VERSION ""

NS_ :

BS_:

BU_: AC_KanBox DRS_MM5_10 NotUsed HYS_EX ABS_M5 DDU10 BCM BSM CDCM DCTM DIAG_TEST ECM IONM IPC ORC RFHM TBM
VAL_TABLE_ ABS_fault_info 2 "active faults stored" 1 "inactive faults stored" 0 "no faults stored" ;
VAL_TABLE_ AC_Mode 170 "HVAC_system" 10 "HV_system" 0 "UnrecognizedCommand" ;
VAL_TABLE_ VT_ACAutoManu 3 "Not available" 2 "AutoMode" 1 "Manual Mode" 0 "UnknownState" ;
VAL_TABLE_ Vt_AC_State 3 "Not available" 2 "ON" 1 "OFF" 0 "Unknown state" ;
VAL_TABLE_ HYS_errCod 3 "SBC over temperature" 2 "CMC over temperature" 1 "No Error" 0 "Diagnosis Not Executed" ;

BO_ 3221225472 VECTOR__INDEPENDENT_SIG_MSG: 0 Vector__XXX
 SG_ ABS_Malfunction : 0|1@1+ (1,0) [0|1] "" Vector__XXX
 SG_ Appl_ld : 0|8@1+ (1,0) [0|255] "ASCII" Vector__XXX
 SG_ acc_FA_Kopie_3 : 0|8@1+ (0.05,0) [0|10] "cm³" Vector__XXX
 SG_ acc_FA_Kopie_2 : 0|8@1+ (0.05,0) [0|10] "cm³" Vector__XXX
 SG_ acc_FA_Kopie_1 : 0|8@1+ (0.05,0) [0|10] "cm³" Vector__XXX
 SG_ ValveOpening_HV : 0|16@1+ (0.00153,0) [0|100.26855] "%" Vector__XXX
 SG_ MMotRedSlow : 0|16@1+ (1,-30000) [-30000|35535] "Nm" Vector__XXX

BO_ 3 NeueBotschaft_163: 8 Vector__XXX
 SG_ NeuesSignal_1029 : 40|8@1+ (1,0) [0|0] "" Vector__XXX

BO_ 2 NeueBotschaft_162: 8 Vector__XXX
 SG_ NeuesSignal_1028 : 48|8@1+ (1,0) [0|0] "" Vector__XXX

BO_ 1 NeueBotschaft_161: 8 Vector__XXX
 SG_ NeuesSignal_1027 : 32|8@1+ (1,0) [0|0] "" Vector__XXX

BO_ 128 AC_Sync: 0 Vector__XXX

BO_ 0 AC_Start: 2 Vector__XXX

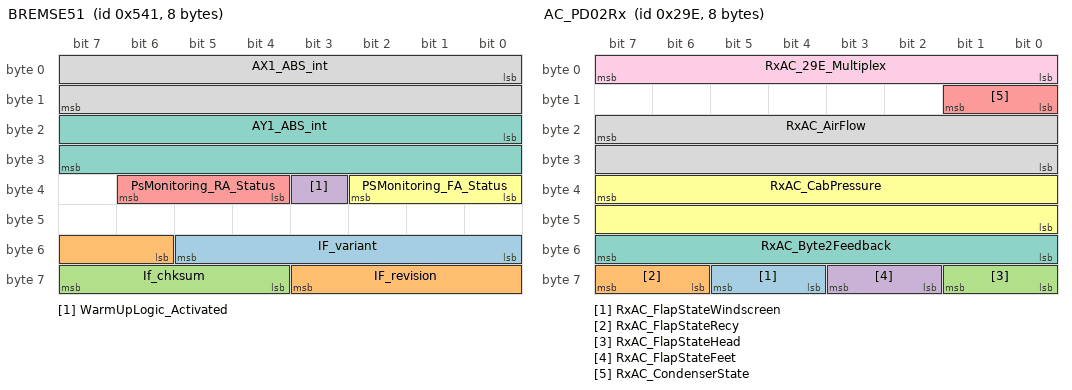
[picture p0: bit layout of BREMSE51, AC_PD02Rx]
BO_ 1345 BREMSE51: 8 ABS_M5
 SG_ IF_variant : 48|6@1+ (1,0) [0|63] "" Vector__XXX
 SG_ IF_revision : 54|6@1+ (1,0) [0|63] "" Vector__XXX
 SG_ If_chksum : 60|4@1+ (1,0) [0|15] "" Vector__XXX
 SG_ WarmUpLogic_Activated : 35|1@1+ (1,0) [0|1] "" Vector__XXX
 SG_ PsMonitoring_RA_Status : 36|3@1+ (1,0) [0|7] "" Vector__XXX
 SG_ PSMonitoring_FA_Status : 32|3@1+ (1,0) [0|7] "" Vector__XXX
 SG_ AY1_ABS_int : 16|16@1+ (0.00012742,-4.1768) [-4.1768|4.1765] "g" Vector__XXX
 SG_ AX1_ABS_int : 0|16@1+ (0.00012742,-4.1768) [-4.1768|4.1736697] "g" Vector__XXX

BO_ 1376 BREMSE50: 8 ABS_M5
 SG_ Brake_bal_pct_advice : 56|8@1+ (1,0) [0|100] "%" Vector__XXX
 SG_ Brake_bal_pct : 40|16@1+ (0.1,0) [0|100] "%" Vector__XXX
 SG_ Brake_bal_at50_advice : 32|8@1+ (1,0) [0|100] "bar" Vector__XXX
 SG_ Brake_bal_at50 : 16|16@1+ (0.1,0) [0|100] "bar" Vector__XXX
 SG_ vVeh_absRef : 0|16@1+ (0.015625,0) [0|100] "m/s" Vector__XXX

BO_ 834 BREMSE32: 8 ABS_M5
 SG_ WheelQuality_RR : 56|8@1+ (1,0) [0|32] "" Vector__XXX
 SG_ WheelQuality_RL : 48|8@1+ (1,0) [0|32] "" Vector__XXX
 SG_ WheelQuality_FR : 40|8@1+ (1,0) [0|32] "" Vector__XXX
 SG_ WheelQuality_FL : 32|8@1+ (1,0) [0|32] "" Vector__XXX
 SG_ acc_RA : 8|8@1+ (0.05,0) [0|10] "cm³" Vector__XXX
 SG_ acc_FA : 0|8@1+ (0.05,0) [0|10] "cm³" Vector__XXX

BO_ 670 AC_PD02Rx: 8 AC_KanBox
 SG_ RxAC_FlapStateWindscreen : 60|2@1+ (1,0) [0|3] ""  DDU10
 SG_ RxAC_FlapStateRecy : 62|2@1+ (1,0) [0|3] ""  DDU10
 SG_ RxAC_FlapStateHead : 56|2@1+ (1,0) [0|3] ""  DDU10
 SG_ RxAC_FlapStateFeet : 58|2@1+ (1,0) [0|3] ""  DDU10
 SG_ RxAC_CondenserState : 8|2@1+ (1,0) [0|3] ""  DDU10
 SG_ RxAC_CabPressure : 39|16@0+ (1,0) [0|65535] "Pa"  DDU10
 SG_ RxAC_Byte2Feedback : 48|8@1+ (1,0) [0|255] ""  DDU10
 SG_ RxAC_AirFlow : 23|16@0+ (1,0) [0|65535] "m³/h"  DDU10
 SG_ RxAC_29E_Multiplex : 0|8@1+ (1,0) [0|0] ""  DDU10

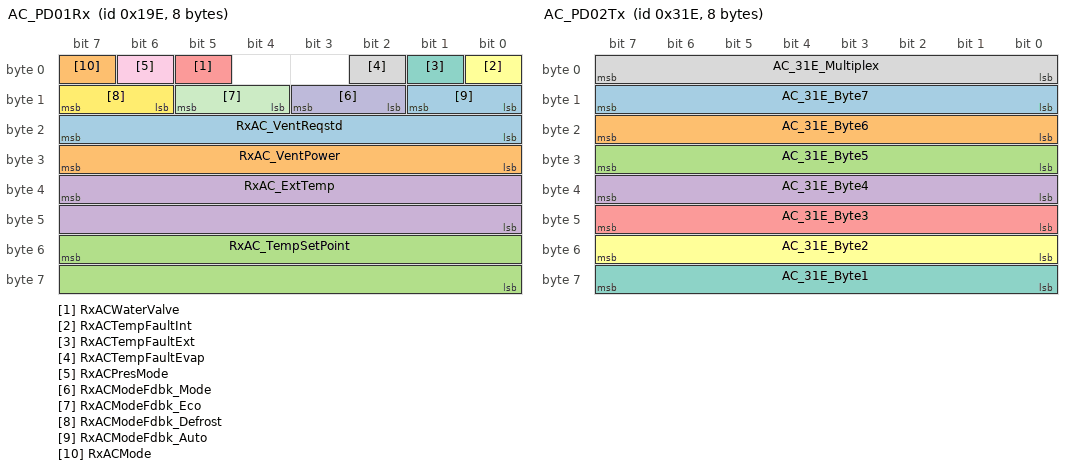
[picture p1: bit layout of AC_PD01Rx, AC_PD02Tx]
BO_ 414 AC_PD01Rx: 8 AC_KanBox
 SG_ RxAC_VentReqstd : 16|8@1+ (1,0) [0|255] ""  DDU10
 SG_ RxAC_VentPower : 24|8@1+ (1,0) [0|255] ""  DDU10
 SG_ RxAC_TempSetPoint : 55|16@0+ (0.1,-100) [-100|6453.5] ""  DDU10
 SG_ RxAC_ExtTemp : 39|16@0+ (0.1,-100) [-100|6453.5] "°C"  DDU10
 SG_ RxACWaterValve : 5|1@1+ (1,0) [0|1] ""  DDU10
 SG_ RxACTempFaultInt : 0|1@1+ (1,0) [0|1] ""  DDU10
 SG_ RxACTempFaultExt : 1|1@1+ (1,0) [0|1] ""  DDU10
 SG_ RxACTempFaultEvap : 2|1@1+ (1,0) [0|1] ""  DDU10
 SG_ RxACPresMode : 6|1@1+ (1,0) [0|1] ""  DDU10
 SG_ RxACModeFdbk_Mode : 10|2@1+ (1,0) [0|3] ""  DDU10
 SG_ RxACModeFdbk_Eco : 12|2@1+ (1,0) [0|3] ""  DDU10
 SG_ RxACModeFdbk_Defrost : 14|2@1+ (1,0) [0|3] ""  DDU10
 SG_ RxACModeFdbk_Auto : 8|2@1+ (1,0) [0|3] ""  DDU10
 SG_ RxACMode : 7|1@1+ (1,0) [0|1] ""  DDU10

BO_ 798 AC_PD02Tx: 8 DDU10
 SG_ AC_31E_Byte7 : 8|8@1+ (1,0) [0|255] ""  AC_KanBox
 SG_ AC_31E_Byte6 : 16|8@1+ (1,0) [0|255] ""  AC_KanBox
 SG_ AC_31E_Byte5 : 24|8@1+ (1,0) [0|255] ""  AC_KanBox
 SG_ AC_31E_Byte4 : 32|8@1+ (1,0) [0|255] ""  AC_KanBox
 SG_ AC_31E_Byte3 : 40|8@1+ (1,0) [0|255] ""  AC_KanBox
 SG_ AC_31E_Byte2 : 48|8@1+ (1,0) [0|255] ""  AC_KanBox
 SG_ AC_31E_Byte1 : 56|8@1+ (1,0) [0|255] ""  AC_KanBox
 SG_ AC_31E_Multiplex : 0|8@1+ (1,0) [0|255] ""  AC_KanBox

BO_ 1310 AC_ACKSD0_2: 8 AC_KanBox

BO_ 1438 AC_ACKSD0: 8 AC_KanBox

BO_ 1566 AC_SD0: 8 DDU10

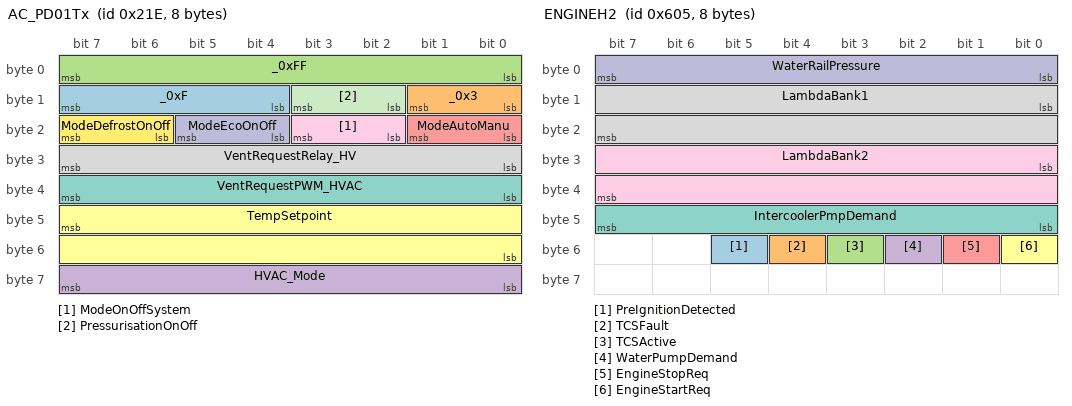
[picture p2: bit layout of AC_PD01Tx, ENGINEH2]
BO_ 542 AC_PD01Tx: 8 DDU10
 SG_ _0xF : 12|4@1+ (1,0) [0|15] ""  AC_KanBox
 SG_ _0x3 : 8|2@1+ (1,0) [0|3] ""  AC_KanBox
 SG_ _0xFF : 0|8@1+ (1,0) [0|255] ""  AC_KanBox
 SG_ HVAC_Mode : 56|8@1+ (1,0) [0|255] ""  AC_KanBox
 SG_ ModeAutoManu : 16|2@1+ (1,0) [0|3] ""  AC_KanBox
 SG_ TempSetpoint : 47|16@0+ (0.1,-100) [-100|6453.5] "°C"  AC_KanBox
 SG_ VentRequestPWM_HVAC : 32|8@1+ (1,0) [0|255] "%"  AC_KanBox
 SG_ VentRequestRelay_HV : 24|8@1+ (1,0) [0|255] ""  AC_KanBox
 SG_ ModeOnOffSystem : 18|2@1+ (1,0) [0|3] ""  AC_KanBox
 SG_ ModeEcoOnOff : 20|2@1+ (1,0) [0|3] ""  AC_KanBox
 SG_ PressurisationOnOff : 10|2@1+ (1,0) [0|3] ""  AC_KanBox
 SG_ ModeDefrostOnOff : 22|2@1+ (1,0) [0|3] ""  AC_KanBox

BO_ 1541 ENGINEH2: 8 ECM
 SG_ PreIgnitionDetected : 53|1@1+ (1,0) [0|1] "" Vector__XXX
 SG_ TCSFault : 52|1@1+ (1,0) [0|1] "" Vector__XXX
 SG_ TCSActive : 51|1@1+ (1,0) [0|1] "" Vector__XXX
 SG_ WaterPumpDemand : 50|1@1+ (1,0) [0|1] "" Vector__XXX
 SG_ EngineStopReq : 49|1@1+ (1,0) [0|1] "" Vector__XXX
 SG_ EngineStartReq : 48|1@1+ (1,0) [0|1] "" Vector__XXX
 SG_ IntercoolerPmpDemand : 40|8@1+ (0.392,0) [0|99.96] "%" Vector__XXX
 SG_ LambdaBank1 : 8|16@1+ (0.000244,0) [0|15.99054] ""  DDU10
 SG_ LambdaBank2 : 24|16@1+ (0.000244,0) [0|15.99054] ""  DDU10
 SG_ WaterRailPressure : 0|8@1+ (10,0) [0|2550] "kPa"  DDU10

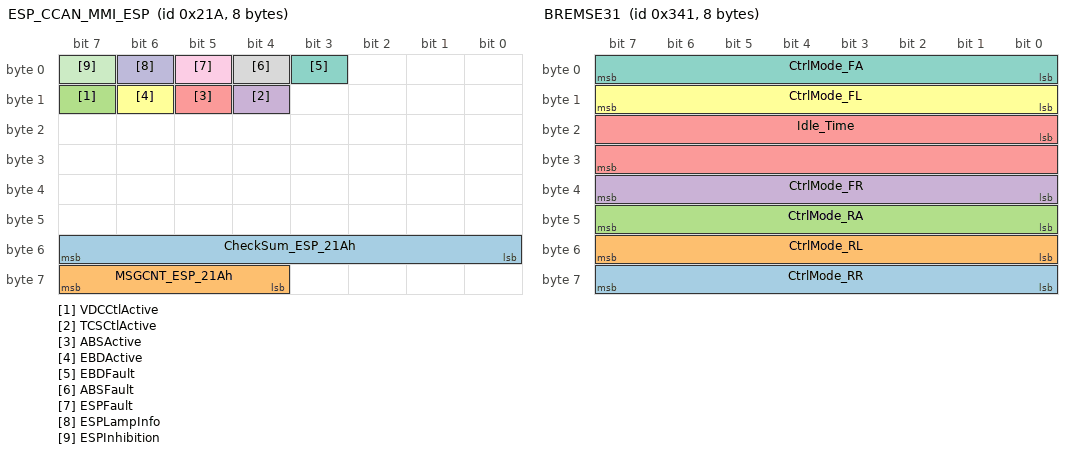
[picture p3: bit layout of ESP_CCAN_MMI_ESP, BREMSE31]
BO_ 538 ESP_CCAN_MMI_ESP: 8 ABS_M5
 SG_ CheckSum_ESP_21Ah : 55|8@0+ (1,0) [0|255] ""  ECM
 SG_ MSGCNT_ESP_21Ah : 63|4@0+ (1,0) [0|15] ""  ECM
 SG_ VDCCtlActive : 15|1@0+ (1,0) [0|1] ""  ECM
 SG_ TCSCtlActive : 12|1@0+ (1,0) [0|1] ""  ECM
 SG_ ABSActive : 13|1@0+ (1,0) [0|1] ""  ECM
 SG_ EBDActive : 14|1@0+ (1,0) [0|1] ""  ECM
 SG_ EBDFault : 3|1@0+ (1,0) [0|1] ""  ECM
 SG_ ABSFault : 4|1@0+ (1,0) [0|1] ""  ECM
 SG_ ESPFault : 5|1@0+ (1,0) [0|1] ""  ECM
 SG_ ESPLampInfo : 6|1@0+ (1,0) [0|1] ""  ECM
 SG_ ESPInhibition : 7|1@0+ (1,0) [0|1] ""  ECM

BO_ 368 DRS_RX_ID0: 8 ABS_M5

BO_ 1472 BREMSE53: 8 ABS_M5
 SG_ ABS_fault_info : 46|2@1+ (1,0) [0|3] "" Vector__XXX
 SG_ Diag_YRS : 45|1@1+ (1,0) [0|1] "" Vector__XXX
 SG_ Diag_P_RA : 44|1@1+ (1,0) [0|1] "" Vector__XXX
 SG_ Diag_P_FA : 43|1@1+ (1,0) [0|1] "" Vector__XXX
 SG_ Diag_FuseValve : 41|1@1+ (1,0) [0|1] "" Vector__XXX
 SG_ Diag_FusePump : 42|1@1+ (1,0) [0|1] "" Vector__XXX
 SG_ Diag_ABSUnit : 40|1@1+ (1,0) [0|1] "" Vector__XXX
 SG_ Diag_RR : 38|2@1+ (1,0) [0|3] "" Vector__XXX
 SG_ Diag_RL : 36|2@1+ (1,0) [0|3] "" Vector__XXX
 SG_ Diag_FR : 34|2@1+ (1,0) [0|3] "" Vector__XXX
 SG_ Diag_FL : 32|2@1+ (1,0) [0|3] "" Vector__XXX
 SG_ ABS_Lamp : 31|1@1+ (1,0) [0|1] "" Vector__XXX
 SG_ EBD_Lamp : 30|1@1+ (1,0) [0|1] "" Vector__XXX
 SG_ ABS_Active : 29|1@1+ (1,0) [0|1] "" Vector__XXX
 SG_ ABS_Malfunction : 28|1@1+ (1,0) [0|1] "" Vector__XXX
 SG_ Bremse_53_cnt : 26|2@1+ (1,0) [0|3] "" Vector__XXX
 SG_ RtaOk_Placeholder : 25|1@1+ (1,0) [0|1] "" Vector__XXX
 SG_ BLS : 24|1@1+ (1,0) [0|1] "" Vector__XXX
 SG_ SwitchPosition : 0|8@1+ (1,0) [1|12] "" Vector__XXX
 SG_ P_FA : 8|16@1- (0.01526,0) [-42.5|425] "bar" Vector__XXX
 SG_ P_RA : 48|16@1- (0.01526,0) [-42.5|425] "bar" Vector__XXX

BO_ 1346 BREMSE52: 8 ABS_M5
 SG_ BB_dig7 m2 : 56|8@1+ (1,0) [0|255] "ASCII" Vector__XXX
 SG_ Appl_Id_14 m3 : 56|8@1+ (1,0) [0|255] "ASCII" Vector__XXX
 SG_ Appl_Id_07 m4 : 56|8@1+ (1,0) [0|255] "ASCII" Vector__XXX
 SG_ SW_version_Low_lower m1 : 48|8@1+ (1,0) [0|255] "" Vector__XXX
 SG_ BB_dig6 m2 : 48|8@1- (1,0) [0|255] "ASCII" Vector__XXX
 SG_ Appl_Id_06 m3 : 48|8@1+ (1,0) [0|255] "ASCII" Vector__XXX
 SG_ Appl_Id_13 m4 : 48|8@1+ (1,0) [0|255] "ASCII" Vector__XXX
 SG_ Appl_date_06 m5 : 48|8@1+ (1,0) [0|255] "" Vector__XXX
 SG_ SW_version_Low_upper m1 : 40|8@1+ (1,0) [0|255] "" Vector__XXX
 SG_ BB_dig5 m2 : 40|8@1+ (1,0) [0|255] "ASCII" Vector__XXX
 SG_ Appl_Id_05 m3 : 40|8@1+ (1,0) [0|255] "ASCII" Vector__XXX
 SG_ Appl_Id_12 m4 : 40|8@1+ (1,0) [0|255] "ASCII" Vector__XXX
 SG_ Appl_date_05 m5 : 40|8@1+ (1,0) [0|59] "" Vector__XXX
 SG_ SW_version_Mid_lower m1 : 32|8@1+ (1,0) [0|255] "" Vector__XXX
 SG_ BB_dig4 m2 : 32|8@1+ (1,0) [0|255] "ASCII" Vector__XXX
 SG_ Appl_Id_04 m3 : 32|8@1+ (1,0) [0|255] "ASCII" Vector__XXX
 SG_ Appl_Id_11 m4 : 32|8@1+ (1,0) [0|255] "ASCII" Vector__XXX
 SG_ Appl_date_04 m5 : 32|8@1+ (1,0) [0|24] "" Vector__XXX
 SG_ Ecu_serial m7 : 32|8@1+ (1,0) [0|9999] "" Vector__XXX
 SG_ Appl_Id_03 m3 : 24|8@1+ (1,0) [0|255] "ASCII" Vector__XXX
 SG_ SW_version_Mid_upper m1 : 24|8@1+ (1,0) [0|255] "" Vector__XXX
 SG_ BB_dig3 m2 : 24|8@1+ (1,0) [0|255] "ASCII" Vector__XXX
 SG_ Appl_Id_10 m4 : 24|8@1+ (1,0) [0|255] "ASCII" Vector__XXX
 SG_ Appl_date_03 m5 : 24|8@1+ (1,0) [1|31] "" Vector__XXX
 SG_ HU_date_day m7 : 24|8@1+ (1,0) [1|31] "" Vector__XXX
 SG_ SW_version_High_lower m1 : 16|8@1+ (1,0) [0|255] "" Vector__XXX
 SG_ BB_dig2 m2 : 16|8@1+ (1,0) [0|255] "ASCII" Vector__XXX
 SG_ Appl_Id_02 m3 : 16|8@1+ (1,0) [0|255] "ASCII" Vector__XXX
 SG_ Appl_Id_09 m4 : 16|8@1+ (1,0) [0|255] "ASCII" Vector__XXX
 SG_ Appl_date_02 m5 : 16|8@1+ (1,0) [1|12] "" Vector__XXX
 SG_ HU_date_month m7 : 16|8@1+ (1,0) [1|12] "" Vector__XXX
 SG_ SW_version_High_upper m1 : 8|8@1+ (1,0) [0|255] "" Vector__XXX
 SG_ BB_dig1 m2 : 8|8@1+ (1,0) [0|255] "ASCII" Vector__XXX
 SG_ Appl_Id_01 m3 : 8|8@1+ (1,0) [0|255] "ASCII" Vector__XXX
 SG_ Apple_Id_08 m4 : 8|8@1+ (1,0) [0|255] "ASCII" Vector__XXX
 SG_ SW_CAN_ident m6 : 8|8@1+ (1,0) [0|255] "" Vector__XXX
 SG_ HU_date_year m7 : 8|8@1+ (1,0) [0|99] "" Vector__XXX
 SG_ Appl_date_01 m5 : 8|8@1+ (1,0) [0|99] "" Vector__XXX
 SG_ Mplx_SW_Info M : 0|8@1+ (1,0) [0|255] "" Vector__XXX

BO_ 833 BREMSE31: 8 ABS_M5
 SG_ CtrlMode_RR : 56|8@1+ (1,0) [0|0] "" Vector__XXX
 SG_ CtrlMode_RL : 48|8@1+ (1,0) [0|0] "" Vector__XXX
 SG_ CtrlMode_RA : 40|8@1+ (1,0) [0|0] "" Vector__XXX
 SG_ CtrlMode_FR : 32|8@1+ (1,0) [0|0] "" Vector__XXX
 SG_ Idle_Time : 16|16@1+ (1,0) [0|0] "-" Vector__XXX
 SG_ CtrlMode_FL : 8|8@1+ (1,0) [0|0] "" Vector__XXX
 SG_ CtrlMode_FA : 0|8@1+ (1,0) [0|0] "" Vector__XXX

BO_ 832 BREMSE30: 8 ABS_M5
 SG_ Slip_RR : 48|16@1- (0.000976562,0) [-5|1] "%" Vector__XXX
 SG_ Slip_RL : 32|16@1- (0.000976562,0) [-5|1] "%" Vector__XXX
 SG_ Slip_FR : 16|16@1- (0.000976562,0) [-5|1] "%" Vector__XXX
 SG_ Slip_FL : 0|16@1- (0.000976562,0) [-5|1] "%" Vector__XXX

BO_ 323 BREMSE13: 8 ABS_M5
 SG_ WhlDecel_FRR : 48|16@1- (0.0625,0) [-250|250] "m/s²" Vector__XXX
 SG_ WhlDecel_FRL : 32|16@1- (0.0625,0) [-250|250] "m/s²" Vector__XXX
 SG_ WhlDecel_FFR : 16|16@1- (0.0625,0) [-250|250] "m/s²" Vector__XXX
 SG_ WhlDecel_FFL : 0|16@1- (0.0625,0) [-250|250] "m/s²" Vector__XXX

BO_ 322 BREMSE12: 8 ABS_M5
 SG_ WhlDecel_RR : 48|16@1- (0.0625,0) [-250|250] "m/s²" Vector__XXX
 SG_ WhlDecel_RL : 32|16@1- (0.0625,0) [-250|250] "m/s²" Vector__XXX
 SG_ WhlDecel_FR : 16|16@1- (0.0625,0) [-250|250] "m/s²" Vector__XXX
 SG_ WhlDecel_FL : 0|16@1- (0.0625,0) [-250|250] "m/s²" Vector__XXX

BO_ 321 BREMSE11: 8 ABS_M5
 SG_ P_Target_RR : 48|16@1- (0.03125,0) [-20|400] "bar" Vector__XXX
 SG_ P_Target_LR : 16|16@1- (0.03125,0) [-20|400] "bar" Vector__XXX
 SG_ P_Model_RR : 32|16@1- (0.03125,0) [-20|400] "bar" Vector__XXX
 SG_ P_Model_LR : 0|16@1- (0.03125,0) [-20|400] "bar" Vector__XXX

BO_ 320 BREMSE10: 8 ABS_M5
 SG_ P_Target_FR : 48|16@1- (0.03125,0) [-20|400] "bar" Vector__XXX
 SG_ P_Model_FR : 32|16@1- (0.03125,0) [-20|400] "bar" Vector__XXX
 SG_ P_Target_FL : 16|16@1- (0.03125,0) [-20|400] "bar" Vector__XXX
 SG_ P_Model_FL : 0|16@1- (0.03125,0) [-20|400] "bar" Vector__XXX

BO_ 1029 BCM_h_VInfo: 8 ABS_M5

BO_ 200 BCM_h_FrP01: 8 ABS_M5

BO_ 16 SASM_h_FrP00: 8 Vector__XXX

BO_ 1312 BCM_Status_V4: 8 DDU10

BO_ 588 ABS_Switch: 8 DDU10
 SG_ ABS_Switchposition : 0|8@1+ (1,0) [0|11] ""  ABS_M5

BO_ 380 MM5_10_TX3: 8 DRS_MM5_10
 SG_ AZ : 32|16@1+ (0.000127465,-4.1768) [-4.1768|4.176618775] "" Vector__XXX
 SG_ AZ_STAT : 52|4@1+ (1,0) [0|15] "" Vector__XXX
 SG_ CRC_TX3 : 56|8@1+ (1,0) [0|255] "" Vector__XXX
 SG_ MSG_CNT_TX3 : 48|4@1+ (1,0) [0|15] "" Vector__XXX

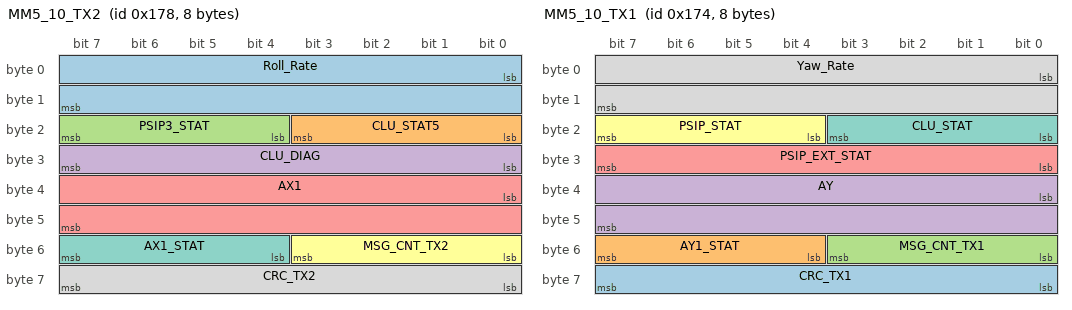
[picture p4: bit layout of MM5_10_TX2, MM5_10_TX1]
BO_ 376 MM5_10_TX2: 8 DRS_MM5_10
 SG_ Roll_Rate : 0|16@1+ (0.005,-163.84) [-163.84|163.835] "°/s" Vector__XXX
 SG_ CLU_STAT5 : 16|4@1+ (1,0) [0|15] "" Vector__XXX
 SG_ PSIP3_STAT : 20|4@1+ (1,0) [0|15] "" Vector__XXX
 SG_ CLU_DIAG : 24|8@1+ (1,0) [0|255] "" Vector__XXX
 SG_ AX1 : 32|16@1+ (0.000127465,-4.1768) [0|0] "g" Vector__XXX
 SG_ MSG_CNT_TX2 : 48|4@1+ (1,0) [0|15] "" Vector__XXX
 SG_ AX1_STAT : 52|4@1+ (1,0) [0|15] "" Vector__XXX
 SG_ CRC_TX2 : 56|8@1+ (1,0) [0|255] "" Vector__XXX

BO_ 372 MM5_10_TX1: 8 DRS_MM5_10
 SG_ CRC_TX1 : 56|8@1+ (1,0) [0|255] "" Vector__XXX
 SG_ AY1_STAT : 52|4@1+ (1,0) [0|15] "" Vector__XXX
 SG_ MSG_CNT_TX1 : 48|4@1+ (1,0) [0|15] "" Vector__XXX
 SG_ AY : 32|16@1+ (0.000127465,-4.1768) [-4.1768|4.176618775] "g" Vector__XXX
 SG_ PSIP_EXT_STAT : 24|8@1+ (1,0) [0|255] "" Vector__XXX
 SG_ PSIP_STAT : 20|4@1+ (1,0) [0|15] "" Vector__XXX
 SG_ CLU_STAT : 16|4@1+ (1,0) [0|15] "" Vector__XXX
 SG_ Yaw_Rate : 0|16@1+ (0.005,-163.84) [-163.84|163.835] "°/s" Vector__XXX

BO_ 1568 PWT_CCAN_STATUS_V4: 8 ECM
 SG_ CheckSum_PWT_620h : 55|8@0+ (1,0) [0|255] ""  ABS_M5
 SG_ MSGCNT_PWT_620h : 63|4@0+ (1,0) [0|15] ""  ABS_M5
 SG_ PWT_Status : 47|8@0+ (1,0) [0|255] ""  ABS_M5
 SG_ MovingDirection : 3|4@0+ (1,0) [0|15] ""  ABS_M5

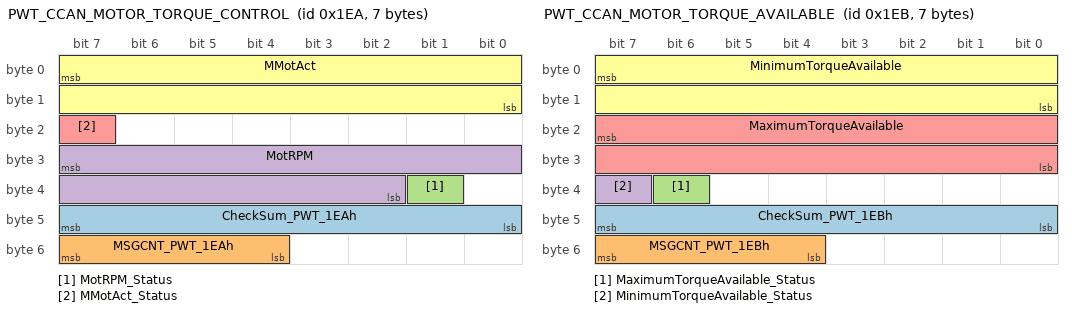
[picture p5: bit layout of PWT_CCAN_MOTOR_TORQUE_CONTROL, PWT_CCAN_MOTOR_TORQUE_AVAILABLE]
BO_ 490 PWT_CCAN_MOTOR_TORQUE_CONTROL: 7 ECM
 SG_ CheckSum_PWT_1EAh : 47|8@0+ (1,0) [0|255] ""  ABS_M5
 SG_ MSGCNT_PWT_1EAh : 55|4@0+ (1,0) [0|15] ""  ABS_M5
 SG_ MotRPM_Status : 33|1@0+ (1,0) [0|1] ""  ABS_M5
 SG_ MotRPM : 31|14@0+ (1,0) [0|16383] "rpm"  ABS_M5
 SG_ MMotAct_Status : 23|1@0+ (1,0) [0|1] ""  ABS_M5
 SG_ MMotAct : 7|16@0+ (1,-30000) [-30000|35535] "Nm"  ABS_M5

BO_ 491 PWT_CCAN_MOTOR_TORQUE_AVAILABLE: 7 ECM
 SG_ CheckSum_PWT_1EBh : 47|8@0+ (1,0) [0|255] ""  ABS_M5
 SG_ MSGCNT_PWT_1EBh : 55|4@0+ (1,0) [0|15] ""  ABS_M5
 SG_ MaximumTorqueAvailable_Status : 38|1@0+ (1,0) [0|1] ""  ABS_M5
 SG_ MinimumTorqueAvailable_Status : 39|1@0+ (1,0) [0|1] ""  ABS_M5
 SG_ MaximumTorqueAvailable : 23|16@0+ (1,-30000) [-30000|35535] "Nm"  ABS_M5
 SG_ MinimumTorqueAvailable : 7|16@0+ (1,-30000) [-30000|35535] "Nm"  ABS_M5

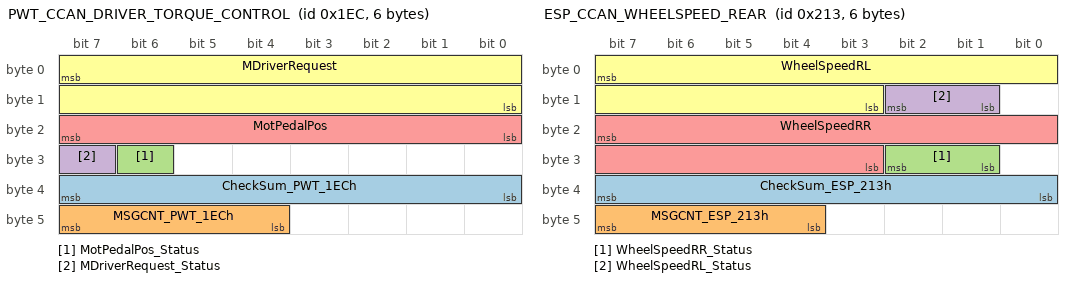
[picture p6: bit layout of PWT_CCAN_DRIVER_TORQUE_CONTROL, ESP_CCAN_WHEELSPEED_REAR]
BO_ 492 PWT_CCAN_DRIVER_TORQUE_CONTROL: 6 ECM
 SG_ CheckSum_PWT_1ECh : 39|8@0+ (1,0) [0|255] ""  ABS_M5
 SG_ MSGCNT_PWT_1ECh : 47|4@0+ (1,0) [0|15] ""  ABS_M5
 SG_ MotPedalPos_Status : 30|1@0+ (1,0) [0|1] ""  ABS_M5
 SG_ MDriverRequest_Status : 31|1@0+ (1,0) [0|1] ""  ABS_M5
 SG_ MotPedalPos : 23|8@0+ (0.3937,0) [0|100.3935] "%"  ABS_M5
 SG_ MDriverRequest : 7|16@0+ (1,-30000) [-30000|35535] ""  ABS_M5

BO_ 531 ESP_CCAN_WHEELSPEED_REAR: 6 ABS_M5
 SG_ CheckSum_ESP_213h : 39|8@0+ (1,0) [0|255] ""  ECM,DDU10
 SG_ MSGCNT_ESP_213h : 47|4@0+ (1,0) [0|15] ""  ECM,DDU10
 SG_ WheelSpeedRR_Status : 26|2@0+ (1,0) [0|3] ""  ECM,DDU10
 SG_ WheelSpeedRL_Status : 10|2@0+ (1,0) [0|3] ""  ECM,DDU10
 SG_ WheelSpeedRR : 23|13@0+ (0.05625,0) [0|460.74375] "km/h"  ECM,DDU10
 SG_ WheelSpeedRL : 7|13@0+ (0.05625,0) [0|460.74375] "km/h"  ECM,DDU10

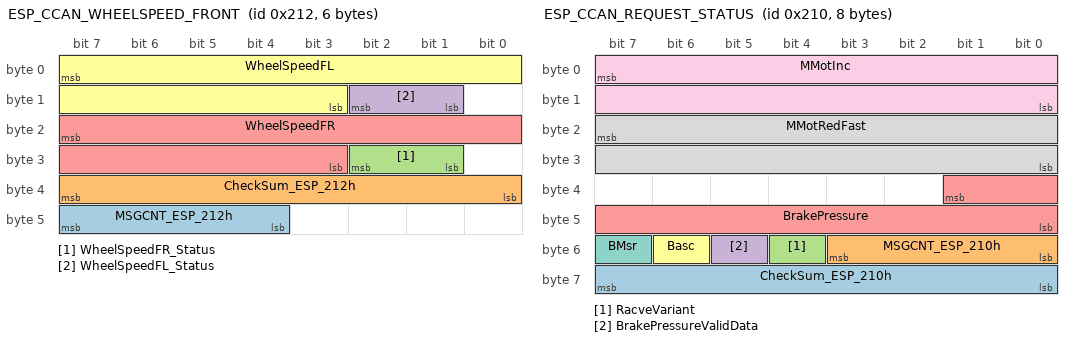
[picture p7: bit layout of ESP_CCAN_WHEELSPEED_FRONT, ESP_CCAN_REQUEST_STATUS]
BO_ 530 ESP_CCAN_WHEELSPEED_FRONT: 6 ABS_M5
 SG_ MSGCNT_ESP_212h : 47|4@0+ (1,0) [0|15] ""  ECM,DDU10
 SG_ CheckSum_ESP_212h : 39|8@0+ (1,0) [0|255] ""  ECM,DDU10
 SG_ WheelSpeedFR_Status : 26|2@0+ (1,0) [0|3] ""  ECM,DDU10
 SG_ WheelSpeedFL_Status : 10|2@0+ (1,0) [0|3] ""  ECM,DDU10
 SG_ WheelSpeedFR : 23|13@0+ (0.05625,0) [0|460.74375] "km/h"  ECM,DDU10
 SG_ WheelSpeedFL : 7|13@0+ (0.05625,0) [0|460.74375] "km/h"  ECM,DDU10

BO_ 528 ESP_CCAN_REQUEST_STATUS: 8 ABS_M5
 SG_ CheckSum_ESP_210h : 63|8@0+ (1,0) [0|255] ""  ECM,DDU10
 SG_ MSGCNT_ESP_210h : 51|4@0+ (1,0) [0|15] ""  ECM,DDU10
 SG_ RacveVariant : 52|1@0+ (1,0) [0|1] ""  ECM,DDU10
 SG_ BrakePressureValidData : 53|1@0+ (1,0) [0|1] ""  ECM,DDU10
 SG_ BrakePressure : 33|10@0+ (0.25,0) [0|255.75] "bar"  ECM,DDU10
 SG_ Basc : 54|1@0+ (1,0) [0|1] ""  ECM,DDU10
 SG_ BMsr : 55|1@0+ (1,0) [0|1] ""  ECM,DDU10
 SG_ MMotRedFast : 23|16@0+ (1,-30000) [-30000|35535] "Nm"  ECM,DDU10
 SG_ MMotInc : 7|16@0+ (1,-30000) [-30000|35535] "Nm"  ECM,DDU10

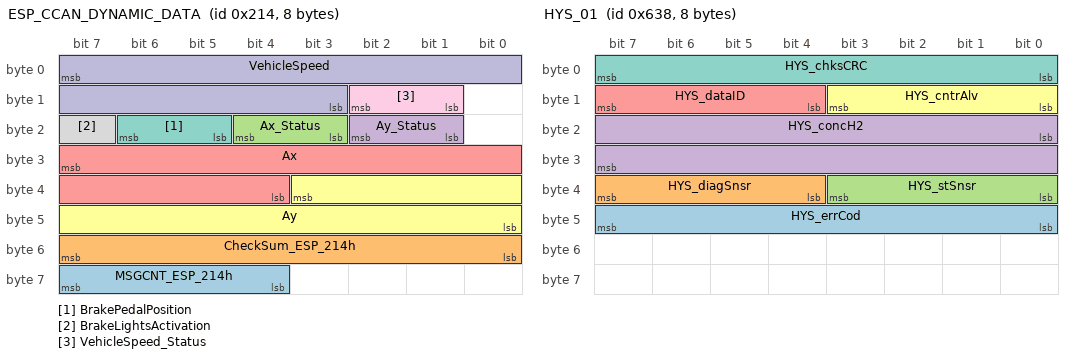
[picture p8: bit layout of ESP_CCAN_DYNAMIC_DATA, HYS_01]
BO_ 532 ESP_CCAN_DYNAMIC_DATA: 8 ABS_M5
 SG_ MSGCNT_ESP_214h : 63|4@0+ (1,0) [0|15] ""  ECM,DDU10
 SG_ CheckSum_ESP_214h : 55|8@0+ (1,0) [0|255] ""  ECM,DDU10
 SG_ Ax_Status : 20|2@0+ (1,0) [0|3] ""  ECM,DDU10
 SG_ Ay_Status : 18|2@0+ (1,0) [0|3] ""  ECM,DDU10
 SG_ Ax : 31|12@0+ (0.02,-40.96) [-40.96|40.94] "m/s^2"  ECM,DDU10
 SG_ Ay : 35|12@0+ (0.02,-40.96) [-40.96|40.94] "m/s^2"  ECM,DDU10
 SG_ BrakePedalPosition : 22|2@0+ (1,0) [0|3] ""  ECM,DDU10
 SG_ BrakeLightsActivation : 23|1@0+ (1,0) [0|1] ""  ECM,DDU10
 SG_ VehicleSpeed_Status : 10|2@0+ (1,0) [0|3] ""  ECM,DDU10
 SG_ VehicleSpeed : 7|13@0+ (0.05625,0) [0|460.74375] "km/h"  ECM,DDU10

BO_ 1593 HYS_02: 8 HYS_EX
 SG_ HYS_02_Multiplexer : 0|8@1+ (1,0) [0|255] ""  DDU10

BO_ 1592 HYS_01: 8 HYS_EX
 SG_ HYS_errCod : 40|8@1+ (1,0) [0|255] ""  DDU10
 SG_ HYS_diagSnsr : 36|4@1+ (1,0) [0|15] ""  DDU10
 SG_ HYS_stSnsr : 32|4@1+ (1,0) [0|15] ""  DDU10
 SG_ HYS_concH2 : 16|16@1+ (0.0004,-1) [-1|25.214] "%"  DDU10
 SG_ HYS_dataID : 12|4@1+ (1,0) [0|15] ""  DDU10
 SG_ HYS_cntrAlv : 8|4@1+ (1,0) [0|15] ""  DDU10
 SG_ HYS_chksCRC : 0|8@1+ (1,0) [0|255] ""  DDU10

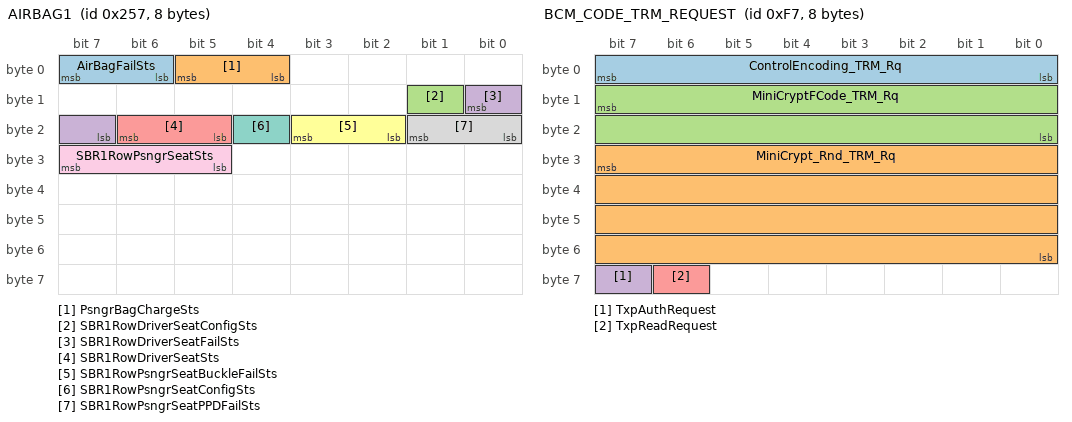
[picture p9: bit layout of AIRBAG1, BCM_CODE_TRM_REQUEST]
BO_ 599 AIRBAG1: 8 ORC
 SG_ AirBagFailSts : 7|2@0+ (1,0) [0|3] "-"  IPC,TBM
 SG_ PsngrBagChargeSts : 5|2@0+ (1,0) [0|2] "-"  IPC
 SG_ SBR1RowDriverSeatConfigSts : 9|1@0+ (1,0) [0|1] "-"  BSM,IPC
 SG_ SBR1RowDriverSeatFailSts : 8|2@0+ (1,0) [0|2] ""  BSM,IPC
 SG_ SBR1RowDriverSeatSts : 22|2@0+ (1,0) [0|2] "-"  BSM,IPC,TBM
 SG_ SBR1RowPsngrSeatBuckleFailSts : 19|2@0+ (1,0) [0|2] ""  IPC
 SG_ SBR1RowPsngrSeatConfigSts : 20|1@0+ (1,0) [0|1] "-"  IPC
 SG_ SBR1RowPsngrSeatPPDFailSts : 17|2@0+ (1,0) [0|2] ""  IPC
 SG_ SBR1RowPsngrSeatSts : 31|3@0+ (1,0) [0|6] "-"  BCM,IPC,TBM

BO_ 1447 AIRBAG2: 8 DDU10
 SG_ CRC_A2 : 63|8@0+ (1,0) [0|255] ""  BSM,DCTM,ECM
 SG_ DrvSbltUnFltr : 7|3@0+ (1,0) [0|6] ""  BSM,DCTM,ECM
 SG_ MessageCounter_A2 : 51|4@0+ (1,0) [0|15] ""  BSM,DCTM,ECM

BO_ 1050 BATTERY_INFO: 7 DDU10
 SG_ BatteryVoltageLevelHP : 7|9@0+ (0.025,4) [4|16.775] "Volt"  ORC
 SG_ BCMSAMFailSts : 51|1@0+ (1,0) [0|1] "-"  ECM
 SG_ VoltageMax : 31|8@0+ (0.025,10.6) [10.6|16.975] "Volt"  ECM
 SG_ VoltageMin : 23|8@0+ (0.025,10.6) [10.6|16.975] "Volt"  ECM

BO_ 247 BCM_CODE_TRM_REQUEST: 8 NotUsed
 SG_ ControlEncoding_TRM_Rq : 7|8@0+ (1,0) [0|255] "-"  RFHM
 SG_ MiniCrypt_Rnd_TRM_Rq : 31|32@0+ (1,0) [0|4294967295] "-"  RFHM
 SG_ MiniCryptFCode_TRM_Rq : 15|16@0+ (1,0) [0|65535] "-"  RFHM
 SG_ TxpAuthRequest : 63|1@0+ (1,0) [0|1] "-"  RFHM
 SG_ TxpReadRequest : 62|1@0+ (1,0) [0|1] "-"  RFHM

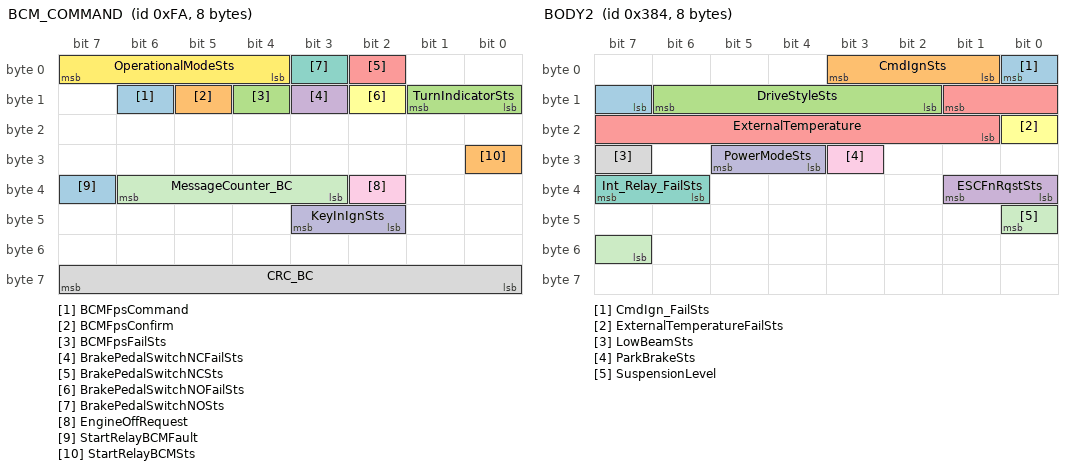
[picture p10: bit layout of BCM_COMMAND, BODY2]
BO_ 250 BCM_COMMAND: 8 ECM
 SG_ BCMFpsCommand : 14|1@0+ (1,0) [0|1] "-"  ECM
 SG_ BCMFpsConfirm : 13|1@0+ (1,0) [0|1] "-"  ECM
 SG_ BCMFpsFailSts : 12|1@0+ (1,0) [0|1] "-"  ECM
 SG_ BrakePedalSwitchNCFailSts : 11|1@0+ (1,0) [0|1] "-" Vector__XXX
 SG_ BrakePedalSwitchNCSts : 2|1@0+ (1,0) [0|1] "-" Vector__XXX
 SG_ BrakePedalSwitchNOFailSts : 10|1@0+ (1,0) [0|1] "-"  TBM
 SG_ BrakePedalSwitchNOSts : 3|1@0+ (1,0) [0|1] "-" Vector__XXX
 SG_ CRC_BC : 63|8@0+ (1,0) [0|255] ""  DCTM,ECM,RFHM
 SG_ EngineOffRequest : 34|1@0+ (1,0) [0|1] "-"  ECM
 SG_ KeyInIgnSts : 43|2@0+ (1,0) [0|2] ""  RFHM,TBM
 SG_ MessageCounter_BC : 38|4@0+ (1,0) [0|15] "-"  DCTM,ECM,RFHM
 SG_ OperationalModeSts : 7|4@0+ (1,0) [0|15] ""  DCTM,ECM,IONM,IPC,RFHM
 SG_ StartRelayBCMFault : 39|1@0+ (1,0) [0|1] ""  ECM
 SG_ StartRelayBCMSts : 24|1@0+ (1,0) [0|1] ""  ECM
 SG_ TurnIndicatorSts : 9|2@0+ (1,0) [0|3] "-"  ORC,TBM

BO_ 1994 BCM_IGNITION_ON_COUNTER: 2 DDU10
 SG_ IgnitionOnCounter : 7|16@0+ (1,0) [0|65535] "-"  DCTM,ECM,IPC,RFHM

BO_ 245 BCM_MINICRYPT_ACK: 1 NotUsed
 SG_ MinicryptReceptionSts : 7|1@0+ (1,0) [0|1] "-"  RFHM

BO_ 1446 BH_IGW1: 8 BCM
 SG_ A2D_DRV_TEMP_DR_POS : 39|10@0+ (0.0048828125,0) [0|4.9951171875] "Volt"  ECM
 SG_ A2D_FT_HVAC_BLOWER_VOLTAGE : 17|10@0+ (0.0048828125,0) [0|4.9951171875] "Volt"  ECM
 SG_ AcOutputCurrentSts : 11|8@0+ (0.008,0) [0|2.04] "A"  ECM
 SG_ StopStartClimateInfo : 43|3@0+ (1,0) [0|5] "-"  ECM

BO_ 748 BODY1: 8 DDU10
 SG_ FrontWiperMoveSts : 21|1@0+ (1,0) [0|1] ""  ECM,TBM
 SG_ RemStartActiveEPB : 20|1@0+ (1,0) [0|1] ""  BSM

BO_ 900 BODY2: 8 DDU10
 SG_ CmdIgn_FailSts : 0|2@0+ (1,0) [0|3] ""  CDCM,DCTM,ECM,IONM,IPC,RFHM
 SG_ CmdIgnSts : 3|3@0+ (1,0) [0|7] ""  CDCM,DCTM,ECM,IONM,IPC,RFHM,TBM
 SG_ DriveStyleSts : 14|5@0+ (1,0) [0|31] "-"  CDCM,DCTM,ECM,IPC,TBM
 SG_ ESCFnRqstSts : 33|2@0+ (1,0) [0|2] "" Vector__XXX
 SG_ ExternalTemperature : 9|9@0+ (0.5,-85) [-85|170] "°C"  CDCM,DCTM,ECM,RFHM
 SG_ ExternalTemperatureFailSts : 16|1@0+ (1,0) [0|1] ""  CDCM,DCTM,ECM,RFHM
 SG_ Int_Relay_FailSts : 39|2@0+ (1,0) [0|2] "" Vector__XXX
 SG_ LowBeamSts : 31|1@0+ (1,0) [0|1] ""  ORC,TBM
 SG_ ParkBrakeSts : 27|1@0+ (1,0) [0|1] "-"  ECM,TBM
 SG_ PowerModeSts : 29|2@0+ (1,0) [0|3] "-"  ECM,IPC,RFHM
 SG_ SuspensionLevel : 40|2@0+ (1,0) [0|1] "-"  CDCM

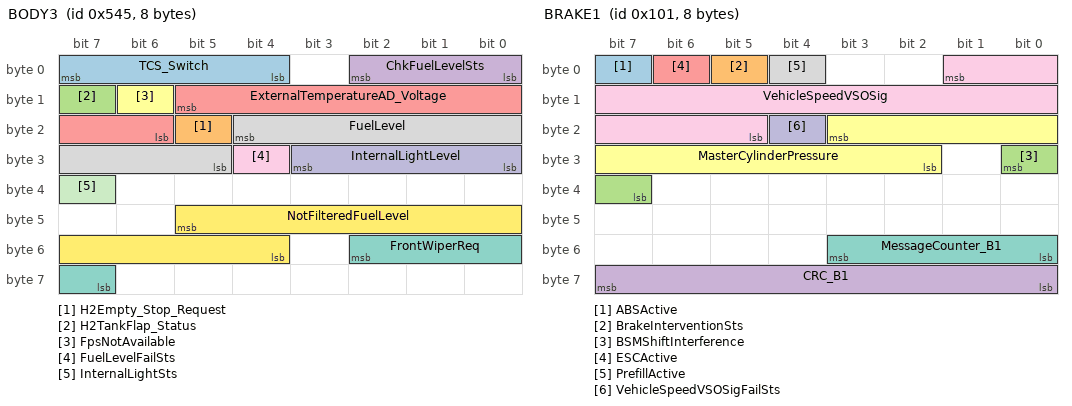
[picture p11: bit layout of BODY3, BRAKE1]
BO_ 1349 BODY3: 8 DDU10
 SG_ TCS_Switch : 4|4@1+ (1,0) [0|15] "" Vector__XXX
 SG_ H2Empty_Stop_Request : 21|1@1+ (1,0) [0|1] ""  ECM
 SG_ H2TankFlap_Status : 15|1@1+ (1,0) [0|1] ""  ECM
 SG_ ChkFuelLevelSts : 2|3@0+ (1,0) [0|7] "-"  ECM
 SG_ ExternalTemperatureAD_Voltage : 13|8@0+ (0.019607843,0) [0|4.9999992] "Volt"  ECM
 SG_ FpsNotAvailable : 14|1@0+ (1,0) [0|1] ""  IPC
 SG_ FrontWiperReq : 50|4@0+ (1,0) [0|3] ""  BSM,CDCM,TBM
 SG_ FuelLevel : 20|8@0+ (1,0) [0|255] "%"  ECM,IPC,ORC,TBM
 SG_ FuelLevelFailSts : 28|1@0+ (1,0) [0|1] ""  ECM,IPC
 SG_ InternalLightLevel : 27|4@0+ (1,0) [0|15] "-"  IPC,RFHM,TBM
 SG_ InternalLightSts : 39|1@0+ (1,0) [0|1] "-"  BSM,IPC,ORC,RFHM,TBM
 SG_ NotFilteredFuelLevel : 45|10@0+ (2,0) [0|835.7] "Ohm"  ECM

BO_ 1201 BODY4: 8 DDU10
 SG_ BonnetFailSts : 5|1@0+ (1,0) [0|1] "-" Vector__XXX
 SG_ BonnetSts : 4|1@0+ (1,0) [0|1] ""  RFHM,TBM
 SG_ CompressorACReqSts : 37|1@0+ (1,0) [0|1] "-"  ECM
 SG_ DriverDoorFailSts : 3|1@0+ (1,0) [0|1] "-" Vector__XXX
 SG_ DriverDoorSts : 0|1@0+ (1,0) [0|1] ""  BSM,IPC,RFHM,TBM
 SG_ ExteriorRearReleaseSwitchSts : 33|1@0+ (1,0) [0|1] ""  RFHM,TBM
 SG_ FOBSearchRequest : 2|2@0+ (1,0) [0|3] ""  RFHM
 SG_ LHRDoorSts : 14|1@0+ (1,0) [0|1] "-"  RFHM,TBM
 SG_ LockUnlockVehicle : 51|2@0+ (1,0) [0|3] ""  RFHM
 SG_ PsngrDoorSts : 15|1@0+ (1,0) [0|1] "-"  RFHM,TBM
 SG_ RemSt_InhibitSts : 19|6@0+ (1,0) [0|62] ""  IPC,TBM
 SG_ RemStActvSts : 29|1@0+ (1,0) [0|1] ""  DCTM,ECM,IPC,ORC,RFHM,TBM
 SG_ RHatchSts : 12|1@0+ (1,0) [0|1] "-"  RFHM,TBM
 SG_ RHRDoorSts : 13|1@0+ (1,0) [0|1] "-"  RFHM,TBM
 SG_ SpSt_Pad1 : 45|3@0+ (1,0) [0|7] ""  ECM,TBM
 SG_ SpSt_Pad2 : 42|3@0+ (1,0) [0|7] ""  ECM,TBM
 SG_ SteeringWheelButton2Sts : 61|1@0+ (1,0) [0|1] ""  DCTM
 SG_ TheftAlarmStatus : 22|3@0+ (1,0) [0|6] ""  RFHM,TBM

BO_ 1049 BODY7: 8 NotUsed
 SG_ BonnetAjarRawValSts : 31|4@0+ (1,0) [0|15] ""  ECM
 SG_ FUEL_VOLT : 7|8@0+ (0.019607843,0) [0|4.98] "Volt"  ECM
 SG_ FUEL_VOLT2 : 15|8@0+ (0.019607843,0) [0|4.98] "Volt"  ECM
 SG_ RHatchAjarRawValSts : 33|4@0+ (1,0) [0|15] ""  ECM

BO_ 257 BRAKE1: 8 DDU10
 SG_ ABSActive : 7|1@0+ (1,0) [0|1] ""  DCTM,ECM,IPC,ORC,TBM
 SG_ BrakeInterventionSts : 5|1@0+ (1,0) [0|1] ""  DCTM,ECM,ORC
 SG_ BSMShiftInterference : 24|2@0+ (1,0) [0|2] ""  DCTM
 SG_ CRC_B1 : 63|8@0+ (1,0) [0|255] ""  BCM,CDCM,DCTM,ECM,RFHM
 SG_ ESCActive : 6|1@0+ (1,0) [0|1] ""  CDCM,DCTM,ECM,ORC
 SG_ MasterCylinderPressure : 19|10@0+ (0.25,0) [0|255.5] "bar"  CDCM,DCTM,ECM,IPC,ORC
 SG_ MessageCounter_B1 : 51|4@0+ (1,0) [0|15] ""  BCM,CDCM,DCTM,ECM,RFHM
 SG_ PrefillActive : 4|1@0+ (1,0) [0|1] ""  ORC
 SG_ VehicleSpeedVSOSig : 1|13@0+ (0.0625,0) [0|511.875] "Km/h"  BCM,DCTM,ECM,IPC,ORC,RFHM,TBM
 SG_ VehicleSpeedVSOSigFailSts : 20|1@0+ (1,0) [0|1] ""  BCM,DCTM,ECM,IPC,ORC,RFHM,TBM

BO_ 506 BRAKE10: 8 NotUsed
 SG_ BrkPrss_One : 7|10@0+ (0.00488,0) [0|4.995] "V"  ECM
 SG_ HSA_BrkPrss : 31|10@0+ (0.25,0) [0|255.75] "bar" Vector__XXX
 SG_ HSA_BrkPrssFailSts : 16|1@0+ (1,0) [0|1] "" Vector__XXX

BO_ 263 BRAKE11: 8 DDU10
 SG_ Bleeding_Warning : 55|1@0+ (1,0) [0|1] ""  IPC
 SG_ BrakeFluidLevelSts_BSM : 41|1@0+ (1,0) [0|1] ""  BCM,IPC
 SG_ BrakePedalSwitchNCFailSts : 11|1@0+ (1,0) [0|1] ""  BCM,CDCM,DCTM,ECM,RFHM
 SG_ BrakePedalSwitchNCSts : 12|1@0+ (1,0) [0|1] ""  BCM,CDCM,DCTM,ECM,RFHM
 SG_ BrakePedalSwitchNOFailSts : 13|1@0+ (1,0) [0|1] ""  BCM,CDCM,DCTM,ECM,RFHM
 SG_ BrakePedalSwitchNOSts : 14|1@0+ (1,0) [0|1] ""  BCM,CDCM,DCTM,ECM,RFHM
 SG_ BrakeTravelFailSts : 15|1@0+ (1,0) [0|1] ""  BCM,DCTM,ECM
 SG_ BrakeTravelSts : 7|8@0+ (0.4,0) [0|100] "%"  BCM,DCTM,ECM
 SG_ CRC_B11 : 63|8@0+ (1,0) [0|255] ""  BCM,CDCM,DCTM,ECM,RFHM
 SG_ DiskWearLamp : 10|1@0+ (1,0) [0|1] ""  IPC
 SG_ EPB_Pad_Wear : 40|1@0+ (1,0) [0|1] ""  IPC
 SG_ FrontDiskTemp : 25|8@0+ (3.13,0) [0|800] "°C"  IPC
 SG_ FrontDiskWear : 9|8@0+ (0.25,0) [0|63.75] "%" Vector__XXX
 SG_ Hot_Disk_Warning : 54|1@0+ (1,0) [0|1] ""  IPC
 SG_ MessageCounter_B11 : 51|4@0+ (1,0) [0|15] ""  BCM,CDCM,DCTM,ECM,RFHM
 SG_ Reactivation_Warning : 53|1@0+ (1,0) [0|1] ""  IPC
 SG_ RearDiskTemp : 33|8@0+ (3.13,0) [0|800] "°C"  IPC
 SG_ RearDiskWear : 17|8@0+ (0.25,0) [0|63.75] "%" Vector__XXX

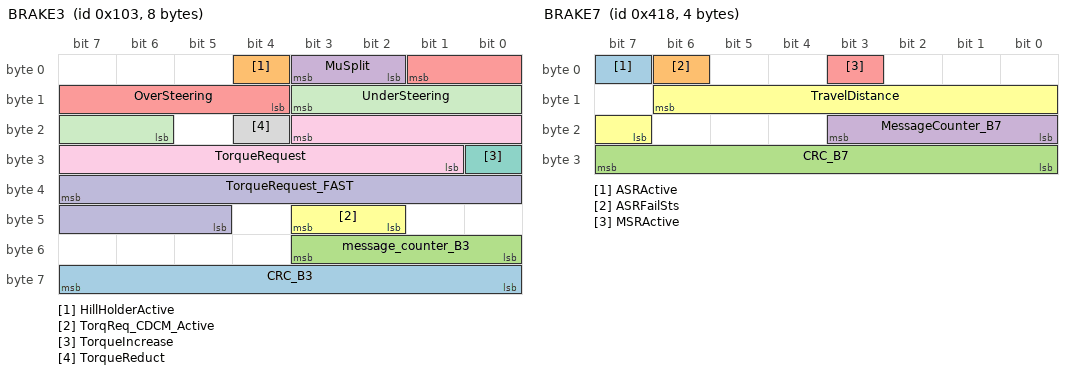
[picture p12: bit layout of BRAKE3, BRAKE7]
BO_ 259 BRAKE3: 8 DDU10
 SG_ CRC_B3 : 63|8@0+ (1,0) [0|255] ""  CDCM,DCTM,ECM
 SG_ HillHolderActive : 4|1@0+ (1,0) [0|1] ""  DCTM,ECM,ORC
 SG_ message_counter_B3 : 51|4@0+ (1,0) [0|15] ""  CDCM,DCTM,ECM
 SG_ MuSplit : 3|2@0+ (1,0) [0|2] ""  CDCM
 SG_ OverSteering : 1|6@0+ (2,0) [0|124] "%" Vector__XXX
 SG_ TorqReq_CDCM_Active : 43|2@0+ (1,0) [0|3] "-" Vector__XXX
 SG_ TorqueIncrease : 24|1@0+ (1,0) [0|1] ""  DCTM,ECM,ORC
 SG_ TorqueReduct : 20|1@0+ (1,0) [0|1] ""  DCTM,ECM,ORC
 SG_ TorqueRequest : 19|11@0+ (1,-500) [-500|1546] ""  DCTM,ECM,ORC
 SG_ TorqueRequest_FAST : 39|11@0+ (1,-500) [-500|1546] ""  DCTM,ECM
 SG_ UnderSteering : 11|6@0+ (2,0) [0|124] "%" Vector__XXX

BO_ 501 BRAKE4: 5 NotUsed
 SG_ ExternalBrkRequestsDisabled : 6|2@0+ (1,0) [0|2] "" Vector__XXX
 SG_ VehicleStandStillSts : 23|2@0+ (1,0) [0|2] ""  CDCM,ECM

BO_ 1048 BRAKE7: 4 DDU10
 SG_ ASRActive : 7|1@0+ (1,0) [0|1] "-"  CDCM,DCTM,ECM,ORC
 SG_ ASRFailSts : 6|1@0+ (1,0) [0|1] ""  CDCM,DCTM,ECM
 SG_ CRC_B7 : 31|8@0+ (1,0) [0|255] ""  CDCM,DCTM,ECM
 SG_ MessageCounter_B7 : 19|4@0+ (1,0) [0|15] ""  CDCM,DCTM,ECM
 SG_ MSRActive : 3|1@0+ (1,0) [0|1] "-"  DCTM,ECM,ORC
 SG_ TravelDistance : 14|8@0+ (1,0) [0|255] "m"  BCM,ECM,IPC,ORC

BO_ 1199 BRAKE8: 8 DDU10
 SG_ ABSCheck : 9|1@0+ (1,0) [0|1] ""  IPC
 SG_ ABSFailSts : 7|1@0+ (1,0) [0|1] "-"  DCTM,IPC,ORC,TBM
 SG_ BSM_BLC_Active : 26|1@0+ (1,0) [0|1] ""  BCM
 SG_ BSMSysSts : 47|2@0+ (1,0) [0|3] ""  DCTM,ECM
 SG_ DSTFailSts : 5|1@0+ (1,0) [0|1] "-"  BCM,IPC,ORC
 SG_ EBDCheck : 8|1@0+ (1,0) [0|1] ""  IPC
 SG_ EBDFailSts : 4|1@0+ (1,0) [0|1] "-"  DCTM,IPC,ORC,TBM
 SG_ ERMActive : 33|1@0+ (1,0) [0|1] ""  ORC
 SG_ ESCCheck : 23|1@0+ (1,0) [0|1] ""  IPC
 SG_ ESCFailSts : 2|1@0+ (1,0) [0|1] "-"  BCM,CDCM,DCTM,IPC,ORC
 SG_ ESCIntervention : 3|1@0+ (1,0) [0|1] "-"  DCTM,IPC,ORC,TBM
 SG_ ESCOFFAvailability : 22|1@0+ (1,0) [0|1] ""  IPC
 SG_ ESCOFFLamp : 21|1@0+ (1,0) [0|1] ""  IPC
 SG_ Function2Sts : 10|1@0+ (1,0) [0|1] "-"  CDCM,IPC,ORC
 SG_ FunctionFailSts : 15|1@0+ (1,0) [0|1] "-"  IPC
 SG_ FunctionIntervention : 1|1@0+ (1,0) [0|1] "-"  IPC,ORC
 SG_ FunctionSts : 0|1@0+ (1,0) [0|1] "-"  BCM,DCTM,ECM,IPC,ORC
 SG_ HillHolderFailSts : 14|1@0+ (1,0) [0|1] "-"  IPC,ORC,TBM
 SG_ RollsModeAct : 12|1@0+ (1,0) [0|1] ""  BCM,ECM
 SG_ TSCActive : 32|1@0+ (1,0) [0|1] ""  ORC

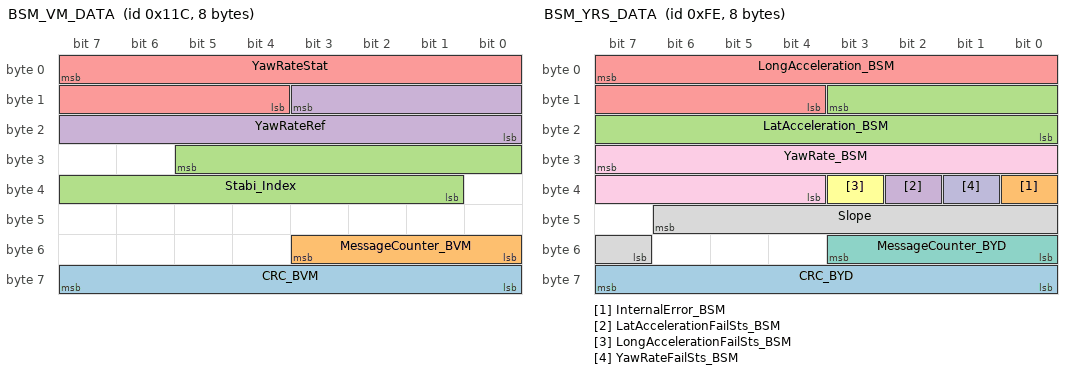
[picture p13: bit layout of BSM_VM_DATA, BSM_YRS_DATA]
BO_ 284 BSM_VM_DATA: 8 BSM
 SG_ CRC_BVM : 63|8@0+ (1,0) [0|255] "-" Vector__XXX
 SG_ MessageCounter_BVM : 51|4@0+ (1,0) [0|15] "-" Vector__XXX
 SG_ Stabi_Index : 29|13@0+ (0.08,-100) [-100|555.28] "%" Vector__XXX
 SG_ YawRateRef : 11|12@0+ (0.08,-93) [-93|234.52] "deg/s" Vector__XXX
 SG_ YawRateStat : 7|12@0+ (0.08,-93) [-93|234.52] "deg/s" Vector__XXX

BO_ 254 BSM_YRS_DATA: 8 DDU10
 SG_ CRC_BYD : 63|8@0+ (1,0) [0|255] "-"  BCM,DCTM,ECM
 SG_ InternalError_BSM : 32|1@0+ (1,0) [0|1] "-" Vector__XXX
 SG_ LatAcceleration_BSM : 11|12@0+ (0.02,-40.96) [-40.96|40.92] "m/s^2"  BCM,DCTM,IPC,TBM
 SG_ LatAccelerationFailSts_BSM : 34|1@0+ (1,0) [0|1] "-"  BCM,DCTM,IPC
 SG_ LongAcceleration_BSM : 7|12@0+ (0.02,-40.96) [-40.96|40.92] "m/s^2"  BCM,DCTM,ECM,IPC,TBM
 SG_ LongAccelerationFailSts_BSM : 35|1@0+ (1,0) [0|1] "-"  BCM,DCTM,ECM,IPC
 SG_ MessageCounter_BYD : 51|4@0+ (1,0) [0|15] "-"  BCM,DCTM,ECM
 SG_ Slope : 46|8@0+ (1,-100) [-100|154] "%"  BCM,DCTM,ECM
 SG_ YawRate_BSM : 31|12@0+ (0.08,-163.84) [-163.84|163.68] "deg/s"  BCM,ORC
 SG_ YawRateFailSts_BSM : 33|1@0+ (1,0) [0|1] "-" Vector__XXX

BO_ 750 C2_IGW2: 4 NotUsed
 SG_ SteeringColumnTorque : 7|11@0+ (0.0078125,-8) [-8|7.984375] "Nm"  ECM

BO_ 280 CDCM1: 6 CDCM
 SG_ CRC_TVM : 47|8@0+ (1,0) [0|255] ""  DCTM
 SG_ MessageCounter_TVM : 35|4@0+ (1,0) [0|15] "-"  DCTM
 SG_ R_Diff_Mode_Req : 3|3@0+ (1,0) [0|7] ""  BSM
 SG_ R_Diff_Trq_Req : 31|8@0+ (9.96,0) [0|2539.8] "Nm"  BSM,DCTM

BO_ 288 CDCM3: 6 NotUsed
 SG_ CRC_EC : 31|8@0+ (1,0) [0|255] ""  ECM
 SG_ MessageCounter_EC : 19|4@0+ (1,0) [0|15] "-"  ECM

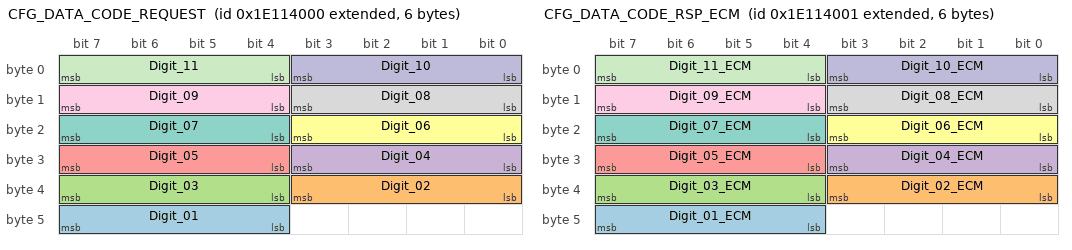
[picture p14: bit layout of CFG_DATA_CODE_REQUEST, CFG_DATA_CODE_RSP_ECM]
BO_ 2651930624 CFG_DATA_CODE_REQUEST: 6 NotUsed
 SG_ Digit_01 : 47|4@0+ (1,0) [0|15] ""  DCTM,ECM,IPC,RFHM,TBM
 SG_ Digit_02 : 35|4@0+ (1,0) [0|15] ""  DCTM,ECM,IPC,RFHM,TBM
 SG_ Digit_03 : 39|4@0+ (1,0) [0|15] ""  DCTM,ECM,IPC,RFHM,TBM
 SG_ Digit_04 : 27|4@0+ (1,0) [0|15] ""  DCTM,ECM,IPC,RFHM,TBM
 SG_ Digit_05 : 31|4@0+ (1,0) [0|15] ""  DCTM,ECM,IPC,RFHM,TBM
 SG_ Digit_06 : 19|4@0+ (1,0) [0|15] ""  DCTM,ECM,IPC,RFHM,TBM
 SG_ Digit_07 : 23|4@0+ (1,0) [0|15] ""  DCTM,ECM,IPC,RFHM,TBM
 SG_ Digit_08 : 11|4@0+ (1,0) [0|15] ""  DCTM,ECM,IPC,RFHM,TBM
 SG_ Digit_09 : 15|4@0+ (1,0) [0|15] ""  DCTM,ECM,IPC,RFHM,TBM
 SG_ Digit_10 : 3|4@0+ (1,0) [0|15] ""  DCTM,ECM,IPC,RFHM,TBM
 SG_ Digit_11 : 7|4@0+ (1,0) [0|15] ""  DCTM,ECM,IPC,RFHM,TBM

BO_ 2651930625 CFG_DATA_CODE_RSP_ECM: 6 ECM
 SG_ Digit_01_ECM : 47|4@0+ (1,0) [0|15] "-"  BCM
 SG_ Digit_02_ECM : 35|4@0+ (1,0) [0|15] "-"  BCM
 SG_ Digit_03_ECM : 39|4@0+ (1,0) [0|15] "-"  BCM
 SG_ Digit_04_ECM : 27|4@0+ (1,0) [0|15] "-"  BCM
 SG_ Digit_05_ECM : 31|4@0+ (1,0) [0|15] "-"  BCM
 SG_ Digit_06_ECM : 19|4@0+ (1,0) [0|15] "-"  BCM
 SG_ Digit_07_ECM : 23|4@0+ (1,0) [0|15] "-"  BCM
 SG_ Digit_08_ECM : 11|4@0+ (1,0) [0|15] "-"  BCM
 SG_ Digit_09_ECM : 15|4@0+ (1,0) [0|15] "-"  BCM
 SG_ Digit_10_ECM : 3|4@0+ (1,0) [0|15] "-"  BCM
 SG_ Digit_11_ECM : 7|4@0+ (1,0) [0|15] "-"  BCM

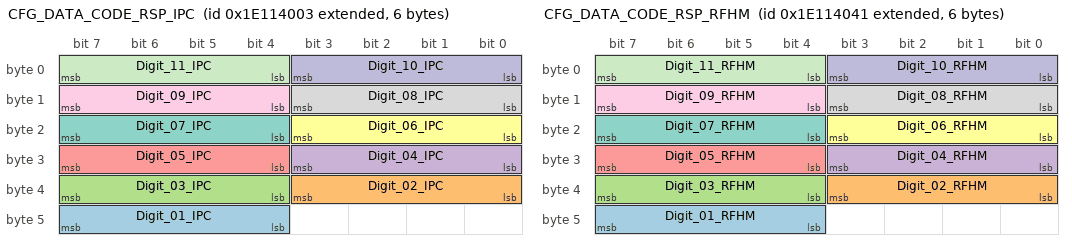
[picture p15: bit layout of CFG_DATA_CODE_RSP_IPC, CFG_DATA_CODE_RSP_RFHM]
BO_ 2651930627 CFG_DATA_CODE_RSP_IPC: 6 IPC
 SG_ Digit_01_IPC : 47|4@0+ (1,0) [0|15] "-"  BCM
 SG_ Digit_02_IPC : 35|4@0+ (1,0) [0|15] "-"  BCM
 SG_ Digit_03_IPC : 39|4@0+ (1,0) [0|15] "-"  BCM
 SG_ Digit_04_IPC : 27|4@0+ (1,0) [0|15] "-"  BCM
 SG_ Digit_05_IPC : 31|4@0+ (1,0) [0|15] "-"  BCM
 SG_ Digit_06_IPC : 19|4@0+ (1,0) [0|15] "-"  BCM
 SG_ Digit_07_IPC : 23|4@0+ (1,0) [0|15] "-"  BCM
 SG_ Digit_08_IPC : 11|4@0+ (1,0) [0|15] "-"  BCM
 SG_ Digit_09_IPC : 15|4@0+ (1,0) [0|15] "-"  BCM
 SG_ Digit_10_IPC : 3|4@0+ (1,0) [0|15] "-"  BCM
 SG_ Digit_11_IPC : 7|4@0+ (1,0) [0|15] "-"  BCM

BO_ 2651930689 CFG_DATA_CODE_RSP_RFHM: 6 RFHM
 SG_ Digit_01_RFHM : 47|4@0+ (1,0) [0|15] "-"  BCM
 SG_ Digit_02_RFHM : 35|4@0+ (1,0) [0|15] "-"  BCM
 SG_ Digit_03_RFHM : 39|4@0+ (1,0) [0|15] "-"  BCM
 SG_ Digit_04_RFHM : 27|4@0+ (1,0) [0|15] "-"  BCM
 SG_ Digit_05_RFHM : 31|4@0+ (1,0) [0|15] "-"  BCM
 SG_ Digit_06_RFHM : 19|4@0+ (1,0) [0|15] "-"  BCM
 SG_ Digit_07_RFHM : 23|4@0+ (1,0) [0|15] "-"  BCM
 SG_ Digit_08_RFHM : 11|4@0+ (1,0) [0|15] "-"  BCM
 SG_ Digit_09_RFHM : 15|4@0+ (1,0) [0|15] "-"  BCM
 SG_ Digit_10_RFHM : 3|4@0+ (1,0) [0|15] "-"  BCM
 SG_ Digit_11_RFHM : 7|4@0+ (1,0) [0|15] "-"  BCM

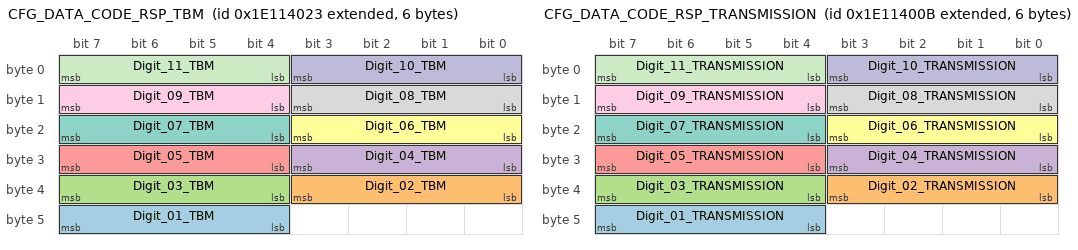
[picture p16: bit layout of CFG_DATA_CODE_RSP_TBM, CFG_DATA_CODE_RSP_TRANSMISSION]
BO_ 2651930659 CFG_DATA_CODE_RSP_TBM: 6 TBM
 SG_ Digit_01_TBM : 47|4@0+ (1,0) [0|15] "-"  BCM
 SG_ Digit_02_TBM : 35|4@0+ (1,0) [0|15] "-"  BCM
 SG_ Digit_03_TBM : 39|4@0+ (1,0) [0|15] "-"  BCM
 SG_ Digit_04_TBM : 27|4@0+ (1,0) [0|15] "-"  BCM
 SG_ Digit_05_TBM : 31|4@0+ (1,0) [0|15] "-"  BCM
 SG_ Digit_06_TBM : 19|4@0+ (1,0) [0|15] "-"  BCM
 SG_ Digit_07_TBM : 23|4@0+ (1,0) [0|15] "-"  BCM
 SG_ Digit_08_TBM : 11|4@0+ (1,0) [0|15] "-"  BCM
 SG_ Digit_09_TBM : 15|4@0+ (1,0) [0|15] "-"  BCM
 SG_ Digit_10_TBM : 3|4@0+ (1,0) [0|15] "-"  BCM
 SG_ Digit_11_TBM : 7|4@0+ (1,0) [0|15] "-"  BCM

BO_ 2651930635 CFG_DATA_CODE_RSP_TRANSMISSION: 6 DCTM
 SG_ Digit_01_TRANSMISSION : 47|4@0+ (1,0) [0|15] "-"  BCM
 SG_ Digit_02_TRANSMISSION : 35|4@0+ (1,0) [0|15] "-"  BCM
 SG_ Digit_03_TRANSMISSION : 39|4@0+ (1,0) [0|15] "-"  BCM
 SG_ Digit_04_TRANSMISSION : 27|4@0+ (1,0) [0|15] "-"  BCM
 SG_ Digit_05_TRANSMISSION : 31|4@0+ (1,0) [0|15] "-"  BCM
 SG_ Digit_06_TRANSMISSION : 19|4@0+ (1,0) [0|15] "-"  BCM
 SG_ Digit_07_TRANSMISSION : 23|4@0+ (1,0) [0|15] "-"  BCM
 SG_ Digit_08_TRANSMISSION : 11|4@0+ (1,0) [0|15] "-"  BCM
 SG_ Digit_09_TRANSMISSION : 15|4@0+ (1,0) [0|15] "-"  BCM
 SG_ Digit_10_TRANSMISSION : 3|4@0+ (1,0) [0|15] "-"  BCM
 SG_ Digit_11_TRANSMISSION : 7|4@0+ (1,0) [0|15] "-"  BCM

BO_ 601 CLUSTER1: 8 DDU10
 SG_ ElectricSteeringLamp_FailSts : 47|2@0+ (1,0) [0|3] "-"  BCM,ORC
 SG_ TotalOdometer : 23|20@0+ (1,0) [0|1048575] "km"  BCM,BSM,CDCM,DCTM,ECM,ORC,RFHM

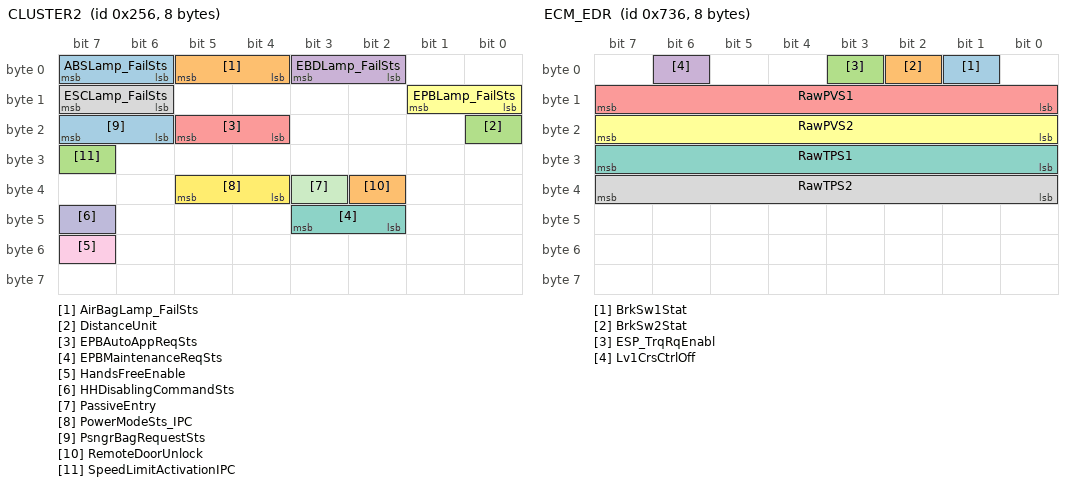
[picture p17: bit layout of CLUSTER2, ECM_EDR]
BO_ 598 CLUSTER2: 8 NotUsed
 SG_ ABSLamp_FailSts : 7|2@0+ (1,0) [0|3] "-"  BSM
 SG_ AirBagLamp_FailSts : 5|2@0+ (1,0) [0|3] "-"  ORC,TBM
 SG_ DistanceUnit : 16|1@0+ (1,0) [0|1] ""  ECM,TBM
 SG_ EBDLamp_FailSts : 3|2@0+ (1,0) [0|3] "-"  BSM
 SG_ EPBAutoAppReqSts : 21|2@0+ (1,0) [0|3] ""  BSM
 SG_ EPBLamp_FailSts : 9|2@0+ (1,0) [0|3] ""  BSM
 SG_ EPBMaintenanceReqSts : 43|2@0+ (1,0) [0|3] "-"  BSM
 SG_ ESCLamp_FailSts : 15|2@0+ (1,0) [0|3] "-"  BSM
 SG_ HandsFreeEnable : 55|1@0+ (1,0) [0|1] "-"  RFHM
 SG_ HHDisablingCommandSts : 47|1@0+ (1,0) [0|1] ""  TBM
 SG_ PassiveEntry : 35|1@0+ (1,0) [0|1] ""  RFHM
 SG_ PowerModeSts_IPC : 37|2@0+ (1,0) [0|3] ""  BCM
 SG_ PsngrBagRequestSts : 23|2@0+ (1,0) [0|3] "-"  ORC
 SG_ RemoteDoorUnlock : 34|1@0+ (1,0) [0|1] ""  RFHM
 SG_ SpeedLimitActivationIPC : 31|1@0+ (1,0) [0|1] "-" Vector__XXX

BO_ 2564554481 DIAGNOSTIC_REQ_FUNC_C1: 8 DIAG_TEST
 SG_ N_PDU : 7|64@0+ (1,0) [0|0] ""  BCM

BO_ 2564440305 DIAGNOSTIC_REQUEST_BCM: 8 DIAG_TEST
 SG_ N_PDU : 7|64@0+ (1,0) [0|0] ""  BCM,TBM

BO_ 2564434161 DIAGNOSTIC_REQUEST_BSM: 8 BCM
 SG_ N_PDU : 7|64@0+ (1,0) [0|0] ""  BCM,TBM

BO_ 2564432113 DIAGNOSTIC_REQUEST_CDCM: 8 BCM
 SG_ N_PDU : 7|64@0+ (1,0) [0|0] ""  BCM,TBM

BO_ 2564428017 DIAGNOSTIC_REQUEST_ECM: 8 DIAG_TEST
 SG_ N_PDU : 7|64@0+ (1,0) [0|0] ""  ECM,TBM

BO_ 2564436209 DIAGNOSTIC_REQUEST_EPS: 8 BCM
 SG_ N_PDU : 7|64@0+ (1,0) [0|0] ""  BCM,TBM

BO_ 2564502513 DIAGNOSTIC_REQUEST_FUNC_OBD: 8 DIAG_TEST
 SG_ N_PDU : 7|64@0+ (1,0) [0|0] ""  DCTM,ECM,TBM

BO_ 2564448497 DIAGNOSTIC_REQUEST_IPC: 8 DIAG_TEST
 SG_ N_PDU : 7|64@0+ (1,0) [0|0] "-"  IPC,TBM

BO_ 2564473073 DIAGNOSTIC_REQUEST_ORC: 8 BCM
 SG_ N_PDU : 7|64@0+ (1,0) [0|0] ""  BCM,TBM

BO_ 2564464881 DIAGNOSTIC_REQUEST_PAM: 8 BCM
 SG_ N_PDU : 7|64@0+ (1,0) [0|0] ""  BCM,TBM

BO_ 2564474865 DIAGNOSTIC_REQUEST_RFHM: 8 DIAG_TEST
 SG_ N_PDU : 7|64@0+ (1,0) [0|0] ""  RFHM,TBM

BO_ 2564474609 DIAGNOSTIC_REQUEST_TBM: 8 DIAG_TEST
 SG_ N_PDU : 7|64@0+ (1,0) [0|0] ""  TBM

BO_ 2564430065 DIAGNOSTIC_REQUEST_TRANSMISSION: 8 DIAG_TEST
 SG_ N_PDU : 7|64@0+ (1,0) [0|0] ""  DCTM,TBM

BO_ 2564485440 DIAGNOSTIC_RESPONSE_BCM: 8 NotUsed
 SG_ N_PDU : 7|64@0+ (1,0) [0|0] ""  DIAG_TEST,TBM

BO_ 2564485392 DIAGNOSTIC_RESPONSE_ECM: 8 ECM
 SG_ N_PDU : 7|64@0+ (1,0) [0|0] ""  DIAG_TEST,TBM

BO_ 2564485472 DIAGNOSTIC_RESPONSE_IPC: 8 IPC
 SG_ N_PDU : 7|64@0+ (1,0) [0|0] "-"  DIAG_TEST,TBM

BO_ 2564485575 DIAGNOSTIC_RESPONSE_RFHM: 8 RFHM
 SG_ N_PDU : 7|64@0+ (1,0) [0|0] ""  DIAG_TEST,TBM

BO_ 2564485672 DIAGNOSTIC_RESPONSE_SQDF_BSM: 8 BCM
 SG_ N_PDU : 7|64@0+ (1,0) [0|0] ""  TBM

BO_ 2564485664 DIAGNOSTIC_RESPONSE_SQDF_CDCM: 8 BCM
 SG_ N_PDU : 7|64@0+ (1,0) [0|0] ""  TBM

BO_ 2564485680 DIAGNOSTIC_RESPONSE_SQDF_EPS: 8 BCM
 SG_ N_PDU : 7|64@0+ (1,0) [0|0] ""  TBM

BO_ 2564485824 DIAGNOSTIC_RESPONSE_SQDF_ORC: 8 BCM
 SG_ N_PDU : 7|64@0+ (1,0) [0|0] ""  TBM

BO_ 2564485792 DIAGNOSTIC_RESPONSE_SQDF_PAM: 8 BCM
 SG_ N_PDU : 7|64@0+ (1,0) [0|0] ""  TBM

BO_ 2564485574 DIAGNOSTIC_RESPONSE_TBM: 8 TBM
 SG_ N_PDU : 7|64@0+ (1,0) [0|0] ""  DIAG_TEST

BO_ 2564485400 DIAGNOSTIC_RESPONSE_TRANSMISSION: 8 DCTM
 SG_ N_PDU : 7|64@0+ (1,0) [0|0] ""  DIAG_TEST,TBM

BO_ 1846 ECM_EDR: 8 ECM
 SG_ BrkSw1Stat : 1|1@0+ (1,0) [0|1] ""  ORC
 SG_ BrkSw2Stat : 2|1@0+ (1,0) [0|1] ""  ORC
 SG_ ESP_TrqRqEnabl : 3|1@0+ (1,0) [0|1] ""  ORC
 SG_ Lv1CrsCtrlOff : 6|1@0+ (1,0) [0|1] ""  ORC
 SG_ RawPVS1 : 15|8@0+ (0.019607843,0) [0|4.98] "V"  ORC
 SG_ RawPVS2 : 23|8@0+ (0.019607843,0) [0|4.98] "V"  ORC
 SG_ RawTPS1 : 31|8@0+ (0.019607843,0) [0|4.98] "V"  ORC
 SG_ RawTPS2 : 39|8@0+ (0.019607843,0) [0|4.98] "V"  ORC

BO_ 1422 ELATCH1: 4 DDU10
 SG_ DriverDoor2AjarRawValSts : 17|5@0+ (1,0) [0|31] "mA"  ECM
 SG_ DriverDoor3AjarRawValSts : 28|1@0+ (1,0) [0|1] ""  ECM
 SG_ DriverDoor4AjarRawValSts : 27|1@0+ (1,0) [0|1] ""  ECM
 SG_ DriverDoorAjarRawValSts : 22|5@0+ (1,0) [0|31] "mA"  ECM
 SG_ DrvDoorLatchDeadLockSts : 2|1@0+ (1,0) [0|1] "" Vector__XXX
 SG_ DrvDoorLatchSts : 3|1@0+ (1,0) [0|1] "" Vector__XXX
 SG_ E1DriverDoorSts : 1|1@0+ (1,0) [0|1] ""  DCTM
 SG_ LSMDAjarSensorFailSts : 15|1@0+ (1,0) [0|1] "" Vector__XXX
 SG_ LSMDCrashLineFailSts : 9|1@0+ (1,0) [0|1] "" Vector__XXX
 SG_ LSMDExternalLockReleaseSwitchFai : 13|1@0+ (1,0) [0|1] "" Vector__XXX
 SG_ LSMDFobSearchReq : 5|2@0+ (1,0) [0|3] ""  RFHM
 SG_ LSMDInternalFailSts : 10|1@0+ (1,0) [0|1] "" Vector__XXX
 SG_ LSMDInternalLockLightFailSts : 11|1@0+ (1,0) [0|1] "" Vector__XXX
 SG_ LSMDInternalReleaseSwitchFailSts : 14|1@0+ (1,0) [0|1] "" Vector__XXX
 SG_ LSMDInternalUnlockLightFailSts : 12|1@0+ (1,0) [0|1] "" Vector__XXX
 SG_ LSMDReleaseLockReq : 7|2@0+ (1,0) [0|3] "" Vector__XXX
 SG_ LSMDTrunkDisableReq : 0|1@0+ (1,0) [0|1] "" Vector__XXX

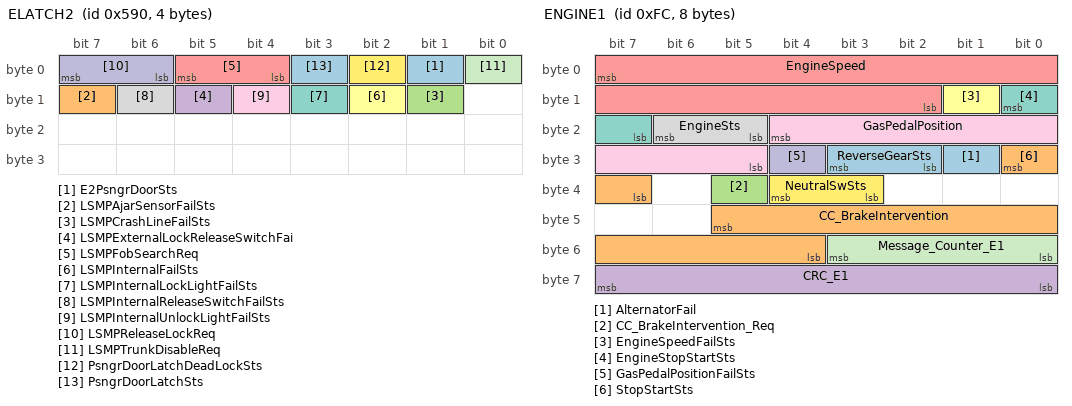
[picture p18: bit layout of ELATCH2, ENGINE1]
BO_ 1424 ELATCH2: 4 BCM
 SG_ E2PsngrDoorSts : 1|1@0+ (1,0) [0|1] "" Vector__XXX
 SG_ LSMPAjarSensorFailSts : 15|1@0+ (1,0) [0|1] "" Vector__XXX
 SG_ LSMPCrashLineFailSts : 9|1@0+ (1,0) [0|1] "" Vector__XXX
 SG_ LSMPExternalLockReleaseSwitchFai : 13|1@0+ (1,0) [0|1] "" Vector__XXX
 SG_ LSMPFobSearchReq : 5|2@0+ (1,0) [0|3] ""  RFHM
 SG_ LSMPInternalFailSts : 10|1@0+ (1,0) [0|1] "" Vector__XXX
 SG_ LSMPInternalLockLightFailSts : 11|1@0+ (1,0) [0|1] "" Vector__XXX
 SG_ LSMPInternalReleaseSwitchFailSts : 14|1@0+ (1,0) [0|1] "" Vector__XXX
 SG_ LSMPInternalUnlockLightFailSts : 12|1@0+ (1,0) [0|1] "" Vector__XXX
 SG_ LSMPReleaseLockReq : 7|2@0+ (1,0) [0|3] "" Vector__XXX
 SG_ LSMPTrunkDisableReq : 0|1@0+ (1,0) [0|1] "" Vector__XXX
 SG_ PsngrDoorLatchDeadLockSts : 2|1@0+ (1,0) [0|1] "" Vector__XXX
 SG_ PsngrDoorLatchSts : 3|1@0+ (1,0) [0|1] "" Vector__XXX

BO_ 252 ENGINE1: 8 ECM
 SG_ AlternatorFail : 25|1@0+ (1,0) [0|1] "-"  BCM,IPC,TBM
 SG_ CC_BrakeIntervention : 45|10@0+ (0.01,-10) [-10|0.22] "m/s^2"  BSM
 SG_ CC_BrakeIntervention_Req : 37|1@0+ (1,0) [0|1] ""  BSM
 SG_ CRC_E1 : 63|8@0+ (1,0) [0|255] ""  BCM,BSM,CDCM,DCTM,RFHM
 SG_ EngineSpeed : 7|14@0+ (1,0) [0|16382] "1/min"  BCM,BSM,CDCM,DCTM,IPC,ORC,TBM
 SG_ EngineSpeedFailSts : 9|1@0+ (1,0) [0|1] ""  BCM,BSM,CDCM,DCTM,IPC,ORC
 SG_ EngineStopStartSts : 8|2@0+ (1,0) [0|3] "-"  BCM,BSM
 SG_ EngineSts : 22|2@0+ (1,0) [0|3] "-"  BCM,BSM,CDCM,DCTM,IONM,IPC,ORC,RFHM
 SG_ GasPedalPosition : 20|8@0+ (0.392,0) [0|99.568] "%"  BCM,BSM,CDCM,DCTM,IPC,TBM
 SG_ GasPedalPositionFailSts : 28|1@0+ (1,0) [0|1] "-"  BCM,BSM,CDCM,DCTM,ORC
 SG_ Message_Counter_E1 : 51|4@0+ (1,0) [0|15] ""  BCM,BSM,CDCM,DCTM,RFHM
 SG_ NeutralSwSts : 36|2@0+ (1,0) [0|3] "-"  BCM,BSM
 SG_ ReverseGearSts : 27|2@0+ (1,0) [0|3] "-"  BCM,BSM,CDCM,IPC,ORC,RFHM,TBM
 SG_ StopStartSts : 24|2@0+ (1,0) [0|3] "-"  BCM,BSM,IPC,TBM

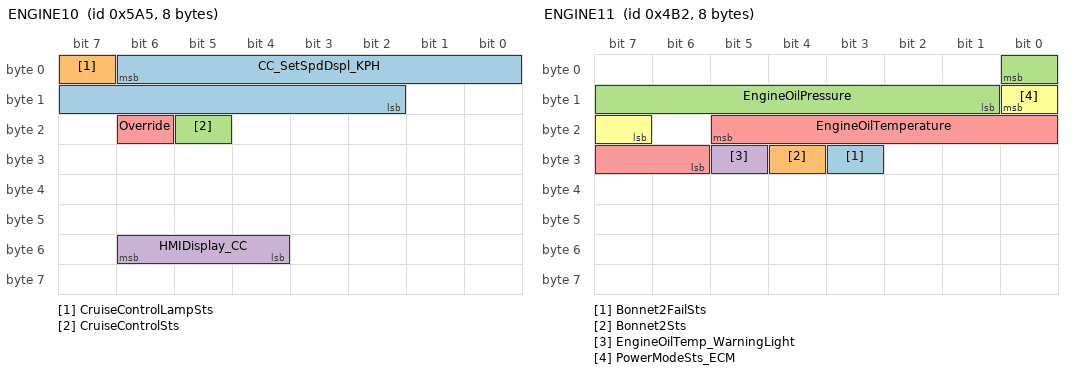
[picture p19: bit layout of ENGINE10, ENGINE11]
BO_ 1445 ENGINE10: 8 ECM
 SG_ CC_SetSpdDspl_KPH : 6|13@0+ (0.0625,0) [0|511.875] "kph"  IPC
 SG_ CruiseControlLampSts : 7|1@0+ (1,0) [0|1] "-"  IPC,ORC,TBM
 SG_ CruiseControlSts : 21|1@0+ (1,0) [0|1] "-"  DCTM,IPC,ORC,TBM
 SG_ HMIDisplay_CC : 54|3@0+ (1,0) [0|7] "-"  IPC
 SG_ Override : 22|1@0+ (1,0) [0|1] "-"  DCTM,ORC

BO_ 1202 ENGINE11: 8 ECM
 SG_ Bonnet2FailSts : 27|1@0+ (1,0) [0|1] ""  BCM
 SG_ Bonnet2Sts : 28|1@0+ (1,0) [0|1] ""  BCM
 SG_ EngineOilPressure : 0|8@0+ (0.1,0) [0|25.4] "bar" Vector__XXX
 SG_ EngineOilTemp_WarningLight : 29|1@0+ (1,0) [0|1] "-"  IPC,TBM
 SG_ EngineOilTemperature : 21|8@0+ (1,-40) [-40|215] "°C"  IPC,TBM
 SG_ PowerModeSts_ECM : 8|2@0+ (1,0) [0|3] "-"  BCM

BO_TX_BU_ 2564440305 : DIAG_TEST,TBM;
BO_TX_BU_ 2564434161 : BCM,TBM;
BO_TX_BU_ 2564432113 : BCM,TBM;
BO_TX_BU_ 2564428017 : DIAG_TEST,TBM;
BO_TX_BU_ 2564436209 : BCM,TBM;
BO_TX_BU_ 2564502513 : DIAG_TEST,TBM;
BO_TX_BU_ 2564448497 : DIAG_TEST,TBM;
BO_TX_BU_ 2564473073 : BCM,TBM;
BO_TX_BU_ 2564464881 : BCM,TBM;
BO_TX_BU_ 2564474865 : DIAG_TEST,TBM;
BO_TX_BU_ 2564430065 : DIAG_TEST,TBM;

CM_ "Project_H2E_KIT_PWTCAN";
CM_ BO_ 3221225472 "This is a message for not used signals, created by Vector CANdb++ DBC OLE DB Provider.";
CM_ SG_ 3221225472 ABS_Malfunction "Bit will jump to 1, if the ABS control is deactivated by a fault";
CM_ SG_ 3221225472 acc_FA_Kopie_3 "Fill level of the fluid reservoir of the front axle";
CM_ SG_ 3221225472 acc_FA_Kopie_2 "Fill level of the fluid reservoir of the front axle";
CM_ SG_ 3221225472 acc_FA_Kopie_1 "Fill level of the fluid reservoir of the front axle";
CM_ SG_ 1345 IF_variant "external info to e.g. MS6 which dbc has to be used. This index increments on changes that make the MS6 interface incompatible to the predecessor CAN interface implementation";
CM_ SG_ 1345 IF_revision "external info to e.g. MS6 which dbc has to be used. This index increments with added features (rest of MS6 interface stays intact.)";
CM_ SG_ 1345 If_chksum "external info to e.g. MS6 which dbc has to be used. Checksum";
CM_ SG_ 1345 WarmUpLogic_Activated "WarmUp logic during ABS-off position shall prevent unmatching plausibility monitorings while the car is jacked up / wheels are free spinning";
CM_ SG_ 1345 PsMonitoring_RA_Status "The pressure sensor monitoring (front/ rear) operation mode and 'active' / 'fault triggered' status";
CM_ SG_ 1345 PSMonitoring_FA_Status "The pressure sensor monitoring (front/ rear) operation mode and 'active' / 'fault triggered' status";
CM_ SG_ 1345 AY1_ABS_int "Used lateral acceleration value in the ABS";
CM_ SG_ 1345 AX1_ABS_int "Used longitidional acceleration value in the ABS.";
CM_ SG_ 1376 Brake_bal_pct_advice "Recommended percental brake balance on the front axle.";
CM_ SG_ 1376 Brake_bal_pct "Percental brake balance on the front axle.";
CM_ SG_ 1376 Brake_bal_at50_advice "Recommended rear axle brake pressure if the front pressure is at 50 bar.";
CM_ SG_ 1376 Brake_bal_at50 "Calculated rear axle brake pressure if the front pressure is at 50 bar.";
CM_ SG_ 834 WheelQuality_RR "Bit matrix...";
CM_ SG_ 834 WheelQuality_RL "Bit matrix...";
CM_ SG_ 834 WheelQuality_FR "Bit matrix...";
CM_ SG_ 834 WheelQuality_FL "Bit matrix...";
CM_ SG_ 834 acc_RA "Fill level of the fluid reservoir of the rear axle";
CM_ SG_ 834 acc_FA "Fill level of the fluid reservoir of the front axle";
CM_ SG_ 1472 ABS_fault_info "Bit matrix to show if a fault or a active fault is stored in the ABS. Bit will also show minor errors which do  not shut down the ABS controller.";
CM_ SG_ 1472 Diag_YRS "Bit to show, if the yaw rate sensor is working properly. An error is pressent, if the bit is 1.";
CM_ SG_ 1472 Diag_P_RA "Bit to show, if the pressure sensor RA is working properly. An error is pressent, if the bit is 1.";
CM_ SG_ 1472 Diag_P_FA "Bit to show, if the pressure sensor FA is working properly. An error is pressent, if the bit is 1.";
CM_ SG_ 1472 Diag_FuseValve "Bit to show, if a ABS error related to the fuse or power supply of the ABS valves is present.";
CM_ SG_ 1472 Diag_FusePump "Bit to show, if a ABS error related to the fuse or power supply of the ABS pump is present.";
CM_ SG_ 1472 Diag_ABSUnit "Bit to show, if a ABS error related to the hydraulic unit is present";
CM_ SG_ 1472 Diag_RR "Value to show faults related to the wheel speed sensor. 
0 - Signal ok, 1 - Wiring related fault, 2 - Signal related fault";
CM_ SG_ 1472 Diag_RL "Value to show faults related to the wheel speed sensor. 
0 - Signal ok, 1 - Wiring related fault, 2 - Signal related fault";
CM_ SG_ 1472 Diag_FR "Value to show faults related to the wheel speed sensor. 
0 - Signal ok, 1 - Wiring related fault, 2 - Signal related fault";
CM_ SG_ 1472 Diag_FL "Value to show faults related to the wheel speed sensor. 
0 - Signal ok, 1 - Wiring related fault, 2 - Signal related fault";
CM_ SG_ 1472 ABS_Lamp "Bit will jump to 1, when the ABS control is deactivated due to a fault, switch to the off position or while working with RaceABS.";
CM_ SG_ 1472 EBD_Lamp "Bit will jump to 1, when the EBD is deactivated due to a fault.";
CM_ SG_ 1472 ABS_Active "Bit will jump to 1, when the ABS control is active.";
CM_ SG_ 1472 ABS_Malfunction "Bit will switch to 1, if the ABS is deactivated by a fault";
CM_ SG_ 1472 RtaOk_Placeholder "RTA not used in the ABS M5, Bit was used in the M4";
CM_ SG_ 1472 BLS "Bit for brake light switch.";
CM_ SG_ 1472 SwitchPosition "Used as position of the ABS";
CM_ SG_ 1346 SW_version_Low_lower "version 1.0 as 0x00(lower), version 100.20 as 0x14(lower)";
CM_ SG_ 1346 Appl_date_06 "seconds";
CM_ SG_ 1346 SW_version_Low_upper "version 1.0 as 0x01(upper), version 100.20 as 0x64(upper)";
CM_ SG_ 1346 Appl_date_05 "minute";
CM_ SG_ 1346 SW_version_Mid_lower "version 1.0 as 0x00(lower), version 100.20 as 0x14(lower)";
CM_ SG_ 1346 Appl_date_04 "hour";
CM_ SG_ 1346 SW_version_Mid_upper "version 1.0 as 0x01(upper), version 100.20 as 0x64(upper)";
CM_ SG_ 1346 Appl_date_03 "day";
CM_ SG_ 1346 SW_version_High_lower "version 1.0 as 0x00(lower), version 100.20 as 0x14(lower)";
CM_ SG_ 1346 Appl_date_02 "month";
CM_ SG_ 1346 SW_version_High_upper "version 1.0 as 0x01(upper), version 100.20 as 0x64(upper)";
CM_ SG_ 1346 Appl_date_01 "year";
CM_ SG_ 1346 Mplx_SW_Info "1=SW version; 2=BB#; 3,4=application name; 5=application date (UTC); 6=deviceType (SW CAN ident, ABS M5=2, ABS M6=3); 7=Serial#";
CM_ SG_ 1592 HYS_errCod "0x0: Diagnosis Not Executed
0x1: No Error
0x2: CMC over temperature
0x3: SBC over temperature
0x4: ADC over temperature
";
CM_ SG_ 1592 HYS_diagSnsr "0x0: Diagnosis Not Executed
0x1: No Error
0x2: Temperature Error
0x3: Communication Error
0x4: Battery Error
0x5: H2 Diagnosis Error
0x6 ... 0xE: not defined yet
0xF: Signal Not Available";
CM_ SG_ 1592 HYS_stSnsr "0x0: Initialisation
0x1: Lower Accuracy
0x2: Higher Accuracy
0x3: Error
0x4 ... 0xD: not defined yet
0xE: Heating Up Phase
0xF: Signal Not Available";
CM_ SG_ 599 AirBagFailSts "This signal is used to require the activation/deactivation of airbag warning light";
CM_ SG_ 599 PsngrBagChargeSts "This signal is used to communicate the status of Front Passenger Protection Pyrotechnical charges";
CM_ SG_ 599 SBR1RowDriverSeatConfigSts "Signal used to show if the first row driver seatbelt is under check";
CM_ SG_ 599 SBR1RowDriverSeatFailSts "First row driver seatbelt switch fail status";
CM_ SG_ 599 SBR1RowDriverSeatSts "First row driver seatbelt switch status";
CM_ SG_ 599 SBR1RowPsngrSeatBuckleFailSts "First row passenger seatbelt buckle switch fail status";
CM_ SG_ 599 SBR1RowPsngrSeatConfigSts "Signal used to show if the first row passenger seatbelt is under check";
CM_ SG_ 599 SBR1RowPsngrSeatPPDFailSts "PPD fail status of first row passenger seat";
CM_ SG_ 599 SBR1RowPsngrSeatSts "First row passenger seat status";
CM_ SG_ 1447 CRC_A2 "CRC according to SAE J1850 standard that has to be calculated at each frame transmission";
CM_ SG_ 1447 DrvSbltUnFltr "Driver seatbelt fault status - unfiltered";
CM_ SG_ 1447 MessageCounter_A2 "This signal is a counter used for safety checks strategies. This counter is incremented of 1 (one) unit at each frame transmission";
CM_ SG_ 1050 BatteryVoltageLevelHP "This signal indicates the battery voltage.";
CM_ SG_ 1050 BCMSAMFailSts "This signal indicates a fault present in BCM related to the SAM strategy.";
CM_ SG_ 1050 VoltageMax "This signal indicates the maximum regulation voltage permitted by BCM in the SAM strategy.";
CM_ SG_ 1050 VoltageMin "This signal indicates the minimum regulation voltage permitted by BCM in the SAM strategy.";
CM_ SG_ 247 TxpAuthRequest "This signal is used to request a transponder authentication";
CM_ SG_ 247 TxpReadRequest "This signal is used to request a transponder reading";
CM_ SG_ 250 BCMFpsCommand "The signal is used to command the FPS strategy actuation";
CM_ SG_ 250 BCMFpsConfirm "The signal is used to confirm the FPS strategy command";
CM_ SG_ 250 BCMFpsFailSts "This signal is used to give information of a fault present on the FPS sensing device.";
CM_ SG_ 250 BrakePedalSwitchNCFailSts "Brake pedal switch CAN signals cannot be used by receiver";
CM_ SG_ 250 BrakePedalSwitchNCSts "It is the Redundant Brake Switch (Normally Closed) position status, acquired by BCM and transmitted on CAN.";
CM_ SG_ 250 BrakePedalSwitchNOFailSts "Brake pedal switch CAN signals cannot be used by receiver";
CM_ SG_ 250 BrakePedalSwitchNOSts "It is the Brake Light Switch (Normally Open) position status, acquired by BCM and transmitted on CAN.";
CM_ SG_ 250 EngineOffRequest "The signal is used to require an  engine shut off";
CM_ SG_ 250 KeyInIgnSts "Key in ignition status";
CM_ SG_ 250 MessageCounter_BC "This signal is a counter used for safety checks strategies. This counter is incremented of 1 (one) unit at each frame transmission.";
CM_ SG_ 250 StartRelayBCMFault "BCM starter relay fault detected";
CM_ SG_ 250 StartRelayBCMSts "BCM starter relay status; [1] = ON";
CM_ SG_ 250 TurnIndicatorSts "The signal is used to indicate the turn indicator position.";
CM_ SG_ 245 MinicryptReceptionSts "This signal is used to give an acknowledge on specific message reception.";
CM_ SG_ 1446 A2D_DRV_TEMP_DR_POS "Transmit raw A/D driver temp door position to ECM, the information is used to make OBD model more robust";
CM_ SG_ 1446 A2D_FT_HVAC_BLOWER_VOLTAGE "Transmit raw A/D blower voltage to ECM, the information is used to make OBD model more robust";
CM_ SG_ 1446 AcOutputCurrentSts "It is the ECVD electrovalve current";
CM_ SG_ 1446 StopStartClimateInfo "HVAC conditions effecting stop start enable";
CM_ SG_ 748 FrontWiperMoveSts "This signal indicates the position of the front wiper (contact cam open or close)";
CM_ SG_ 748 RemStartActiveEPB "This signal is used for EPB activation request for remote start functionality";
CM_ SG_ 900 DriveStyleSts "This signal gives indications about drive style status required.";
CM_ SG_ 900 ESCFnRqstSts "This signal is used by BCM to comunicate the status of ESC button";
CM_ SG_ 900 Int_Relay_FailSts "Used to indicate an anomaly on the INT.Relay device";
CM_ SG_ 900 SuspensionLevel "This signal gives indications about Suspension status required";
CM_ SG_ 1349 ChkFuelLevelSts "Used to give information about the diagnostic of CILC.";
CM_ SG_ 1349 ExternalTemperatureAD_Voltage "Indicates the raw voltage of the ambient temp sensor";
CM_ SG_ 1349 FuelLevel "Used to give information about the percentage of the fuel level present in the tank.";
CM_ SG_ 1349 FuelLevelFailSts "Used to give information about the fail status of the FuelLevel signal.";
CM_ SG_ 1349 InternalLightLevel "Used to give information about the backlight dimming level selected.";
CM_ SG_ 1349 InternalLightSts "Used to give information about backlight mode selected (Day or Night).";
CM_ SG_ 1349 NotFilteredFuelLevel "Used to give information about the not filtered fuell level value in ohm.";
CM_ SG_ 1201 BonnetFailSts "Signal used to inform other systems about an electric fault on bonnet ajar switch.";
CM_ SG_ 1201 BonnetSts "Used to give information about the bonnet status";
CM_ SG_ 1201 CompressorACReqSts "This signal is sent from BCM to ECM to inform of Compressor AC activation request";
CM_ SG_ 1201 DriverDoorFailSts "Signal used to inform other systems about an electric fault on driver ajar switch.";
CM_ SG_ 1201 DriverDoorSts "This signal indicates the driver door status";
CM_ SG_ 1201 ExteriorRearReleaseSwitchSts "Used to give rear access button press info to the body controller to allow releasing the rear access point";
CM_ SG_ 1201 FOBSearchRequest "Signal used to request the FOB searching.";
CM_ SG_ 1201 LockUnlockVehicle "Signal used to inform about the locked/unlocked status of the vehicle.";
CM_ SG_ 1201 PsngrDoorSts "This signal indicates the passenger door status";
CM_ SG_ 1201 RemSt_InhibitSts "Remote start inhibit";
CM_ SG_ 1201 RemStActvSts "Type of start being requested";
CM_ SG_ 1201 SpSt_Pad1 "Stop Start Button Press 1";
CM_ SG_ 1201 SpSt_Pad2 "Stop Start Button Press 2";
CM_ SG_ 1201 SteeringWheelButton2Sts "Steering wheel button 2 Status.";
CM_ SG_ 1201 TheftAlarmStatus "VTA status";
CM_ SG_ 1049 BonnetAjarRawValSts "The signal gives info on Bonnet ajar input to engine controller to use for stop-start and do diagnosis in the engine controller.";
CM_ SG_ 1049 FUEL_VOLT "Used to give information about the not filtered fuell level value in volt.";
CM_ SG_ 1049 FUEL_VOLT2 "Sub Side Fuel level sensor A/D Voltage (saddle/Dual tank)";
CM_ SG_ 1049 RHatchAjarRawValSts "The signal gives info on RHatch ajar input to engine controller to use for stop-start and do diagnosis in the engine controller.";
CM_ SG_ 257 ABSActive "This signal is set to Active when the ABS functionality is active.";
CM_ SG_ 257 BrakeInterventionSts "This signal is ?active? when the brake intervention is due to ESC, ASR, ACC systems and ?not active? when the brake intervention is due to the driver.";
CM_ SG_ 257 BSMShiftInterference "With this signal the BSMcan ask to Automatic/Robotic gearbox to prohibits the gear change during ASR/ESC manoeuvre.This signal is only available on ESC variant";
CM_ SG_ 257 CRC_B1 "CRC according to SAE J1850 standard that has to be calculated from bit 63 to bit 8 at each frame transmission.";
CM_ SG_ 257 ESCActive "This signal is set to Active when the brake intervention by ESC is active.";
CM_ SG_ 257 MasterCylinderPressure "This signal indicates the unfiltered sensor signal of the Master Cylinder Pressure. This signal is only available on ESC variant";
CM_ SG_ 257 MessageCounter_B1 "This signal is a counter used for safety checks strategies. This counter is incremented of 1 (one) unit at each frame transmission.";
CM_ SG_ 257 PrefillActive "This signal indicates the prefill function status.";
CM_ SG_ 257 VehicleSpeedVSOSig "It is the average vehicle speed calculated.";
CM_ SG_ 257 VehicleSpeedVSOSigFailSts "It is the average vehicle speed fail status.";
CM_ SG_ 506 BrkPrss_One "Brake Pressure One (P1) / Raw Unfiltered Primary Pressure";
CM_ SG_ 506 HSA_BrkPrss "Hill Start Assistant brake pressure needed";
CM_ SG_ 506 HSA_BrkPrssFailSts "Hill Start Assistant brake pressure Fail Status";
CM_ SG_ 263 Bleeding_Warning "Bleeding Warning Indication";
CM_ SG_ 263 BrakeFluidLevelSts_BSM "This signal indicates when the brake fluid level is low or normal";
CM_ SG_ 263 BrakeTravelFailSts "This signal indicate the Fail Status of brake pedal travel information";
CM_ SG_ 263 BrakeTravelSts "This signal indicate the brake pedal travel .";
CM_ SG_ 263 CRC_B11 "CRC according to SAE J1850 standard that has to be calculated from bit 63 to bit 8 at each frame transmission.";
CM_ SG_ 263 DiskWearLamp "The signal indicates the Brake Disk Wear Lamp request";
CM_ SG_ 263 EPB_Pad_Wear "This signal indicate the status of EPB Pad Wear";
CM_ SG_ 263 FrontDiskTemp "The signal indicates the Front disk temperature";
CM_ SG_ 263 FrontDiskWear "This signal indicates when the brake wear percentage relative to the initial  disck weight";
CM_ SG_ 263 Hot_Disk_Warning "Hot Disk Warning Indication";
CM_ SG_ 263 MessageCounter_B11 "This signal is a counter used for safety checks strategies. This counter is incremented of 1 (one) unit at each frame transmission.";
CM_ SG_ 263 Reactivation_Warning "Reactivation Warning Indication";
CM_ SG_ 263 RearDiskTemp "The signal indicates the Rear disk temperature";
CM_ SG_ 263 RearDiskWear "This signal indicates when the brake wear percentage relative to the initial  disck weight";
CM_ SG_ 259 TorqReq_CDCM_Active "Torque Request from CDCM is active and applied with high priority";
CM_ SG_ 259 TorqueRequest_FAST "This signal indicate the FAST engine torque request, used at high µ when the traction control intervention is short";
CM_ SG_ 501 VehicleStandStillSts "This signal indicates if the car is in stand still condition";
CM_ SG_ 1048 TravelDistance "This signal indicates the travel distance value.";
CM_ SG_ 1199 ABSCheck "This signal is used to discriminate the ABS check lamp from a real system fail";
CM_ SG_ 1199 BSMSysSts "This signal is used by BSM to indicate its mode";
CM_ SG_ 1199 EBDCheck "This signal is used to discriminate the EBD check lamp from a real system fail";
CM_ SG_ 1199 ERMActive "This signal is set to \"active\" when Electronic Roll Mitigation functionality is acting.";
CM_ SG_ 1199 ESCCheck "This signal is used to discriminate the ESC check lamp from a real system fail";
CM_ SG_ 1199 ESCOFFAvailability "This signal is used to activate the ESC_OFF_Not_Available cluster indications";
CM_ SG_ 1199 ESCOFFLamp "This signal is used for Esc Off Lamp activation";
CM_ SG_ 1199 RollsModeAct "This signal indicates when the brake system module is in the Rolls Test mode.";
CM_ SG_ 1199 TSCActive "This signal is set to \"active\" when Trailer Sway Control functionality is acting";
CM_ SG_ 284 CRC_BVM "CRC according to SAE J1850 standard that has to be calculated from bit 63 to bit 8 at each frame transmission";
CM_ SG_ 284 MessageCounter_BVM "This signal is a counter used for safety checks strategies. This counter is incremented of 1 (one) unit at each frame transmission.";
CM_ SG_ 284 Stabi_Index "Vehicle Stability Index";
CM_ SG_ 284 YawRateRef "reference yaw rate";
CM_ SG_ 284 YawRateStat "stationary yaw rate";
CM_ SG_ 254 CRC_BYD "CRC according to SAE J1850 standard that has to be calculated from bit 63 to bit 8 at each frame transmission.";
CM_ SG_ 254 InternalError_BSM "This signal indicates if an internal error has been processed";
CM_ SG_ 254 LatAcceleration_BSM "This signal indicates the Lateral Acceleration Value";
CM_ SG_ 254 LatAccelerationFailSts_BSM "This signal indicates the status of Lateral Acceleration Signal";
CM_ SG_ 254 LongAcceleration_BSM "This signal indicates the Longitudinal Acceleration Value";
CM_ SG_ 254 LongAccelerationFailSts_BSM "This signal indicates the status of Longitudinal acceleration signal";
CM_ SG_ 254 MessageCounter_BYD "This signal is a counter used for safety checks strategies. This counter is incremented of 1 (one) unit at each frame transmission.";
CM_ SG_ 254 Slope "Slope value detected by BSM";
CM_ SG_ 254 YawRate_BSM "This signal indicates the Yaw Rate Value";
CM_ SG_ 254 YawRateFailSts_BSM "This signal indicates the Status of Yaw Rate Signal";
CM_ SG_ 750 SteeringColumnTorque "Steering column torque signal provided by EPS torque sensor, counterclockwise positive [Nm]";
CM_ SG_ 280 MessageCounter_TVM "This signal is a counter used for safety checks strategies. This counter is incremented of 1 (one) unit at each frame transmission.";
CM_ SG_ 280 R_Diff_Mode_Req "This signal gives the information about the requested E-diff mode";
CM_ SG_ 280 R_Diff_Trq_Req "This signal gives the information about the requested E-diff torque";
CM_ SG_ 288 CRC_EC "CRC according to SAE J1850 standard that has to be calculated from bit 63 to bit 8 at each frame transmission";
CM_ SG_ 288 MessageCounter_EC "This signal is a counter used for safety checks strategies. This counter is incremented of 1 (one) unit at each frame transmission.";
CM_ SG_ 601 TotalOdometer "Used to give information about the total odometer value in km.";
CM_ SG_ 598 ABSLamp_FailSts "This signal communicates the status of the related lamp.";
CM_ SG_ 598 AirBagLamp_FailSts "This signal is used to inform about the airbag warning light status";
CM_ SG_ 598 DistanceUnit "Used to give information about the distance unit selected.";
CM_ SG_ 598 EBDLamp_FailSts "This signal communicates the status of the related lamp.";
CM_ SG_ 598 EPBAutoAppReqSts "This signal communicates the status of the activation of the functionality AutoApply of the EPB";
CM_ SG_ 598 EPBLamp_FailSts "This signal communicates the status of the related lamp.";
CM_ SG_ 598 EPBMaintenanceReqSts "Request of Activation Maintenance Mode";
CM_ SG_ 598 ESCLamp_FailSts "This signal communicates the status of the related lamp.";
CM_ SG_ 598 HandsFreeEnable "Hands Free setting in menù";
CM_ SG_ 598 HHDisablingCommandSts "This signal requires the disabling of Hill Holder functionality.";
CM_ SG_ 598 PassiveEntry "This signal is used to give information about the Passive Entry selected.";
CM_ SG_ 598 PsngrBagRequestSts "This signal is used by IPC to send the request of the customer to change the current status of Front Passenger Protection";
CM_ SG_ 598 RemoteDoorUnlock "This signal is used to give information about the Remote Door Unlock selected.";
CM_ SG_ 2564554481 N_PDU "This signal is used for diagnostic purposes";
CM_ SG_ 2564440305 N_PDU "This signal is used for diagnostic purposes";
CM_ SG_ 2564434161 N_PDU "This signal is used for diagnostic purposes";
CM_ SG_ 2564432113 N_PDU "This signal is used for diagnostic purposes";
CM_ SG_ 2564428017 N_PDU "This signal is used for diagnostic purposes";
CM_ SG_ 2564436209 N_PDU "This signal is used for diagnostic purposes";
CM_ SG_ 2564502513 N_PDU "This signal is used for diagnostic purposes";
CM_ SG_ 2564448497 N_PDU "-";
CM_ SG_ 2564473073 N_PDU "This signal is used for diagnostic purposes";
CM_ SG_ 2564464881 N_PDU "This signal is used for diagnostic purposes";
CM_ SG_ 2564474865 N_PDU "This signal is used for diagnostic purposes";
CM_ SG_ 2564474609 N_PDU "This signal is used for diagnostic purposes";
CM_ SG_ 2564430065 N_PDU "This signal is used for diagnostic purposes";
CM_ SG_ 2564485440 N_PDU "This signal is used for diagnostic purposes";
CM_ SG_ 2564485392 N_PDU "This signal is used for diagnostic purposes";
CM_ SG_ 2564485472 N_PDU "-";
CM_ SG_ 2564485575 N_PDU "This signal is used for diagnostic purposes";
CM_ SG_ 2564485672 N_PDU "This signal is used for diagnostic purposes";
CM_ SG_ 2564485664 N_PDU "This signal is used for diagnostic purposes";
CM_ SG_ 2564485680 N_PDU "This signal is used for diagnostic purposes";
CM_ SG_ 2564485824 N_PDU "This signal is used for diagnostic purposes";
CM_ SG_ 2564485792 N_PDU "This signal is used for diagnostic purposes";
CM_ SG_ 2564485574 N_PDU "This signal is used for diagnostic purposes";
CM_ SG_ 2564485400 N_PDU "This signal is used for diagnostic purposes";
CM_ SG_ 1846 BrkSw1Stat "EDR ONLY - Brake switch1 status, off = [0]";
CM_ SG_ 1846 BrkSw2Stat "EDR ONLY - Brake switch2 status, off = [0]";
CM_ SG_ 1846 ESP_TrqRqEnabl "EDR ONLY - ESP torque requests are allowed = [1]";
CM_ SG_ 1846 Lv1CrsCtrlOff "EDR ONLY - Level is requested cruise off";
CM_ SG_ 1846 RawPVS1 "EDR ONLY - Raw pedal value sensor #1";
CM_ SG_ 1846 RawPVS2 "EDR ONLY - Raw pedal value sensor #2";
CM_ SG_ 1846 RawTPS1 "EDR ONLY - Raw throttle position sensor #1";
CM_ SG_ 1846 RawTPS2 "EDR ONLY - Raw throttle position sensor #2";
CM_ SG_ 1422 DriverDoor2AjarRawValSts "This signal is used to give information about the Driver Door Aux Pawl RAW current data.";
CM_ SG_ 1422 DriverDoor3AjarRawValSts "This signal is used to give information about the Driver Door digital Pawl RAW current data.";
CM_ SG_ 1422 DriverDoor4AjarRawValSts "This signal is used to give information about the Driver Door digital Open sensor RAW current data.";
CM_ SG_ 1422 DriverDoorAjarRawValSts "This signal is used to give information about the Driver Door Ajar RAW current data.";
CM_ SG_ 1422 DrvDoorLatchDeadLockSts "This signal is used to give information about the deadlock\undeadlock of the LSMD latch status";
CM_ SG_ 1422 DrvDoorLatchSts "This signal is used to give information about the lock\unlock of the LSMD latch status";
CM_ SG_ 1422 E1DriverDoorSts "This signal is used to give information about the open\close of the driver door status";
CM_ SG_ 1422 LSMDAjarSensorFailSts "This signal is used to give information about the fault on the driver door ajar sensor";
CM_ SG_ 1422 LSMDCrashLineFailSts "This signal is used to give information about crash line fail of the LSMD";
CM_ SG_ 1422 LSMDExternalLockReleaseSwitchFai "This signal is used to give information about the fault on the driver external lock or release switch";
CM_ SG_ 1422 LSMDFobSearchReq "This signal is used to require the key fob search for driver door release or for central doors lock from driver door external handle.";
CM_ SG_ 1422 LSMDInternalFailSts "This signal is used to give information about generic internal fail of the LSMD";
CM_ SG_ 1422 LSMDInternalLockLightFailSts "This signal is used to give information about the fault on the driver internal lock switch light";
CM_ SG_ 1422 LSMDInternalReleaseSwitchFailSts "This signal is used to give information about the fault on the  driver internal release switch";
CM_ SG_ 1422 LSMDInternalUnlockLightFailSts "This signal is used to give information about the fault on the driver internal unlock switch light";
CM_ SG_ 1422 LSMDReleaseLockReq "This signal is used to require the lock of the driver door latch";
CM_ SG_ 1422 LSMDTrunkDisableReq "This signal is used to require the trunk external handle disabling from driver door switch";
CM_ SG_ 1424 E2PsngrDoorSts "This signal is used to give information about the open\close of the passenger door status";
CM_ SG_ 1424 LSMPAjarSensorFailSts "This signal is used to give information about the fault on the passenger door ajar sensor";
CM_ SG_ 1424 LSMPCrashLineFailSts "This signal is used to give information about crash line fail of the LSMP";
CM_ SG_ 1424 LSMPExternalLockReleaseSwitchFai "This signal is used to give information about the fault on the passenger external lock or release switch";
CM_ SG_ 1424 LSMPFobSearchReq "This signal is used to require the key fob search for passenger door release or for central doors lock from passenger door external handle.";
CM_ SG_ 1424 LSMPInternalFailSts "This signal is used to give information about generic internal fail of the LSMP";
CM_ SG_ 1424 LSMPInternalLockLightFailSts "This signal is used to give information about the fault on the passenger internal lock switch light";
CM_ SG_ 1424 LSMPInternalReleaseSwitchFailSts "This signal is used to give information about the fault on the  passenger internal release switch";
CM_ SG_ 1424 LSMPInternalUnlockLightFailSts "This signal is used to give information about the fault on the passenger internal unlock switch light";
CM_ SG_ 1424 LSMPReleaseLockReq "This signal is used to require the lock of the passenger door latch";
CM_ SG_ 1424 LSMPTrunkDisableReq "This signal is used to require the trunk external handle disabling from passenger door switch";
CM_ SG_ 1424 PsngrDoorLatchDeadLockSts "This signal is used to give information about the deadlock\undeadlock of the LSMP latch status";
CM_ SG_ 1424 PsngrDoorLatchSts "This signal is used to give information about the lock\unlock of the LSMP latch status";
CM_ SG_ 252 AlternatorFail "Indicates if the alternator is in fail condition";
CM_ SG_ 252 CC_BrakeIntervention "This Signal indicated the deceleration target required by ECM for CC and SL function";
CM_ SG_ 252 CC_BrakeIntervention_Req "This Signal indicated the request for Brake Interventio  by ECM for CC and SL function";
CM_ SG_ 252 EngineSpeed "It gives inforrmation on C-CAN network about  engine speed";
CM_ SG_ 252 EngineSpeedFailSts "Used to indicate if a Fail is present for the engine speed";
CM_ SG_ 252 NeutralSwSts "Used to give information about Transmission Neutral status";
CM_ SG_ 252 ReverseGearSts "Used to give information about Reverse Gear status";
CM_ SG_ 1445 CC_SetSpdDspl_KPH "Cruise Control Vehicle Set Speed in Kilometer Per Hour";
CM_ SG_ 1445 CruiseControlLampSts "It is the cruise control light command";
CM_ SG_ 1445 CruiseControlSts "It gives information  on C-CAN network about the actual status of cruise control function.";
CM_ SG_ 1445 HMIDisplay_CC "HMI Code for CC functionality";
CM_ SG_ 1202 Bonnet2FailSts "Signal used to inform other systems about an electric fault on the right bonnet ajar switch";
CM_ SG_ 1202 Bonnet2Sts "Used to give information about the right bonnet ajar switch";
CM_ SG_ 1202 EngineOilPressure "Engine Oil Pressure";
CM_ SG_ 1202 EngineOilTemp_WarningLight "Engine Oil Temperature Warning Light";
CM_ SG_ 1202 EngineOilTemperature "Engine Oil Temperature";
CM_ SG_ 1202 PowerModeSts_ECM "Logistic Mode Status";
BA_DEF_ SG_  "Accuracy" STRING ;
BA_DEF_ SG_  "Event trans." ENUM  "Yes","No";
BA_DEF_ SG_  "GenSigStartValue" INT 0 2147483647;
BA_DEF_ SG_  "GenSigInactiveValue" INT 0 2147483647;
BA_DEF_ SG_  "GenSigSendType" ENUM  "NotUsed","OnWrite","OnWriteWithRepetition","OnChange","OnChangeWithRepetition","IfActive","IfActiveWithRepetition","NoSigSendType";
BA_DEF_ BO_  "DiagRequest" ENUM  "No","Yes";
BA_DEF_ BO_  "Period [ms]" INT 0 65535;
BA_DEF_ BO_  "Type" ENUM  "P","C","PE","COC","PE_Cntrl","E","E_Cntrl","OC","S","BAF","DC","EM","MM","-";
BA_DEF_ BO_  "DiagResponse" ENUM  "No","Yes";
BA_DEF_ BO_  "NmMessage" ENUM  "No","Yes";
BA_DEF_ BO_  "GenMsgSendType" ENUM  "Cyclic","NotUsed","NotUsed","NotUsed","NotUsed","NotUsed","NotUsed","NotUsed","NoMsgSendType";
BA_DEF_ BO_  "GenMsgTimeoutTime" INT 0 10000;
BA_DEF_ BO_  "GenMsgNrOfRepetition" INT 0 255;
BA_DEF_ BO_  "GenMsgILSupport" ENUM  "No","Yes";
BA_DEF_ BO_  "GenMsgStartDelayTime" INT 0 65535;
BA_DEF_ BO_  "GenMsgCycleTimeFast" INT 0 65535;
BA_DEF_ BO_  "GenMsgCycleTime" INT 0 65535;
BA_DEF_ BO_  "GenMsgDelayTime" INT 0 65535;
BA_DEF_ BO_  "DiagState" ENUM  "No","Yes";
BA_DEF_ BU_  "NodeLayerModules" STRING ;
BA_DEF_ BU_  "Description" STRING ;
BA_DEF_ BU_  "NmStationAddress" HEX 0 255;
BA_DEF_ BU_  "NmNode" ENUM  "No","Yes";
BA_DEF_ BU_  "ILUsed" ENUM  "No","Yes";
BA_DEF_ BU_  "NmNodeType" ENUM  "kMaster","kSlave15","kSlave30","none";
BA_DEF_ BU_  "NwmNodeType" ENUM  "kMaster","kSlave15","kSlave30","none";
BA_DEF_ BU_  "TpOwnSystemEcuNumber" HEX 0 255;
BA_DEF_  "Manufacturer" STRING ;
BA_DEF_  "NmType" STRING ;
BA_DEF_  "BusType" STRING ;
BA_DEF_  "Baudrate" INT 0 1000000;
BA_DEF_  "DBName" STRING ;
BA_DEF_  "Version" HEX 0 255;
BA_DEF_  "VersionWeek" INT 0 53;
BA_DEF_  "VersionYear" INT 0 99;
BA_DEF_ SG_  "SystemSignalLongSymbol" STRING ;
BA_DEF_DEF_  "Accuracy" "";
BA_DEF_DEF_  "Event trans." "No";
BA_DEF_DEF_  "GenSigStartValue" 0;
BA_DEF_DEF_  "GenSigInactiveValue" 0;
BA_DEF_DEF_  "GenSigSendType" "NoSigSendType";
BA_DEF_DEF_  "DiagRequest" "No";
BA_DEF_DEF_  "Period [ms]" 0;
BA_DEF_DEF_  "Type" "-";
BA_DEF_DEF_  "DiagResponse" "No";
BA_DEF_DEF_  "NmMessage" "No";
BA_DEF_DEF_  "GenMsgSendType" "NoMsgSendType";
BA_DEF_DEF_  "GenMsgTimeoutTime" 0;
BA_DEF_DEF_  "GenMsgNrOfRepetition" 0;
BA_DEF_DEF_  "GenMsgILSupport" "No";
BA_DEF_DEF_  "GenMsgStartDelayTime" 0;
BA_DEF_DEF_  "GenMsgCycleTimeFast" 0;
BA_DEF_DEF_  "GenMsgCycleTime" 0;
BA_DEF_DEF_  "GenMsgDelayTime" 0;
BA_DEF_DEF_  "DiagState" "No";
BA_DEF_DEF_  "NodeLayerModules" "Osek_TP.dll";
BA_DEF_DEF_  "Description" "";
BA_DEF_DEF_  "NmStationAddress" 0;
BA_DEF_DEF_  "NmNode" "Yes";
BA_DEF_DEF_  "ILUsed" "Yes";
BA_DEF_DEF_  "NmNodeType" "none";
BA_DEF_DEF_  "NwmNodeType" "none";
BA_DEF_DEF_  "TpOwnSystemEcuNumber" 0;
BA_DEF_DEF_  "Manufacturer" "Fiat";
BA_DEF_DEF_  "NmType" "";
BA_DEF_DEF_  "BusType" "CAN";
BA_DEF_DEF_  "Baudrate" 500000;
BA_DEF_DEF_  "DBName" "CAN";
BA_DEF_DEF_  "Version" 160;
BA_DEF_DEF_  "VersionWeek" 44;
BA_DEF_DEF_  "VersionYear" 19;
BA_DEF_DEF_  "SystemSignalLongSymbol" "";
BA_ "Manufacturer" "BEG";
BA_ "NmType" "Fiat_Class_C";
BA_ "DBName" "CANC1";
BA_ "NmStationAddress" BU_ NotUsed 255;
BA_ "NmStationAddress" BU_ HYS_EX 172;
BA_ "NmStationAddress" BU_ ABS_M5 171;
BA_ "NmStationAddress" BU_ DDU10 170;
BA_ "Description" BU_ BCM "Body Control Module";
BA_ "NmNodeType" BU_ BCM 0;
BA_ "NwmNodeType" BU_ BCM 0;
BA_ "TpOwnSystemEcuNumber" BU_ BCM 64;
BA_ "Description" BU_ BSM "Braking System Module";
BA_ "NmStationAddress" BU_ BSM 6;
BA_ "NmNodeType" BU_ BSM 2;
BA_ "NwmNodeType" BU_ BSM 2;
BA_ "TpOwnSystemEcuNumber" BU_ BSM 40;
BA_ "Description" BU_ CDCM "Chassis Domain Control Module";
BA_ "NmStationAddress" BU_ CDCM 102;
BA_ "NmNodeType" BU_ CDCM 1;
BA_ "NwmNodeType" BU_ CDCM 1;
BA_ "TpOwnSystemEcuNumber" BU_ CDCM 32;
BA_ "Description" BU_ DCTM "Dual Clutch Transmission Module";
BA_ "NmStationAddress" BU_ DCTM 11;
BA_ "NmNodeType" BU_ DCTM 2;
BA_ "NwmNodeType" BU_ DCTM 2;
BA_ "TpOwnSystemEcuNumber" BU_ DCTM 24;
BA_ "Description" BU_ DIAG_TEST "Diagnostic Tester";
BA_ "Description" BU_ ECM "Engine Control Module";
BA_ "NmStationAddress" BU_ ECM 1;
BA_ "NmNodeType" BU_ ECM 2;
BA_ "NwmNodeType" BU_ ECM 2;
BA_ "TpOwnSystemEcuNumber" BU_ ECM 16;
BA_ "Description" BU_ IPC "Instrument Panel Cluster";
BA_ "NmStationAddress" BU_ IPC 3;
BA_ "NmNodeType" BU_ IPC 2;
BA_ "NwmNodeType" BU_ IPC 2;
BA_ "TpOwnSystemEcuNumber" BU_ IPC 96;
BA_ "Description" BU_ ORC "Occupant Restraint Control";
BA_ "NmStationAddress" BU_ ORC 26;
BA_ "NmNodeType" BU_ ORC 1;
BA_ "NwmNodeType" BU_ ORC 1;
BA_ "TpOwnSystemEcuNumber" BU_ ORC 192;
BA_ "Description" BU_ RFHM "Radio Frequency Hub Module";
BA_ "NmStationAddress" BU_ RFHM 65;
BA_ "NmNodeType" BU_ RFHM 2;
BA_ "NwmNodeType" BU_ RFHM 2;
BA_ "TpOwnSystemEcuNumber" BU_ RFHM 199;
BA_ "Description" BU_ TBM "Telematic Box Module";
BA_ "NmStationAddress" BU_ TBM 35;
BA_ "NmNodeType" BU_ TBM 2;
BA_ "NwmNodeType" BU_ TBM 2;
BA_ "TpOwnSystemEcuNumber" BU_ TBM 198;
BA_ "Period [ms]" BO_ 1345 10;
BA_ "GenMsgSendType" BO_ 1345 0;
BA_ "GenMsgCycleTime" BO_ 1345 10;
BA_ "Period [ms]" BO_ 1376 10;
BA_ "GenMsgSendType" BO_ 1376 0;
BA_ "GenMsgCycleTime" BO_ 1376 10;
BA_ "Period [ms]" BO_ 834 10;
BA_ "GenMsgSendType" BO_ 834 0;
BA_ "GenMsgCycleTime" BO_ 834 10;
BA_ "Period [ms]" BO_ 798 100;
BA_ "GenMsgSendType" BO_ 798 0;
BA_ "GenMsgCycleTime" BO_ 798 100;
BA_ "Period [ms]" BO_ 542 100;
BA_ "GenMsgSendType" BO_ 542 0;
BA_ "GenMsgCycleTime" BO_ 542 100;
BA_ "Period [ms]" BO_ 538 100;
BA_ "GenMsgSendType" BO_ 538 0;
BA_ "GenMsgCycleTime" BO_ 538 100;
BA_ "Period [ms]" BO_ 1472 10;
BA_ "GenMsgSendType" BO_ 1472 0;
BA_ "GenMsgCycleTime" BO_ 1472 10;
BA_ "Period [ms]" BO_ 1346 10;
BA_ "GenMsgSendType" BO_ 1346 0;
BA_ "GenMsgCycleTime" BO_ 1346 10;
BA_ "Period [ms]" BO_ 833 10;
BA_ "GenMsgSendType" BO_ 833 0;
BA_ "GenMsgCycleTime" BO_ 833 10;
BA_ "Period [ms]" BO_ 832 10;
BA_ "GenMsgSendType" BO_ 832 0;
BA_ "GenMsgCycleTime" BO_ 832 10;
BA_ "Period [ms]" BO_ 323 10;
BA_ "GenMsgSendType" BO_ 323 0;
BA_ "GenMsgCycleTime" BO_ 323 10;
BA_ "Period [ms]" BO_ 322 10;
BA_ "GenMsgSendType" BO_ 322 0;
BA_ "GenMsgCycleTime" BO_ 322 10;
BA_ "Period [ms]" BO_ 321 10;
BA_ "GenMsgSendType" BO_ 321 0;
BA_ "GenMsgCycleTime" BO_ 321 10;
BA_ "Period [ms]" BO_ 320 10;
BA_ "GenMsgSendType" BO_ 320 0;
BA_ "GenMsgCycleTime" BO_ 320 10;
BA_ "Period [ms]" BO_ 588 10;
BA_ "GenMsgSendType" BO_ 588 0;
BA_ "GenMsgCycleTime" BO_ 588 10;
BA_ "Period [ms]" BO_ 380 10;
BA_ "GenMsgSendType" BO_ 380 0;
BA_ "GenMsgCycleTime" BO_ 380 10;
BA_ "Period [ms]" BO_ 376 10;
BA_ "GenMsgSendType" BO_ 376 0;
BA_ "GenMsgCycleTime" BO_ 376 10;
BA_ "Period [ms]" BO_ 372 10;
BA_ "GenMsgSendType" BO_ 372 0;
BA_ "GenMsgCycleTime" BO_ 372 10;
BA_ "Period [ms]" BO_ 1568 100;
BA_ "GenMsgSendType" BO_ 1568 0;
BA_ "GenMsgCycleTime" BO_ 1568 100;
BA_ "Period [ms]" BO_ 490 20;
BA_ "GenMsgSendType" BO_ 490 0;
BA_ "GenMsgCycleTime" BO_ 490 20;
BA_ "Period [ms]" BO_ 491 20;
BA_ "GenMsgSendType" BO_ 491 0;
BA_ "GenMsgCycleTime" BO_ 491 20;
BA_ "Period [ms]" BO_ 492 20;
BA_ "GenMsgSendType" BO_ 492 0;
BA_ "GenMsgCycleTime" BO_ 492 20;
BA_ "Period [ms]" BO_ 531 10;
BA_ "GenMsgSendType" BO_ 531 0;
BA_ "GenMsgCycleTime" BO_ 531 10;
BA_ "Period [ms]" BO_ 530 10;
BA_ "GenMsgSendType" BO_ 530 0;
BA_ "GenMsgCycleTime" BO_ 530 10;
BA_ "Period [ms]" BO_ 528 20;
BA_ "GenMsgSendType" BO_ 528 0;
BA_ "GenMsgCycleTime" BO_ 528 20;
BA_ "GenMsgSendType" BO_ 532 0;
BA_ "Period [ms]" BO_ 532 20;
BA_ "GenMsgCycleTime" BO_ 532 20;
BA_ "Period [ms]" BO_ 1593 100;
BA_ "GenMsgSendType" BO_ 1593 0;
BA_ "GenMsgCycleTime" BO_ 1593 100;
BA_ "Period [ms]" BO_ 1592 100;
BA_ "GenMsgSendType" BO_ 1592 0;
BA_ "GenMsgCycleTime" BO_ 1592 100;
BA_ "Period [ms]" BO_ 599 100;
BA_ "Type" BO_ 599 3;
BA_ "GenMsgSendType" BO_ 599 0;
BA_ "GenMsgNrOfRepetition" BO_ 599 2;
BA_ "GenMsgILSupport" BO_ 599 1;
BA_ "GenMsgStartDelayTime" BO_ 599 20;
BA_ "GenMsgCycleTimeFast" BO_ 599 20;
BA_ "GenMsgCycleTime" BO_ 599 100;
BA_ "GenMsgDelayTime" BO_ 599 10;
BA_ "Period [ms]" BO_ 1447 1000;
BA_ "Type" BO_ 1447 3;
BA_ "GenMsgSendType" BO_ 1447 0;
BA_ "GenMsgTimeoutTime" BO_ 1447 2500;
BA_ "GenMsgILSupport" BO_ 1447 1;
BA_ "GenMsgStartDelayTime" BO_ 1447 230;
BA_ "GenMsgCycleTime" BO_ 1447 1000;
BA_ "GenMsgDelayTime" BO_ 1447 50;
BA_ "Period [ms]" BO_ 1050 100;
BA_ "Type" BO_ 1050 1;
BA_ "GenMsgSendType" BO_ 1050 0;
BA_ "GenMsgILSupport" BO_ 1050 1;
BA_ "GenMsgStartDelayTime" BO_ 1050 30;
BA_ "GenMsgCycleTime" BO_ 1050 100;
BA_ "Type" BO_ 247 8;
BA_ "GenMsgTimeoutTime" BO_ 247 2500;
BA_ "GenMsgILSupport" BO_ 247 1;
BA_ "GenMsgDelayTime" BO_ 247 10;
BA_ "Period [ms]" BO_ 250 10;
BA_ "Type" BO_ 250 1;
BA_ "GenMsgSendType" BO_ 250 0;
BA_ "GenMsgILSupport" BO_ 250 1;
BA_ "GenMsgCycleTime" BO_ 250 10;
BA_ "Period [ms]" BO_ 1994 1000;
BA_ "Type" BO_ 1994 1;
BA_ "GenMsgSendType" BO_ 1994 0;
BA_ "GenMsgTimeoutTime" BO_ 1994 2500;
BA_ "GenMsgILSupport" BO_ 1994 1;
BA_ "GenMsgStartDelayTime" BO_ 1994 300;
BA_ "GenMsgCycleTime" BO_ 1994 1000;
BA_ "Type" BO_ 245 8;
BA_ "GenMsgTimeoutTime" BO_ 245 2500;
BA_ "GenMsgILSupport" BO_ 245 1;
BA_ "GenMsgDelayTime" BO_ 245 10;
BA_ "Period [ms]" BO_ 1446 1000;
BA_ "Type" BO_ 1446 3;
BA_ "GenMsgSendType" BO_ 1446 0;
BA_ "GenMsgTimeoutTime" BO_ 1446 2500;
BA_ "GenMsgILSupport" BO_ 1446 1;
BA_ "GenMsgStartDelayTime" BO_ 1446 300;
BA_ "GenMsgCycleTime" BO_ 1446 1000;
BA_ "GenMsgDelayTime" BO_ 1446 50;
BA_ "Period [ms]" BO_ 748 50;
BA_ "Type" BO_ 748 1;
BA_ "GenMsgSendType" BO_ 748 0;
BA_ "GenMsgILSupport" BO_ 748 1;
BA_ "GenMsgStartDelayTime" BO_ 748 5;
BA_ "GenMsgCycleTime" BO_ 748 50;
BA_ "Period [ms]" BO_ 900 250;
BA_ "Type" BO_ 900 3;
BA_ "GenMsgSendType" BO_ 900 0;
BA_ "GenMsgILSupport" BO_ 900 1;
BA_ "GenMsgStartDelayTime" BO_ 900 15;
BA_ "GenMsgCycleTime" BO_ 900 250;
BA_ "GenMsgDelayTime" BO_ 900 20;
BA_ "Period [ms]" BO_ 1349 250;
BA_ "Type" BO_ 1349 1;
BA_ "GenMsgSendType" BO_ 1349 0;
BA_ "GenMsgILSupport" BO_ 1349 1;
BA_ "GenMsgStartDelayTime" BO_ 1349 60;
BA_ "GenMsgCycleTime" BO_ 1349 250;
BA_ "Period [ms]" BO_ 1201 500;
BA_ "Type" BO_ 1201 3;
BA_ "GenMsgSendType" BO_ 1201 0;
BA_ "GenMsgILSupport" BO_ 1201 1;
BA_ "GenMsgStartDelayTime" BO_ 1201 100;
BA_ "GenMsgCycleTime" BO_ 1201 500;
BA_ "GenMsgDelayTime" BO_ 1201 20;
BA_ "Period [ms]" BO_ 1049 100;
BA_ "Type" BO_ 1049 1;
BA_ "GenMsgSendType" BO_ 1049 0;
BA_ "GenMsgTimeoutTime" BO_ 1049 2500;
BA_ "GenMsgILSupport" BO_ 1049 1;
BA_ "GenMsgStartDelayTime" BO_ 1049 25;
BA_ "GenMsgCycleTime" BO_ 1049 100;
BA_ "Period [ms]" BO_ 257 10;
BA_ "Type" BO_ 257 1;
BA_ "GenMsgSendType" BO_ 257 0;
BA_ "GenMsgILSupport" BO_ 257 1;
BA_ "GenMsgStartDelayTime" BO_ 257 5;
BA_ "GenMsgCycleTime" BO_ 257 10;
BA_ "Period [ms]" BO_ 506 20;
BA_ "Type" BO_ 506 1;
BA_ "GenMsgSendType" BO_ 506 0;
BA_ "GenMsgILSupport" BO_ 506 1;
BA_ "GenMsgStartDelayTime" BO_ 506 10;
BA_ "GenMsgCycleTime" BO_ 506 20;
BA_ "Period [ms]" BO_ 263 10;
BA_ "Type" BO_ 263 1;
BA_ "GenMsgSendType" BO_ 263 0;
BA_ "GenMsgILSupport" BO_ 263 1;
BA_ "GenMsgCycleTime" BO_ 263 10;
BA_ "Period [ms]" BO_ 259 10;
BA_ "Type" BO_ 259 1;
BA_ "GenMsgSendType" BO_ 259 0;
BA_ "GenMsgILSupport" BO_ 259 1;
BA_ "GenMsgStartDelayTime" BO_ 259 5;
BA_ "GenMsgCycleTime" BO_ 259 10;
BA_ "Period [ms]" BO_ 501 20;
BA_ "Type" BO_ 501 1;
BA_ "GenMsgSendType" BO_ 501 0;
BA_ "GenMsgILSupport" BO_ 501 1;
BA_ "GenMsgStartDelayTime" BO_ 501 10;
BA_ "GenMsgCycleTime" BO_ 501 20;
BA_ "Period [ms]" BO_ 1048 100;
BA_ "Type" BO_ 1048 3;
BA_ "GenMsgSendType" BO_ 1048 0;
BA_ "GenMsgILSupport" BO_ 1048 1;
BA_ "GenMsgStartDelayTime" BO_ 1048 30;
BA_ "GenMsgCycleTime" BO_ 1048 100;
BA_ "GenMsgDelayTime" BO_ 1048 20;
BA_ "Period [ms]" BO_ 1199 500;
BA_ "Type" BO_ 1199 3;
BA_ "GenMsgSendType" BO_ 1199 0;
BA_ "GenMsgNrOfRepetition" BO_ 1199 2;
BA_ "GenMsgILSupport" BO_ 1199 1;
BA_ "GenMsgStartDelayTime" BO_ 1199 100;
BA_ "GenMsgCycleTimeFast" BO_ 1199 10;
BA_ "GenMsgCycleTime" BO_ 1199 500;
BA_ "GenMsgDelayTime" BO_ 1199 10;
BA_ "Period [ms]" BO_ 284 10;
BA_ "Type" BO_ 284 1;
BA_ "GenMsgSendType" BO_ 284 0;
BA_ "GenMsgTimeoutTime" BO_ 284 2500;
BA_ "GenMsgILSupport" BO_ 284 1;
BA_ "GenMsgCycleTime" BO_ 284 10;
BA_ "Period [ms]" BO_ 254 10;
BA_ "Type" BO_ 254 1;
BA_ "GenMsgSendType" BO_ 254 0;
BA_ "GenMsgTimeoutTime" BO_ 254 2500;
BA_ "GenMsgILSupport" BO_ 254 1;
BA_ "GenMsgStartDelayTime" BO_ 254 5;
BA_ "GenMsgCycleTime" BO_ 254 10;
BA_ "Period [ms]" BO_ 750 100;
BA_ "Type" BO_ 750 1;
BA_ "GenMsgSendType" BO_ 750 0;
BA_ "GenMsgTimeoutTime" BO_ 750 2500;
BA_ "GenMsgILSupport" BO_ 750 1;
BA_ "GenMsgStartDelayTime" BO_ 750 10;
BA_ "GenMsgCycleTime" BO_ 750 100;
BA_ "Period [ms]" BO_ 280 10;
BA_ "Type" BO_ 280 1;
BA_ "GenMsgSendType" BO_ 280 0;
BA_ "GenMsgILSupport" BO_ 280 1;
BA_ "GenMsgCycleTime" BO_ 280 10;
BA_ "Period [ms]" BO_ 288 10;
BA_ "Type" BO_ 288 1;
BA_ "GenMsgSendType" BO_ 288 0;
BA_ "GenMsgILSupport" BO_ 288 1;
BA_ "GenMsgStartDelayTime" BO_ 288 5;
BA_ "GenMsgCycleTime" BO_ 288 10;
BA_ "Type" BO_ 2651930624 8;
BA_ "GenMsgTimeoutTime" BO_ 2651930624 2500;
BA_ "GenMsgILSupport" BO_ 2651930624 1;
BA_ "GenMsgDelayTime" BO_ 2651930624 10;
BA_ "Type" BO_ 2651930625 11;
BA_ "GenMsgTimeoutTime" BO_ 2651930625 2500;
BA_ "GenMsgILSupport" BO_ 2651930625 1;
BA_ "Type" BO_ 2651930627 11;
BA_ "GenMsgILSupport" BO_ 2651930627 1;
BA_ "Type" BO_ 2651930689 11;
BA_ "GenMsgTimeoutTime" BO_ 2651930689 2500;
BA_ "GenMsgILSupport" BO_ 2651930689 1;
BA_ "Type" BO_ 2651930659 11;
BA_ "GenMsgTimeoutTime" BO_ 2651930659 2500;
BA_ "GenMsgILSupport" BO_ 2651930659 1;
BA_ "Type" BO_ 2651930635 11;
BA_ "GenMsgTimeoutTime" BO_ 2651930635 2500;
BA_ "GenMsgILSupport" BO_ 2651930635 1;
BA_ "Period [ms]" BO_ 601 100;
BA_ "Type" BO_ 601 3;
BA_ "GenMsgSendType" BO_ 601 0;
BA_ "GenMsgNrOfRepetition" BO_ 601 3;
BA_ "GenMsgILSupport" BO_ 601 1;
BA_ "GenMsgStartDelayTime" BO_ 601 50;
BA_ "GenMsgCycleTimeFast" BO_ 601 20;
BA_ "GenMsgCycleTime" BO_ 601 100;
BA_ "GenMsgDelayTime" BO_ 601 20;
BA_ "Period [ms]" BO_ 598 100;
BA_ "Type" BO_ 598 3;
BA_ "GenMsgSendType" BO_ 598 0;
BA_ "GenMsgILSupport" BO_ 598 1;
BA_ "GenMsgStartDelayTime" BO_ 598 20;
BA_ "GenMsgCycleTime" BO_ 598 100;
BA_ "GenMsgDelayTime" BO_ 598 20;
BA_ "Type" BO_ 2564554481 8;
BA_ "GenMsgTimeoutTime" BO_ 2564554481 2500;
BA_ "DiagState" BO_ 2564554481 1;
BA_ "DiagRequest" BO_ 2564440305 1;
BA_ "Type" BO_ 2564440305 8;
BA_ "DiagRequest" BO_ 2564434161 1;
BA_ "Type" BO_ 2564434161 8;
BA_ "DiagRequest" BO_ 2564432113 1;
BA_ "Type" BO_ 2564432113 8;
BA_ "DiagRequest" BO_ 2564428017 1;
BA_ "Type" BO_ 2564428017 8;
BA_ "DiagRequest" BO_ 2564436209 1;
BA_ "Type" BO_ 2564436209 8;
BA_ "Type" BO_ 2564502513 8;
BA_ "DiagState" BO_ 2564502513 1;
BA_ "DiagRequest" BO_ 2564448497 1;
BA_ "Type" BO_ 2564448497 8;
BA_ "DiagRequest" BO_ 2564473073 1;
BA_ "Type" BO_ 2564473073 8;
BA_ "DiagRequest" BO_ 2564464881 1;
BA_ "Type" BO_ 2564464881 8;
BA_ "DiagRequest" BO_ 2564474865 1;
BA_ "Type" BO_ 2564474865 8;
BA_ "DiagRequest" BO_ 2564474609 1;
BA_ "Type" BO_ 2564474609 8;
BA_ "DiagRequest" BO_ 2564430065 1;
BA_ "Type" BO_ 2564430065 8;
BA_ "Type" BO_ 2564485440 8;
BA_ "DiagResponse" BO_ 2564485440 1;
BA_ "Type" BO_ 2564485392 8;
BA_ "DiagResponse" BO_ 2564485392 1;
BA_ "Type" BO_ 2564485472 8;
BA_ "DiagResponse" BO_ 2564485472 1;
BA_ "Type" BO_ 2564485575 8;
BA_ "DiagResponse" BO_ 2564485575 1;
BA_ "Type" BO_ 2564485672 8;
BA_ "DiagResponse" BO_ 2564485672 1;
BA_ "Type" BO_ 2564485664 8;
BA_ "DiagResponse" BO_ 2564485664 1;
BA_ "Type" BO_ 2564485680 8;
BA_ "DiagResponse" BO_ 2564485680 1;
BA_ "Type" BO_ 2564485824 8;
BA_ "DiagResponse" BO_ 2564485824 1;
BA_ "Type" BO_ 2564485792 8;
BA_ "DiagResponse" BO_ 2564485792 1;
BA_ "Type" BO_ 2564485574 8;
BA_ "DiagResponse" BO_ 2564485574 1;
BA_ "Type" BO_ 2564485400 8;
BA_ "DiagResponse" BO_ 2564485400 1;
BA_ "Period [ms]" BO_ 1846 100;
BA_ "Type" BO_ 1846 1;
BA_ "GenMsgSendType" BO_ 1846 0;
BA_ "GenMsgTimeoutTime" BO_ 1846 2500;
BA_ "GenMsgILSupport" BO_ 1846 1;
BA_ "GenMsgCycleTime" BO_ 1846 100;
BA_ "Type" BO_ 1422 11;
BA_ "GenMsgTimeoutTime" BO_ 1422 2500;
BA_ "GenMsgILSupport" BO_ 1422 1;
BA_ "GenMsgDelayTime" BO_ 1422 20;
BA_ "Type" BO_ 1424 11;
BA_ "GenMsgTimeoutTime" BO_ 1424 2500;
BA_ "GenMsgILSupport" BO_ 1424 1;
BA_ "GenMsgDelayTime" BO_ 1424 20;
BA_ "Period [ms]" BO_ 252 10;
BA_ "Type" BO_ 252 1;
BA_ "GenMsgSendType" BO_ 252 0;
BA_ "GenMsgILSupport" BO_ 252 1;
BA_ "GenMsgStartDelayTime" BO_ 252 4;
BA_ "GenMsgCycleTime" BO_ 252 10;
BA_ "Period [ms]" BO_ 1445 1000;
BA_ "Type" BO_ 1445 3;
BA_ "GenMsgSendType" BO_ 1445 0;
BA_ "GenMsgILSupport" BO_ 1445 1;
BA_ "GenMsgStartDelayTime" BO_ 1445 200;
BA_ "GenMsgCycleTime" BO_ 1445 1000;
BA_ "GenMsgDelayTime" BO_ 1445 20;
BA_ "Period [ms]" BO_ 1202 500;
BA_ "Type" BO_ 1202 3;
BA_ "GenMsgSendType" BO_ 1202 0;
BA_ "GenMsgILSupport" BO_ 1202 1;
BA_ "GenMsgStartDelayTime" BO_ 1202 120;
BA_ "GenMsgCycleTime" BO_ 1202 500;
BA_ "GenMsgDelayTime" BO_ 1202 20;
BA_ "GenSigStartValue" SG_ 3221225472 MMotRedSlow 30000;
BA_ "GenSigStartValue" SG_ 414 RxAC_TempSetPoint 1000;
BA_ "GenSigStartValue" SG_ 414 RxAC_ExtTemp 1000;
BA_ "GenSigStartValue" SG_ 542 _0xF 15;
BA_ "GenSigStartValue" SG_ 542 _0x3 3;
BA_ "GenSigStartValue" SG_ 542 _0xFF 255;
BA_ "GenSigStartValue" SG_ 542 TempSetpoint 1000;
BA_ "GenSigStartValue" SG_ 1472 SwitchPosition 1;
BA_ "GenSigStartValue" SG_ 1346 Appl_date_03 1;
BA_ "GenSigStartValue" SG_ 1346 HU_date_day 1;
BA_ "GenSigStartValue" SG_ 1346 Appl_date_02 1;
BA_ "GenSigStartValue" SG_ 1346 HU_date_month 1;
BA_ "GenSigStartValue" SG_ 376 Roll_Rate 32768;
BA_ "GenSigStartValue" SG_ 372 Yaw_Rate 32768;
BA_ "GenSigStartValue" SG_ 490 MMotAct 30000;
BA_ "GenSigStartValue" SG_ 491 MaximumTorqueAvailable 30000;
BA_ "GenSigStartValue" SG_ 491 MinimumTorqueAvailable 30000;
BA_ "GenSigStartValue" SG_ 492 MDriverRequest 30000;
BA_ "GenSigStartValue" SG_ 528 MMotRedFast 30000;
BA_ "GenSigStartValue" SG_ 528 MMotInc 30000;
BA_ "GenSigStartValue" SG_ 532 Ax 2048;
BA_ "GenSigStartValue" SG_ 532 Ay 2048;
BA_ "GenSigStartValue" SG_ 1592 HYS_concH2 2500;
BA_ "GenSigStartValue" SG_ 599 AirBagFailSts 2;
BA_ "Event trans." SG_ 599 PsngrBagChargeSts 0;
BA_ "GenSigStartValue" SG_ 599 PsngrBagChargeSts 3;
BA_ "GenSigSendType" SG_ 599 PsngrBagChargeSts 4;
BA_ "Event trans." SG_ 599 SBR1RowDriverSeatFailSts 0;
BA_ "GenSigStartValue" SG_ 599 SBR1RowDriverSeatFailSts 3;
BA_ "GenSigSendType" SG_ 599 SBR1RowDriverSeatFailSts 4;
BA_ "Event trans." SG_ 599 SBR1RowDriverSeatSts 0;
BA_ "GenSigStartValue" SG_ 599 SBR1RowDriverSeatSts 3;
BA_ "GenSigSendType" SG_ 599 SBR1RowDriverSeatSts 4;
BA_ "Event trans." SG_ 599 SBR1RowPsngrSeatBuckleFailSts 0;
BA_ "GenSigStartValue" SG_ 599 SBR1RowPsngrSeatBuckleFailSts 3;
BA_ "GenSigSendType" SG_ 599 SBR1RowPsngrSeatBuckleFailSts 4;
BA_ "Event trans." SG_ 599 SBR1RowPsngrSeatPPDFailSts 0;
BA_ "GenSigStartValue" SG_ 599 SBR1RowPsngrSeatPPDFailSts 3;
BA_ "GenSigSendType" SG_ 599 SBR1RowPsngrSeatPPDFailSts 4;
BA_ "Event trans." SG_ 599 SBR1RowPsngrSeatSts 0;
BA_ "GenSigStartValue" SG_ 599 SBR1RowPsngrSeatSts 7;
BA_ "GenSigSendType" SG_ 599 SBR1RowPsngrSeatSts 4;
BA_ "Event trans." SG_ 1447 DrvSbltUnFltr 0;
BA_ "GenSigSendType" SG_ 1447 DrvSbltUnFltr 3;
BA_ "Accuracy" SG_ 1050 BatteryVoltageLevelHP "+/-1%";
BA_ "GenSigStartValue" SG_ 1050 BatteryVoltageLevelHP 4;
BA_ "Accuracy" SG_ 1050 BCMSAMFailSts "-";
BA_ "Accuracy" SG_ 1050 VoltageMax "0,025";
BA_ "Accuracy" SG_ 1050 VoltageMin "0,025";
BA_ "Accuracy" SG_ 247 ControlEncoding_TRM_Rq "-";
BA_ "Event trans." SG_ 247 ControlEncoding_TRM_Rq 0;
BA_ "GenSigSendType" SG_ 247 ControlEncoding_TRM_Rq 1;
BA_ "GenSigStartValue" SG_ 247 TxpAuthRequest 1;
BA_ "GenSigStartValue" SG_ 247 TxpReadRequest 1;
BA_ "Accuracy" SG_ 250 BCMFpsCommand "-";
BA_ "Accuracy" SG_ 250 BCMFpsConfirm "-";
BA_ "GenSigStartValue" SG_ 250 BCMFpsConfirm 1;
BA_ "Accuracy" SG_ 250 BCMFpsFailSts "-";
BA_ "Accuracy" SG_ 250 BrakePedalSwitchNCFailSts "-";
BA_ "Accuracy" SG_ 250 BrakePedalSwitchNCSts "-";
BA_ "Accuracy" SG_ 250 BrakePedalSwitchNOFailSts "-";
BA_ "Accuracy" SG_ 250 BrakePedalSwitchNOSts "-";
BA_ "Accuracy" SG_ 250 EngineOffRequest "-";
BA_ "Accuracy" SG_ 250 MessageCounter_BC "-";
BA_ "Accuracy" SG_ 250 TurnIndicatorSts "-";
BA_ "Accuracy" SG_ 1994 IgnitionOnCounter "-";
BA_ "Accuracy" SG_ 245 MinicryptReceptionSts "-";
BA_ "Event trans." SG_ 245 MinicryptReceptionSts 0;
BA_ "GenSigSendType" SG_ 245 MinicryptReceptionSts 1;
BA_ "Event trans." SG_ 1446 A2D_DRV_TEMP_DR_POS 0;
BA_ "GenSigStartValue" SG_ 1446 A2D_DRV_TEMP_DR_POS 819;
BA_ "GenSigSendType" SG_ 1446 A2D_DRV_TEMP_DR_POS 3;
BA_ "Event trans." SG_ 1446 A2D_FT_HVAC_BLOWER_VOLTAGE 0;
BA_ "GenSigStartValue" SG_ 1446 A2D_FT_HVAC_BLOWER_VOLTAGE 479;
BA_ "GenSigSendType" SG_ 1446 A2D_FT_HVAC_BLOWER_VOLTAGE 3;
BA_ "Event trans." SG_ 1446 AcOutputCurrentSts 0;
BA_ "GenSigSendType" SG_ 1446 AcOutputCurrentSts 3;
BA_ "Event trans." SG_ 1446 StopStartClimateInfo 0;
BA_ "GenSigSendType" SG_ 1446 StopStartClimateInfo 3;
BA_ "Event trans." SG_ 900 CmdIgn_FailSts 0;
BA_ "GenSigSendType" SG_ 900 CmdIgn_FailSts 3;
BA_ "Event trans." SG_ 900 CmdIgnSts 0;
BA_ "GenSigSendType" SG_ 900 CmdIgnSts 3;
BA_ "Event trans." SG_ 900 DriveStyleSts 0;
BA_ "GenSigSendType" SG_ 900 DriveStyleSts 3;
BA_ "Event trans." SG_ 900 ESCFnRqstSts 0;
BA_ "GenSigSendType" SG_ 900 ESCFnRqstSts 3;
BA_ "Event trans." SG_ 900 ParkBrakeSts 0;
BA_ "GenSigSendType" SG_ 900 ParkBrakeSts 3;
BA_ "Event trans." SG_ 900 SuspensionLevel 0;
BA_ "GenSigSendType" SG_ 900 SuspensionLevel 3;
BA_ "GenSigStartValue" SG_ 1349 InternalLightLevel 4;
BA_ "GenSigStartValue" SG_ 1349 NotFilteredFuelLevel 255;
BA_ "Event trans." SG_ 1201 BonnetFailSts 0;
BA_ "GenSigSendType" SG_ 1201 BonnetFailSts 3;
BA_ "Event trans." SG_ 1201 CompressorACReqSts 0;
BA_ "GenSigSendType" SG_ 1201 CompressorACReqSts 3;
BA_ "Event trans." SG_ 1201 DriverDoorFailSts 0;
BA_ "GenSigSendType" SG_ 1201 DriverDoorFailSts 3;
BA_ "Event trans." SG_ 1201 DriverDoorSts 0;
BA_ "GenSigSendType" SG_ 1201 DriverDoorSts 3;
BA_ "Event trans." SG_ 1201 ExteriorRearReleaseSwitchSts 0;
BA_ "GenSigSendType" SG_ 1201 ExteriorRearReleaseSwitchSts 3;
BA_ "Event trans." SG_ 1201 FOBSearchRequest 0;
BA_ "GenSigSendType" SG_ 1201 FOBSearchRequest 3;
BA_ "Event trans." SG_ 1201 LockUnlockVehicle 0;
BA_ "GenSigSendType" SG_ 1201 LockUnlockVehicle 3;
BA_ "Event trans." SG_ 1201 RemStActvSts 0;
BA_ "GenSigSendType" SG_ 1201 RemStActvSts 3;
BA_ "Event trans." SG_ 1201 SpSt_Pad1 0;
BA_ "GenSigSendType" SG_ 1201 SpSt_Pad1 3;
BA_ "Event trans." SG_ 1201 SpSt_Pad2 0;
BA_ "GenSigSendType" SG_ 1201 SpSt_Pad2 3;
BA_ "Event trans." SG_ 1201 SteeringWheelButton2Sts 0;
BA_ "GenSigSendType" SG_ 1201 SteeringWheelButton2Sts 3;
BA_ "GenSigStartValue" SG_ 1049 FUEL_VOLT 255;
BA_ "GenSigStartValue" SG_ 1049 FUEL_VOLT2 255;
BA_ "GenSigStartValue" SG_ 257 MasterCylinderPressure 1023;
BA_ "GenSigStartValue" SG_ 506 HSA_BrkPrss 4;
BA_ "Event trans." SG_ 263 BrakeTravelSts 0;
BA_ "GenSigStartValue" SG_ 259 MuSplit 3;
BA_ "GenSigStartValue" SG_ 259 OverSteering 63;
BA_ "GenSigStartValue" SG_ 259 TorqueRequest 2047;
BA_ "GenSigStartValue" SG_ 259 TorqueRequest_FAST 2047;
BA_ "GenSigStartValue" SG_ 259 UnderSteering 63;
BA_ "GenSigStartValue" SG_ 501 VehicleStandStillSts 1;
BA_ "Event trans." SG_ 1048 ASRActive 0;
BA_ "GenSigSendType" SG_ 1048 ASRActive 3;
BA_ "Event trans." SG_ 1048 MSRActive 0;
BA_ "GenSigSendType" SG_ 1048 MSRActive 3;
BA_ "Event trans." SG_ 1199 ABSCheck 0;
BA_ "GenSigSendType" SG_ 1199 ABSCheck 4;
BA_ "Event trans." SG_ 1199 ABSFailSts 0;
BA_ "GenSigSendType" SG_ 1199 ABSFailSts 4;
BA_ "Event trans." SG_ 1199 BSM_BLC_Active 0;
BA_ "GenSigSendType" SG_ 1199 BSM_BLC_Active 4;
BA_ "Event trans." SG_ 1199 BSMSysSts 0;
BA_ "GenSigSendType" SG_ 1199 BSMSysSts 4;
BA_ "Event trans." SG_ 1199 DSTFailSts 0;
BA_ "GenSigSendType" SG_ 1199 DSTFailSts 4;
BA_ "Event trans." SG_ 1199 EBDCheck 0;
BA_ "GenSigSendType" SG_ 1199 EBDCheck 4;
BA_ "Event trans." SG_ 1199 EBDFailSts 0;
BA_ "GenSigSendType" SG_ 1199 EBDFailSts 4;
BA_ "Event trans." SG_ 1199 ERMActive 0;
BA_ "GenSigSendType" SG_ 1199 ERMActive 4;
BA_ "Event trans." SG_ 1199 ESCCheck 0;
BA_ "GenSigSendType" SG_ 1199 ESCCheck 4;
BA_ "Event trans." SG_ 1199 ESCFailSts 0;
BA_ "GenSigSendType" SG_ 1199 ESCFailSts 4;
BA_ "Event trans." SG_ 1199 ESCIntervention 0;
BA_ "GenSigSendType" SG_ 1199 ESCIntervention 4;
BA_ "Event trans." SG_ 1199 ESCOFFAvailability 0;
BA_ "GenSigStartValue" SG_ 1199 ESCOFFAvailability 1;
BA_ "GenSigSendType" SG_ 1199 ESCOFFAvailability 4;
BA_ "Event trans." SG_ 1199 ESCOFFLamp 0;
BA_ "GenSigSendType" SG_ 1199 ESCOFFLamp 4;
BA_ "Event trans." SG_ 1199 Function2Sts 0;
BA_ "GenSigSendType" SG_ 1199 Function2Sts 4;
BA_ "Event trans." SG_ 1199 FunctionFailSts 0;
BA_ "GenSigSendType" SG_ 1199 FunctionFailSts 4;
BA_ "Event trans." SG_ 1199 FunctionIntervention 0;
BA_ "GenSigSendType" SG_ 1199 FunctionIntervention 4;
BA_ "Event trans." SG_ 1199 FunctionSts 0;
BA_ "GenSigSendType" SG_ 1199 FunctionSts 4;
BA_ "Event trans." SG_ 1199 HillHolderFailSts 0;
BA_ "GenSigSendType" SG_ 1199 HillHolderFailSts 4;
BA_ "Event trans." SG_ 1199 RollsModeAct 0;
BA_ "GenSigSendType" SG_ 1199 RollsModeAct 4;
BA_ "Event trans." SG_ 1199 TSCActive 0;
BA_ "GenSigSendType" SG_ 1199 TSCActive 4;
BA_ "Accuracy" SG_ 254 CRC_BYD "1";
BA_ "Accuracy" SG_ 254 InternalError_BSM "-";
BA_ "Accuracy" SG_ 254 LatAcceleration_BSM "0,02";
BA_ "Accuracy" SG_ 254 LatAccelerationFailSts_BSM "-";
BA_ "Accuracy" SG_ 254 LongAcceleration_BSM "0,02";
BA_ "Accuracy" SG_ 254 LongAccelerationFailSts_BSM "-";
BA_ "Accuracy" SG_ 254 MessageCounter_BYD "1";
BA_ "Accuracy" SG_ 254 YawRate_BSM "0,08";
BA_ "Accuracy" SG_ 254 YawRateFailSts_BSM "-";
BA_ "Accuracy" SG_ 750 SteeringColumnTorque "-";
BA_ "Accuracy" SG_ 280 MessageCounter_TVM "-";
BA_ "Accuracy" SG_ 280 R_Diff_Mode_Req "-";
BA_ "Accuracy" SG_ 280 R_Diff_Trq_Req "-";
BA_ "Accuracy" SG_ 288 MessageCounter_EC "-";
BA_ "Event trans." SG_ 2651930624 Digit_01 0;
BA_ "GenSigSendType" SG_ 2651930624 Digit_01 1;
BA_ "Accuracy" SG_ 2651930625 Digit_01_ECM "-";
BA_ "Event trans." SG_ 2651930625 Digit_01_ECM 0;
BA_ "GenSigSendType" SG_ 2651930625 Digit_01_ECM 1;
BA_ "Accuracy" SG_ 2651930625 Digit_02_ECM "-";
BA_ "Accuracy" SG_ 2651930625 Digit_03_ECM "-";
BA_ "Accuracy" SG_ 2651930625 Digit_04_ECM "-";
BA_ "Accuracy" SG_ 2651930625 Digit_05_ECM "-";
BA_ "Accuracy" SG_ 2651930625 Digit_06_ECM "-";
BA_ "Accuracy" SG_ 2651930625 Digit_07_ECM "-";
BA_ "Accuracy" SG_ 2651930625 Digit_08_ECM "-";
BA_ "Accuracy" SG_ 2651930625 Digit_09_ECM "-";
BA_ "Accuracy" SG_ 2651930625 Digit_10_ECM "-";
BA_ "Accuracy" SG_ 2651930625 Digit_11_ECM "-";
BA_ "Accuracy" SG_ 2651930627 Digit_01_IPC "-";
BA_ "Event trans." SG_ 2651930627 Digit_01_IPC 0;
BA_ "GenSigSendType" SG_ 2651930627 Digit_01_IPC 1;
BA_ "Accuracy" SG_ 2651930627 Digit_02_IPC "-";
BA_ "Accuracy" SG_ 2651930627 Digit_03_IPC "-";
BA_ "Accuracy" SG_ 2651930627 Digit_04_IPC "-";
BA_ "Accuracy" SG_ 2651930627 Digit_05_IPC "-";
BA_ "Accuracy" SG_ 2651930627 Digit_06_IPC "-";
BA_ "Accuracy" SG_ 2651930627 Digit_07_IPC "-";
BA_ "Accuracy" SG_ 2651930627 Digit_08_IPC "-";
BA_ "Accuracy" SG_ 2651930627 Digit_09_IPC "-";
BA_ "Accuracy" SG_ 2651930627 Digit_10_IPC "-";
BA_ "Accuracy" SG_ 2651930627 Digit_11_IPC "-";
BA_ "Accuracy" SG_ 2651930689 Digit_01_RFHM "-";
BA_ "Event trans." SG_ 2651930689 Digit_01_RFHM 0;
BA_ "GenSigSendType" SG_ 2651930689 Digit_01_RFHM 1;
BA_ "Accuracy" SG_ 2651930689 Digit_02_RFHM "-";
BA_ "Accuracy" SG_ 2651930689 Digit_03_RFHM "-";
BA_ "Accuracy" SG_ 2651930689 Digit_04_RFHM "-";
BA_ "Accuracy" SG_ 2651930689 Digit_05_RFHM "-";
BA_ "Accuracy" SG_ 2651930689 Digit_06_RFHM "-";
BA_ "Accuracy" SG_ 2651930689 Digit_07_RFHM "-";
BA_ "Accuracy" SG_ 2651930689 Digit_08_RFHM "-";
BA_ "Accuracy" SG_ 2651930689 Digit_09_RFHM "-";
BA_ "Accuracy" SG_ 2651930689 Digit_10_RFHM "-";
BA_ "Accuracy" SG_ 2651930689 Digit_11_RFHM "-";
BA_ "Accuracy" SG_ 2651930659 Digit_01_TBM "-";
BA_ "Event trans." SG_ 2651930659 Digit_01_TBM 0;
BA_ "GenSigSendType" SG_ 2651930659 Digit_01_TBM 1;
BA_ "Accuracy" SG_ 2651930659 Digit_02_TBM "-";
BA_ "Accuracy" SG_ 2651930659 Digit_03_TBM "-";
BA_ "Accuracy" SG_ 2651930659 Digit_04_TBM "-";
BA_ "Accuracy" SG_ 2651930659 Digit_05_TBM "-";
BA_ "Accuracy" SG_ 2651930659 Digit_06_TBM "-";
BA_ "Accuracy" SG_ 2651930659 Digit_07_TBM "-";
BA_ "Accuracy" SG_ 2651930659 Digit_08_TBM "-";
BA_ "Accuracy" SG_ 2651930659 Digit_09_TBM "-";
BA_ "Accuracy" SG_ 2651930659 Digit_10_TBM "-";
BA_ "Accuracy" SG_ 2651930659 Digit_11_TBM "-";
BA_ "Accuracy" SG_ 2651930635 Digit_01_TRANSMISSION "-";
BA_ "Event trans." SG_ 2651930635 Digit_01_TRANSMISSION 0;
BA_ "GenSigSendType" SG_ 2651930635 Digit_01_TRANSMISSION 1;
BA_ "Accuracy" SG_ 2651930635 Digit_02_TRANSMISSION "-";
BA_ "Accuracy" SG_ 2651930635 Digit_03_TRANSMISSION "-";
BA_ "Accuracy" SG_ 2651930635 Digit_04_TRANSMISSION "-";
BA_ "Accuracy" SG_ 2651930635 Digit_05_TRANSMISSION "-";
BA_ "Accuracy" SG_ 2651930635 Digit_06_TRANSMISSION "-";
BA_ "Accuracy" SG_ 2651930635 Digit_07_TRANSMISSION "-";
BA_ "Accuracy" SG_ 2651930635 Digit_08_TRANSMISSION "-";
BA_ "Accuracy" SG_ 2651930635 Digit_09_TRANSMISSION "-";
BA_ "Accuracy" SG_ 2651930635 Digit_10_TRANSMISSION "-";
BA_ "Accuracy" SG_ 2651930635 Digit_11_TRANSMISSION "-";
BA_ "GenSigSendType" SG_ 598 HandsFreeEnable 3;
BA_ "Event trans." SG_ 598 PowerModeSts_IPC 0;
BA_ "GenSigSendType" SG_ 598 PowerModeSts_IPC 3;
BA_ "Event trans." SG_ 598 PsngrBagRequestSts 0;
BA_ "GenSigSendType" SG_ 598 PsngrBagRequestSts 3;
BA_ "GenSigStartValue" SG_ 598 RemoteDoorUnlock 1;
BA_ "Event trans." SG_ 598 SpeedLimitActivationIPC 0;
BA_ "GenSigSendType" SG_ 598 SpeedLimitActivationIPC 3;
BA_ "Accuracy" SG_ 2564448497 N_PDU "-";
BA_ "Accuracy" SG_ 2564485472 N_PDU "-";
BA_ "GenSigStartValue" SG_ 1846 RawPVS1 255;
BA_ "GenSigStartValue" SG_ 1846 RawPVS2 255;
BA_ "GenSigStartValue" SG_ 1846 RawTPS1 255;
BA_ "GenSigStartValue" SG_ 1846 RawTPS2 255;
BA_ "GenSigStartValue" SG_ 1422 DriverDoor4AjarRawValSts 1;
BA_ "Event trans." SG_ 1422 DrvDoorLatchDeadLockSts 0;
BA_ "GenSigSendType" SG_ 1422 DrvDoorLatchDeadLockSts 1;
BA_ "Event trans." SG_ 1422 DrvDoorLatchSts 0;
BA_ "GenSigSendType" SG_ 1422 DrvDoorLatchSts 1;
BA_ "Event trans." SG_ 1422 E1DriverDoorSts 0;
BA_ "GenSigSendType" SG_ 1422 E1DriverDoorSts 1;
BA_ "Event trans." SG_ 1422 LSMDAjarSensorFailSts 0;
BA_ "GenSigSendType" SG_ 1422 LSMDAjarSensorFailSts 1;
BA_ "Event trans." SG_ 1422 LSMDCrashLineFailSts 0;
BA_ "GenSigSendType" SG_ 1422 LSMDCrashLineFailSts 1;
BA_ "Event trans." SG_ 1422 LSMDExternalLockReleaseSwitchFai 0;
BA_ "GenSigSendType" SG_ 1422 LSMDExternalLockReleaseSwitchFai 1;
BA_ "SystemSignalLongSymbol" SG_ 1422 LSMDExternalLockReleaseSwitchFai "LSMDExternalLockReleaseSwitchFailSts";
BA_ "Event trans." SG_ 1422 LSMDFobSearchReq 0;
BA_ "GenSigSendType" SG_ 1422 LSMDFobSearchReq 1;
BA_ "Event trans." SG_ 1422 LSMDInternalFailSts 0;
BA_ "GenSigSendType" SG_ 1422 LSMDInternalFailSts 1;
BA_ "Event trans." SG_ 1422 LSMDInternalLockLightFailSts 0;
BA_ "GenSigSendType" SG_ 1422 LSMDInternalLockLightFailSts 1;
BA_ "Event trans." SG_ 1422 LSMDInternalReleaseSwitchFailSts 0;
BA_ "GenSigSendType" SG_ 1422 LSMDInternalReleaseSwitchFailSts 1;
BA_ "Event trans." SG_ 1422 LSMDInternalUnlockLightFailSts 0;
BA_ "GenSigSendType" SG_ 1422 LSMDInternalUnlockLightFailSts 1;
BA_ "Event trans." SG_ 1422 LSMDReleaseLockReq 0;
BA_ "GenSigSendType" SG_ 1422 LSMDReleaseLockReq 1;
BA_ "Event trans." SG_ 1422 LSMDTrunkDisableReq 0;
BA_ "GenSigSendType" SG_ 1422 LSMDTrunkDisableReq 1;
BA_ "Event trans." SG_ 1424 E2PsngrDoorSts 0;
BA_ "GenSigSendType" SG_ 1424 E2PsngrDoorSts 1;
BA_ "Event trans." SG_ 1424 LSMPAjarSensorFailSts 0;
BA_ "GenSigSendType" SG_ 1424 LSMPAjarSensorFailSts 1;
BA_ "Event trans." SG_ 1424 LSMPCrashLineFailSts 0;
BA_ "GenSigSendType" SG_ 1424 LSMPCrashLineFailSts 1;
BA_ "Event trans." SG_ 1424 LSMPExternalLockReleaseSwitchFai 0;
BA_ "GenSigSendType" SG_ 1424 LSMPExternalLockReleaseSwitchFai 1;
BA_ "SystemSignalLongSymbol" SG_ 1424 LSMPExternalLockReleaseSwitchFai "LSMPExternalLockReleaseSwitchFailSts";
BA_ "Event trans." SG_ 1424 LSMPFobSearchReq 0;
BA_ "GenSigSendType" SG_ 1424 LSMPFobSearchReq 1;
BA_ "Event trans." SG_ 1424 LSMPInternalFailSts 0;
BA_ "GenSigSendType" SG_ 1424 LSMPInternalFailSts 1;
BA_ "Event trans." SG_ 1424 LSMPInternalLockLightFailSts 0;
BA_ "GenSigSendType" SG_ 1424 LSMPInternalLockLightFailSts 1;
BA_ "Event trans." SG_ 1424 LSMPInternalReleaseSwitchFailSts 0;
BA_ "GenSigSendType" SG_ 1424 LSMPInternalReleaseSwitchFailSts 1;
BA_ "Event trans." SG_ 1424 LSMPInternalUnlockLightFailSts 0;
BA_ "GenSigSendType" SG_ 1424 LSMPInternalUnlockLightFailSts 1;
BA_ "Event trans." SG_ 1424 LSMPReleaseLockReq 0;
BA_ "GenSigSendType" SG_ 1424 LSMPReleaseLockReq 1;
BA_ "Event trans." SG_ 1424 LSMPTrunkDisableReq 0;
BA_ "GenSigSendType" SG_ 1424 LSMPTrunkDisableReq 1;
BA_ "Event trans." SG_ 1424 PsngrDoorLatchDeadLockSts 0;
BA_ "GenSigSendType" SG_ 1424 PsngrDoorLatchDeadLockSts 1;
BA_ "Event trans." SG_ 1424 PsngrDoorLatchSts 0;
BA_ "GenSigSendType" SG_ 1424 PsngrDoorLatchSts 1;
BA_ "GenSigStartValue" SG_ 252 AlternatorFail 1;
BA_ "GenSigStartValue" SG_ 252 EngineStopStartSts 1;
BA_ "GenSigStartValue" SG_ 252 EngineSts 3;
BA_ "Accuracy" SG_ 1445 CC_SetSpdDspl_KPH "-";
BA_ "Event trans." SG_ 1445 CC_SetSpdDspl_KPH 0;
BA_ "GenSigSendType" SG_ 1445 CC_SetSpdDspl_KPH 3;
BA_ "Accuracy" SG_ 1445 CruiseControlLampSts "-";
BA_ "Event trans." SG_ 1445 CruiseControlLampSts 0;
BA_ "GenSigSendType" SG_ 1445 CruiseControlLampSts 3;
BA_ "Accuracy" SG_ 1445 CruiseControlSts "-";
BA_ "Event trans." SG_ 1445 CruiseControlSts 0;
BA_ "GenSigSendType" SG_ 1445 CruiseControlSts 3;
BA_ "Accuracy" SG_ 1445 HMIDisplay_CC "-";
BA_ "Event trans." SG_ 1445 HMIDisplay_CC 0;
BA_ "GenSigStartValue" SG_ 1445 HMIDisplay_CC 4;
BA_ "GenSigSendType" SG_ 1445 HMIDisplay_CC 3;
BA_ "Accuracy" SG_ 1445 Override "-";
BA_ "Event trans." SG_ 1445 Override 0;
BA_ "GenSigSendType" SG_ 1445 Override 3;
BA_ "Event trans." SG_ 1202 Bonnet2FailSts 0;
BA_ "GenSigSendType" SG_ 1202 Bonnet2FailSts 3;
BA_ "Event trans." SG_ 1202 Bonnet2Sts 0;
BA_ "GenSigSendType" SG_ 1202 Bonnet2Sts 3;
BA_ "Accuracy" SG_ 1202 EngineOilPressure "-";
BA_ "Accuracy" SG_ 1202 EngineOilTemp_WarningLight "-";
BA_ "Event trans." SG_ 1202 EngineOilTemp_WarningLight 0;
BA_ "GenSigSendType" SG_ 1202 EngineOilTemp_WarningLight 3;
BA_ "Accuracy" SG_ 1202 EngineOilTemperature "-";
BA_ "Accuracy" SG_ 1202 PowerModeSts_ECM "-";
BA_ "Event trans." SG_ 1202 PowerModeSts_ECM 0;
BA_ "GenSigSendType" SG_ 1202 PowerModeSts_ECM 3;
VAL_ 1345 PsMonitoring_RA_Status 7 "Beschreibung für den Wert '0x7'" 6 "ax(Yrs), Mon. deact., fault set" 5 "ax(Wss), Mon. deact., no fault" 4 "ax(Yrs), Mon. deact., no fault" 3 "ax(Wss), Mon. active, fault set" 2 "ax(Yrs), Mon. active, fault set" 1 "ax(Wss), Mon. active, no fault" 0 "ax(Yrs), Mon. active, no fault" ;
VAL_ 1345 PSMonitoring_FA_Status 7 "ax(Wss), Mon. deact., fault set" 6 "ax(Yrs), Mon. deact., fault set" 5 "ax(Wss), Mon. deact., no fault" 4 "ax(Yrs), Mon. deact., no fault" 3 "ax(Wss), Mon. active, fault set" 2 "ax(Yrs), Mon. active, fault set" 1 "ax(Wss), Mon. active, no fault" 0 "ax(Yrs), Mon. active, no fault" ;
VAL_ 670 RxAC_FlapStateWindscreen 3 "Not available" 2 "ON" 1 "OFF" 0 "Unknown state" ;
VAL_ 670 RxAC_FlapStateRecy 3 "Not available" 2 "ON" 1 "OFF" 0 "Unknown state" ;
VAL_ 670 RxAC_FlapStateHead 3 "Not available" 2 "ON" 1 "OFF" 0 "Unknown state" ;
VAL_ 670 RxAC_FlapStateFeet 3 "Not available" 2 "ON" 1 "OFF" 0 "Unknown state" ;
VAL_ 414 RxACModeFdbk_Mode 3 "Not available" 2 "ON" 1 "OFF" 0 "Unknown state" ;
VAL_ 414 RxACModeFdbk_Eco 3 "Not available" 2 "ON" 1 "OFF" 0 "Unknown state" ;
VAL_ 414 RxACModeFdbk_Defrost 3 "Not available" 2 "ON" 1 "OFF" 0 "Unknown state" ;
VAL_ 414 RxACModeFdbk_Auto 3 "Not available" 2 "AutoMode" 1 "Manual Mode" 0 "UnknownState" ;
VAL_ 542 HVAC_Mode 170 "HVAC_system" 10 "HV_system" 0 "UnrecognizedCommand" ;
VAL_ 542 ModeAutoManu 3 "Not available" 2 "AutoMode" 1 "Manual Mode" 0 "UnknownState" ;
VAL_ 542 ModeOnOffSystem 3 "Not available" 2 "ON" 1 "OFF" 0 "Unknown state" ;
VAL_ 542 ModeEcoOnOff 3 "Not available" 2 "ON" 1 "OFF" 0 "Unknown state" ;
VAL_ 542 PressurisationOnOff 3 "Not available" 2 "ON" 1 "OFF" 0 "Unknown state" ;
VAL_ 542 ModeDefrostOnOff 3 "Not available" 2 "ON" 1 "OFF" 0 "Unknown state" ;
VAL_ 1472 ABS_fault_info 2 "active faults stored" 1 "inactive faults stored" 0 "no faults stored" ;
VAL_ 1472 Diag_RR 2 "Signal error" 1 "Line error" 0 "Signal ok" ;
VAL_ 1472 Diag_RL 2 "Signal error" 1 "Line error" 0 "Signal ok" ;
VAL_ 1472 Diag_FR 2 "Beschreibung für den Wert '0x2'" 1 "Line error" 0 "Signal ok" ;
VAL_ 1472 Diag_FL 2 "Signal error" 1 "Line error" 0 "Signal ok" ;
VAL_ 1592 HYS_errCod 3 "SBC over temperature" 2 "CMC over temperature" 1 "No Error" 0 "Diagnosis Not Executed" ;
VAL_ 599 AirBagFailSts 0 "Fail_Not_Present_Lamp_Off" 1 "Fail_Not_Present_Lamp_Flashing" 2 "Fail_Present_Lamp_On" 3 "Not_Used" ;
VAL_ 599 PsngrBagChargeSts 0 "Active" 1 "Not_Active" 2 "Not_Present" 3 "SNA" ;
VAL_ 599 SBR1RowDriverSeatConfigSts 0 "Seat_Not_Checked" 1 "Seat_Checked" ;
VAL_ 599 SBR1RowDriverSeatFailSts 0 "Fail_Not_Present" 1 "Fail_Present" 3 "SNA" ;
VAL_ 599 SBR1RowDriverSeatSts 0 "Seat_Belt_Fasten" 1 "Seat_Belt_Not_Fasten" 3 "SNA" ;
VAL_ 599 SBR1RowPsngrSeatBuckleFailSts 0 "Fail_Not_Present" 1 "Fail_Present" 3 "SNA" ;
VAL_ 599 SBR1RowPsngrSeatConfigSts 0 "Seat_Not_Checked" 1 "Seat_Checked" ;
VAL_ 599 SBR1RowPsngrSeatPPDFailSts 0 "Fail_Not_Present" 1 "Fail_Present" 3 "SNA" ;
VAL_ 599 SBR1RowPsngrSeatSts 0 "Seat_Belt_Fasten" 1 "Seat_Belt_Not_Fasten" 2 "Seat_Safe" 3 "Seat_Not_Safe" 7 "SNA" ;
VAL_ 1447 DrvSbltUnFltr 0 "Seat belt fastened/Buckled" 1 "Seatbelt not fastened/Unbuckled" 2 "Seatbelt shorted low/LOW " 3 "Seatbelt shorted high/HIGH " 7 "Signal not available/SNA" ;
VAL_ 1050 BCMSAMFailSts 0 "Fail_not_present" 1 "Fail_present" ;
VAL_ 247 TxpAuthRequest 0 "Transponder_Authentication_Request" 1 "Not_Active" ;
VAL_ 247 TxpReadRequest 0 "Transponder_Reading_Request" 1 "Not_Active" ;
VAL_ 250 BCMFpsCommand 0 "Do_Not_Actuate" 1 "Actuate" ;
VAL_ 250 BCMFpsConfirm 0 "Actuate" 1 "Do_Not_Actuate" ;
VAL_ 250 BCMFpsFailSts 0 "Fail_not_Present" 1 "Fail_Present" ;
VAL_ 250 BrakePedalSwitchNCFailSts 0 "Fail_Not_Present" 1 "Fail_Present" ;
VAL_ 250 BrakePedalSwitchNCSts 0 "Not_Active" 1 "Active" ;
VAL_ 250 BrakePedalSwitchNOFailSts 0 "Fail_Not_Present" 1 "Fail_Present" ;
VAL_ 250 BrakePedalSwitchNOSts 0 "Not_Active" 1 "Active" ;
VAL_ 250 EngineOffRequest 0 "Not_Active" 1 "Active" ;
VAL_ 250 KeyInIgnSts 0 "KEY_DEF" 1 "KEY_NOT_IN_IGN" 2 "KEY_IN_IGN" 3 "SNA" ;
VAL_ 250 OperationalModeSts 0 "Initialization" 1 "Ignition_Off_WithoutKey" 2 "Ignition_Off" 3 "Ignition_Acc" 4 "Ignition_On" 5 "Ignition_Pre_Start" 6 "Ignition_Start" 7 "Ignition_Cranking" 8 "Ignition_On_EngOn" 9 "Ignition_Pre_Acc" 10 "Ignition_Pre_Off" 11 "Automatic_Cranking" 12 "Automatic_Stop" 13 "Key_Authenticated" 14 "Not_Used" 15 "SNA" ;
VAL_ 250 StartRelayBCMFault 0 "Not_Present" 1 "Present" ;
VAL_ 250 StartRelayBCMSts 0 "OFF" 1 "ON" ;
VAL_ 250 TurnIndicatorSts 0 "Center" 1 "Right" 2 "Left" 3 "SNA" ;
VAL_ 245 MinicryptReceptionSts 0 "Not_Received" 1 "Received" ;
VAL_ 1446 A2D_DRV_TEMP_DR_POS 1023 "SNA" ;
VAL_ 1446 A2D_FT_HVAC_BLOWER_VOLTAGE 1023 "SNA" ;
VAL_ 1446 AcOutputCurrentSts 255 "SNA" ;
VAL_ 1446 StopStartClimateInfo 0 "SPST_ON" 1 "CABIN_HI" 2 "CABIN_LO" 3 "MAX_AC" 4 "FT_DEFROST" 5 "EBL" 7 "SNA" ;
VAL_ 748 FrontWiperMoveSts 0 "Stop" 1 "Moving" ;
VAL_ 748 RemStartActiveEPB 0 "No_request" 1 "Request" ;
VAL_ 900 CmdIgn_FailSts 0 "Fail_Not_Present" 1 "Fail_Present" 3 "SNA" ;
VAL_ 900 CmdIgnSts 0 "Initialization" 1 "IGN_LK" 3 "ACC" 4 "RUN" 5 "START" 7 "SNA" ;
VAL_ 900 DriveStyleSts 0 "Normal" 1 "City" 2 "Sport_Fun" 3 "Winter_Race" 4 "Eco" 5 "TracPlus" 6 "Trekking" 7 "Auto" 8 "Snow" 9 "Sand" 10 "Mud" 11 "Rock" 12 "Race" 31 "SNA" ;
VAL_ 900 ESCFnRqstSts 0 "Open" 1 "Closed" 3 "SNA" ;
VAL_ 900 ExternalTemperature 511 "SNA" ;
VAL_ 900 ExternalTemperatureFailSts 0 "Fail_not_present" 1 "Fail_present" ;
VAL_ 900 Int_Relay_FailSts 0 "Fail_Not_Present" 1 "Fail_Present" 3 "SNA" ;
VAL_ 900 LowBeamSts 0 "OFF" 1 "ON" ;
VAL_ 900 ParkBrakeSts 0 "OFF" 1 "ON" ;
VAL_ 900 PowerModeSts 0 "Standard_Power" 1 "Logistic_Mode_ON" 2 "Logistic_Mode_PR" 3 "LogisticModeON_and_EngineON" ;
VAL_ 900 SuspensionLevel 0 "Level_0" 1 "Level_1" 2 "Level_2" 3 "SNA" ;
VAL_ 1349 ChkFuelLevelSts 0 "Fault_Not_Present" 1 "Chk_Code_1" 2 "Chk_Code_2" 3 "Chk_Code_3" 4 "Chk_Code_4" 5 "Not_Used" 6 "Not_Used" 7 "Not_Used" ;
VAL_ 1349 ExternalTemperatureAD_Voltage 255 "SNA" ;
VAL_ 1349 FpsNotAvailable 0 "FPS_Available" 1 "FPS_Not_Available" ;
VAL_ 1349 FrontWiperReq 0 "OFF" 1 "INT" 2 "LOW" 3 "HIGH" ;
VAL_ 1349 FuelLevel 255 "SNA" ;
VAL_ 1349 FuelLevelFailSts 0 "Fail_Not_Present" 1 "Fail_Present" ;
VAL_ 1349 InternalLightLevel 0 "Level_1" 1 "Level_2" 2 "Level_3" 3 "Level_4" 4 "Level_5" 5 "Level_6" 6 "Level_7" 7 "Level_8" 8 "Level_9" 9 "Level_10" 10 "Level_11" 11 "Level_12" 12 "Level_13" 13 "Level_14" 14 "Level_15" 15 "Level_16" ;
VAL_ 1349 InternalLightSts 0 "Not_Active" 1 "Active" ;
VAL_ 1349 NotFilteredFuelLevel 255 "SNA" ;
VAL_ 1201 BonnetFailSts 0 "Fail_Not_Present" 1 "Fail_Present" ;
VAL_ 1201 BonnetSts 0 "Closed" 1 "Open" ;
VAL_ 1201 CompressorACReqSts 0 "Not_Active" 1 "Active" ;
VAL_ 1201 DriverDoorFailSts 0 "Fail_Not_Present" 1 "Fail_Present" ;
VAL_ 1201 DriverDoorSts 0 "Closed" 1 "Open" ;
VAL_ 1201 ExteriorRearReleaseSwitchSts 0 "Not_Pressed" 1 "Pressed" ;
VAL_ 1201 FOBSearchRequest 0 "NO_ACTION" 1 "REQUEST_SEARCH" 2 "RESULT_RECEIVED" 3 "RESERVED" ;
VAL_ 1201 LHRDoorSts 0 "Closed" 1 "Open" ;
VAL_ 1201 LockUnlockVehicle 0 "Idle" 1 "Locked" 2 "Unlocked" 3 "Not_Used" ;
VAL_ 1201 PsngrDoorSts 0 "Closed" 1 "Open" ;
VAL_ 1201 RemSt_InhibitSts 0 "INHIBIT_DEFAUILT" 1 "TIME_OUT_RUN" 2 "TIME_OUT_CUST_MODE" 3 "KEY_IN_RUN" 4 "DRV_DOOR_AJAR" 5 "PASS_DOOR_AJAR" 6 "LR_DOOR_AJAR" 7 "RR_DOOR_AJAR" 8 "START_COUNTER" 9 "FAIL_COUNTER" 10 "LOW_RPM_SHUTDOWN" 11 "KEY_IN_IGN" 12 "BRAKE_PRESSED" 13 "HAZARD_LAMP_ON" 14 "NOT_IN_PARK" 15 "VEH_SPEED_HIGH" 16 "HOOD_AJAR" 17 "TRUNK_LIFTGATE" 18 "VTA_ALARM" 19 "PANIC_MODE" 20 "BATT_VOLT_HIGH" 21 "BATT_VOLT_LOW" 22 "POWER_LOSS" 23 "MIL_ON" 24 "OIL_PRESSURE_LOW" 25 "COOLANT_TEMP_HIGH" 26 "RPM_HIGH" 27 "CRANK_NO_START" 28 "REMOTE_OFF_RQ" 29 "RS_DISABLED_PREV" 30 "NOT_CONFIGURED" 31 "NO_HOOD_SWITCH" 32 "NO_AUTO_TRANS" 33 "NOT_ENABLED" 34 "INVALID_SKIM_KEY" 35 "IGN_SNA" 36 "IGN_NOT_LOCK" 37 "GLOW_PLUG_TIMEOUT" 38 "LOW_FUEL" 39 "ETC_LAMP_ON" 40 "LOGISTIC_MODE" 41 "COLD_START_LAMP_FLASH" 62 "EPB_NO_RESP" 63 "SNA" ;
VAL_ 1201 RemStActvSts 0 "Remote Start Not Active" 1 "Remote Start Active" ;
VAL_ 1201 RHatchSts 0 "Closed" 1 "Open" ;
VAL_ 1201 RHRDoorSts 0 "Closed" 1 "Open" ;
VAL_ 1201 SpSt_Pad1 0 "Button Unpressed" 1 "Button Pressed" 2 "Short to Ground" 3 "Short to Power" 4 "Indeterminate" 7 "SNA" ;
VAL_ 1201 SpSt_Pad2 0 "Button Unpressed" 1 "Button Pressed" 2 "Short to Ground" 3 "Short to Power" 4 "Indeterminate" 7 "SNA" ;
VAL_ 1201 SteeringWheelButton2Sts 0 "Not_Pressed" 1 "Pressed" ;
VAL_ 1201 TheftAlarmStatus 0 "VTA_DISARM" 1 "VTA_PREARM" 2 "VTA_ARM" 3 "VTA_LGT" 4 "VTA_LGT_HORN" 5 "VTA_TAMP" 6 "VTA_ITM_Alarm" 7 "SNA" ;
VAL_ 1049 BonnetAjarRawValSts 0 "Default" 1 "FL_SSA" 2 "FL_SSB" 3 "FL_SSC" 4 "FL_SSD" 5 "FL_SSE" 6 "OPEN_SSA" 7 "OPEN_SSB" 8 "CLOSED_SSA" 9 "CLOSED_SSB" 10 "FH_SSA" 11 "FH_SSB" 12 "FH_SSC" 13 "FH_SSD" 14 "FH_SSE" 15 "SNA" ;
VAL_ 1049 FUEL_VOLT 255 "SNA" ;
VAL_ 1049 FUEL_VOLT2 255 "SNA" ;
VAL_ 1049 RHatchAjarRawValSts 0 "Default" 1 "FL_SSA" 2 "FL_SSB" 3 "FL_SSC" 4 "FL_SSD" 5 "FL_SSE" 6 "OPEN_SSA" 7 "OPEN_SSB" 8 "CLOSED_SSA" 9 "CLOSED_SSB" 10 "FH_SSA" 11 "FH_SSB" 12 "FH_SSC" 13 "FH_SSD" 14 "FH_SSE" 15 "SNA" ;
VAL_ 257 ABSActive 0 "Not_active" 1 "Active" ;
VAL_ 257 BrakeInterventionSts 0 "No_active_brake_intervention" 1 "Active_brake_intervention" ;
VAL_ 257 BSMShiftInterference 0 "Shift_allowed" 1 "Shift_not_allowed" 3 "SNA" ;
VAL_ 257 ESCActive 0 "Not_active" 1 "Active" ;
VAL_ 257 MasterCylinderPressure 1023 "SNA" ;
VAL_ 257 PrefillActive 0 "Not_Active" 1 "Active" ;
VAL_ 257 VehicleSpeedVSOSig 8191 "SNA" ;
VAL_ 257 VehicleSpeedVSOSigFailSts 0 "Fail_not_present" 1 "Fail_present" ;
VAL_ 506 HSA_BrkPrss 1023 "SNA" ;
VAL_ 506 HSA_BrkPrssFailSts 0 "Fail_Not_Present" 1 "Fail_Present" ;
VAL_ 263 Bleeding_Warning 0 "Fail_Not_Present" 1 "Fail_Present" ;
VAL_ 263 BrakeFluidLevelSts_BSM 0 "OK" 1 "Low_Level" ;
VAL_ 263 BrakePedalSwitchNCFailSts 0 "Fail_Not_Present" 1 "Fail_Present" ;
VAL_ 263 BrakePedalSwitchNCSts 0 "Not_Active" 1 "Active" ;
VAL_ 263 BrakePedalSwitchNOFailSts 0 "Fail_Not_Present" 1 "Fail_Present" ;
VAL_ 263 BrakePedalSwitchNOSts 0 "Not_Active" 1 "Active" ;
VAL_ 263 BrakeTravelFailSts 0 "Fail_Not_Present" 1 "Fail_Present" ;
VAL_ 263 DiskWearLamp 0 "Not_Active" 1 "Active" ;
VAL_ 263 EPB_Pad_Wear 0 "No_Pad_Wear_Warning" 1 "Pad_Wear_Warning" ;
VAL_ 263 Hot_Disk_Warning 0 "Fail_Not_Present" 1 "Fail_Present" ;
VAL_ 263 Reactivation_Warning 0 "Fail_Not_Present" 1 "Fail_Present" ;
VAL_ 259 HillHolderActive 0 "Not_Active" 1 "Active" ;
VAL_ 259 MuSplit 0 "MuSplitOFF" 1 "MuSplitON" 3 "SNA" ;
VAL_ 259 OverSteering 63 "SNA" ;
VAL_ 259 TorqReq_CDCM_Active 0 "Not_Active" 1 "Active" 2 "Suppressed" 3 "SNA" ;
VAL_ 259 TorqueIncrease 0 "Not_Active" 1 "Active" ;
VAL_ 259 TorqueReduct 0 "Not_Active" 1 "Active" ;
VAL_ 259 TorqueRequest 2047 "SNA" ;
VAL_ 259 TorqueRequest_FAST 2047 "SNA" ;
VAL_ 259 UnderSteering 63 "SNA" ;
VAL_ 501 ExternalBrkRequestsDisabled 0 "Enabled" 1 "Diasbled" 2 "Not_Used" 3 "SNA" ;
VAL_ 501 VehicleStandStillSts 0 "True" 1 "False" 3 "SNA" ;
VAL_ 1048 ASRActive 0 "Not_active" 1 "Active" ;
VAL_ 1048 ASRFailSts 0 "Fail_Not_Present" 1 "Fail_Present" ;
VAL_ 1048 MSRActive 0 "Not_Active" 1 "Active" ;
VAL_ 1048 TravelDistance 255 "SNA" ;
VAL_ 1199 ABSCheck 0 "Not_Active" 1 "Active" ;
VAL_ 1199 ABSFailSts 0 "Fail_Not_Present" 1 "Fail_Present" ;
VAL_ 1199 BSM_BLC_Active 0 "Not_Active" 1 "Active" ;
VAL_ 1199 BSMSysSts 0 "Normal mode" 1 "Diagnosis mode" 2 "Alternative mode" 3 "SNA" ;
VAL_ 1199 DSTFailSts 0 "Fail_Not_Present" 1 "Fail_Present" ;
VAL_ 1199 EBDCheck 0 "Not_Active" 1 "Active" ;
VAL_ 1199 EBDFailSts 0 "Fail_Not_Present" 1 "Fail_Present" ;
VAL_ 1199 ERMActive 0 "Not_Active" 1 "Active" ;
VAL_ 1199 ESCCheck 0 "Not_Active" 1 "Active" ;
VAL_ 1199 ESCFailSts 0 "Fail_Not_Present" 1 "Fail_Present" ;
VAL_ 1199 ESCIntervention 0 "No_intervention" 1 "Intervention_blinking_lamp" ;
VAL_ 1199 ESCOFFAvailability 0 "Not_Available" 1 "Available" ;
VAL_ 1199 ESCOFFLamp 0 "Active" 1 "Not_Active" ;
VAL_ 1199 Function2Sts 0 "Not_Active" 1 "Active" ;
VAL_ 1199 FunctionFailSts 0 "Fail_Not_Present" 1 "Fail_Present" ;
VAL_ 1199 FunctionIntervention 0 "No_intervention" 1 "Intervention_blinking_lamp" ;
VAL_ 1199 FunctionSts 0 "Not_Active" 1 "Active" ;
VAL_ 1199 HillHolderFailSts 0 "Fail_not_present" 1 "Fail_present" ;
VAL_ 1199 RollsModeAct 0 "Not_active" 1 "Active" ;
VAL_ 1199 TSCActive 0 "Not_Active" 1 "Active" ;
VAL_ 284 Stabi_Index 8191 "SNA" ;
VAL_ 284 YawRateRef 4095 "SNA" ;
VAL_ 284 YawRateStat 4095 "SNA" ;
VAL_ 254 InternalError_BSM 0 "No_int_processing_error_detected" 1 "Int_processing_error_detected" ;
VAL_ 254 LatAcceleration_BSM 4095 "SNA" ;
VAL_ 254 LatAccelerationFailSts_BSM 0 "Fail_Not_Present" 1 "Fail_Present" ;
VAL_ 254 LongAcceleration_BSM 4095 "SNA" ;
VAL_ 254 LongAccelerationFailSts_BSM 0 "Fail_Not_Present" 1 "Fail_Present" ;
VAL_ 254 Slope 255 "SNA" ;
VAL_ 254 YawRate_BSM 4095 "SNA" ;
VAL_ 254 YawRateFailSts_BSM 0 "Fail_Not_Present" 1 "Fail_Present" ;
VAL_ 750 SteeringColumnTorque 2047 "SNA" ;
VAL_ 280 R_Diff_Mode_Req 0 "No_Request" 1 "Free_Running" 2 "Min_Torque" 3 "Control_Torque" 4 "Max_Torque" 5 "Max_Torque_Fast_Open" 6 "Not_Used" 7 "SNA" ;
VAL_ 601 ElectricSteeringLamp_FailSts 0 "OFF_Fail_not_present" 1 "OFF_Fail_present" 2 "ON_Fail_not_present" 3 "Not_used" ;
VAL_ 598 ABSLamp_FailSts 0 "OFF_Fail_not_present" 1 "OFF_Fail_present" 2 "ON_Fail_not_present" 3 "Not_used" ;
VAL_ 598 AirBagLamp_FailSts 0 "OFF_Fail_not_present" 1 "OFF_Fail_present" 2 "ON_Fail_not_present" 3 "BLINKING_Fail_not_present" ;
VAL_ 598 DistanceUnit 0 "km" 1 "miles" ;
VAL_ 598 EBDLamp_FailSts 0 "OFF_Fail_not_present" 1 "OFF_Fail_present" 2 "ON_Fail_not_present" 3 "Not_used" ;
VAL_ 598 EPBAutoAppReqSts 0 "Not_Request" 1 "AutoApply_Disable" 2 "AutoApply_Enable" 3 "Not_used" ;
VAL_ 598 EPBLamp_FailSts 0 "OFF_Fail_not_present" 1 "OFF_Fail_present" 2 "ON_Fail_not_present" 3 "Not_used" ;
VAL_ 598 EPBMaintenanceReqSts 0 "Not_Request" 1 "Maintenance_Disable" 2 "Maintenance_Enable" 3 "Not_used" ;
VAL_ 598 ESCLamp_FailSts 0 "OFF_Fail_not_present" 1 "OFF_Fail_present" 2 "ON_Fail_not_present" 3 "Not_used" ;
VAL_ 598 HandsFreeEnable 0 "False" 1 "True" ;
VAL_ 598 HHDisablingCommandSts 0 "Enabled" 1 "Disabled" ;
VAL_ 598 PassiveEntry 0 "On" 1 "Off" ;
VAL_ 598 PowerModeSts_IPC 0 "Standard_Power" 1 "Logistic_Mode_ON" 2 "Logistic_Mode_PR" 3 "Not_Used" ;
VAL_ 598 PsngrBagRequestSts 0 "Not_Request" 1 "Enable" 2 "Disable" 3 "Not_Used" ;
VAL_ 598 RemoteDoorUnlock 0 "Driver" 1 "All" ;
VAL_ 598 SpeedLimitActivationIPC 0 "Not_Active" 1 "Active" ;
VAL_ 1422 DriverDoor3AjarRawValSts 0 "Not_Active" 1 "Active" ;
VAL_ 1422 DriverDoor4AjarRawValSts 0 "Not_Active" 1 "Active" ;
VAL_ 1422 DrvDoorLatchDeadLockSts 0 "UnDeadlocked" 1 "Deadlocked" ;
VAL_ 1422 DrvDoorLatchSts 0 "Unlocked" 1 "Locked" ;
VAL_ 1422 E1DriverDoorSts 0 "Closed" 1 "Open" ;
VAL_ 1422 LSMDAjarSensorFailSts 0 "Fail_Not_Present" 1 "Fail_Present" ;
VAL_ 1422 LSMDCrashLineFailSts 0 "Fail_Not_Present" 1 "Fail_Present" ;
VAL_ 1422 LSMDExternalLockReleaseSwitchFai 0 "Fail_Not_Present" 1 "Fail_Present" ;
VAL_ 1422 LSMDFobSearchReq 0 "Not_Active" 1 "Lock_Req" 2 "Release_Req" ;
VAL_ 1422 LSMDInternalFailSts 0 "Fail_Not_Present" 1 "Fail_Present" ;
VAL_ 1422 LSMDInternalLockLightFailSts 0 "Fail_Not_Present" 1 "Fail_Present" ;
VAL_ 1422 LSMDInternalReleaseSwitchFailSts 0 "Fail_Not_Present" 1 "Fail_Present" ;
VAL_ 1422 LSMDInternalUnlockLightFailSts 0 "Fail_Not_Present" 1 "Fail_Present" ;
VAL_ 1422 LSMDReleaseLockReq 0 "Not_Active" 1 "Lock" 2 "Release" ;
VAL_ 1422 LSMDTrunkDisableReq 0 "Not_Active" 1 "Active" ;
VAL_ 1424 E2PsngrDoorSts 0 "Closed" 1 "Open" ;
VAL_ 1424 LSMPAjarSensorFailSts 0 "Fail_Not_Present" 1 "Fail_Present" ;
VAL_ 1424 LSMPCrashLineFailSts 0 "Fail_Not_Present" 1 "Fail_Present" ;
VAL_ 1424 LSMPExternalLockReleaseSwitchFai 0 "Fail_Not_Present" 1 "Fail_Present" ;
VAL_ 1424 LSMPFobSearchReq 0 "Not_Active" 1 "Lock_Req" 2 "Release_Req" 3 "WindowsUp_Req" ;
VAL_ 1424 LSMPInternalFailSts 0 "Fail_Not_Present" 1 "Fail_Present" ;
VAL_ 1424 LSMPInternalLockLightFailSts 0 "Fail_Not_Present" 1 "Fail_Present" ;
VAL_ 1424 LSMPInternalReleaseSwitchFailSts 0 "Fail_Not_Present" 1 "Fail_Present" ;
VAL_ 1424 LSMPInternalUnlockLightFailSts 0 "Fail_Not_Present" 1 "Fail_Present" ;
VAL_ 1424 LSMPReleaseLockReq 0 "Not_Active" 1 "Lock" 2 "Release" ;
VAL_ 1424 LSMPTrunkDisableReq 0 "Not_Active" 1 "Active" ;
VAL_ 1424 PsngrDoorLatchDeadLockSts 0 "UnDeadlocked" 1 "Deadlocked" ;
VAL_ 1424 PsngrDoorLatchSts 0 "Unlocked" 1 "Locked" ;
VAL_ 252 AlternatorFail 0 "Alternator_Fail" 1 "Alternator_Not_In_Fail" ;
VAL_ 252 CC_BrakeIntervention 1023 "SNA" ;
VAL_ 252 CC_BrakeIntervention_Req 0 "Not Active" 1 "Active" ;
VAL_ 252 EngineSpeed 16383 "SNA" ;
VAL_ 252 EngineSpeedFailSts 0 "Fail_not_present" 1 "Fail_present" ;
VAL_ 252 EngineStopStartSts 0 "Engine_Stop" 1 "Engine_Not_in_Stop" 2 "Engine_Stall" 3 "Engine_Stopping" ;
VAL_ 252 EngineSts 0 "Engine_Off" 1 "Engine_Cranking" 2 "Engine_On" 3 "SNA" ;
VAL_ 252 GasPedalPosition 255 "SNA" ;
VAL_ 252 GasPedalPositionFailSts 0 "Fail_not_present" 1 "Fail_present" ;
VAL_ 252 NeutralSwSts 0 "Not_Neutral" 1 "Neutral" 2 "Not_Used" 3 "SNA" ;
VAL_ 252 ReverseGearSts 0 "Not_Inserted" 1 "Inserted" 2 "Not_Used" 3 "SNA" ;
VAL_ 252 StopStartSts 0 "OFF" 1 "ON" 2 "Functional_Disable_Request" 3 "Safety_Disable_Request" ;
VAL_ 1445 CC_SetSpdDspl_KPH 8191 "SNA" ;
VAL_ 1445 CruiseControlLampSts 0 "Not_inserted" 1 "Inserted" ;
VAL_ 1445 CruiseControlSts 0 "Not_inserted" 1 "Inserted" ;
VAL_ 1445 HMIDisplay_CC 0 "ResumeUnavailable_SL" 1 "IncreaseUnavailable_SL" 2 "SetUnavailable_SL" 3 "CC_Unavaulable_HDC" 4 "No_Message" 5 "CC_Cancelled_ESC_OFF" 6 "CC_Unavailable_RAC" 7 "SetUnavailable_ESC_OFF" ;
VAL_ 1445 Override 0 "Not_active" 1 "Active" ;
VAL_ 1202 Bonnet2FailSts 0 "Fail_Not_Present" 1 "Fail_Present" ;
VAL_ 1202 Bonnet2Sts 0 "Closed" 1 "Open" ;
VAL_ 1202 EngineOilPressure 255 "SNA" ;
VAL_ 1202 EngineOilTemp_WarningLight 0 "Not_Active" 1 "Active" ;
VAL_ 1202 PowerModeSts_ECM 0 "Standard_Power" 1 "Logistic_Mode_ON" 2 "Logistic_Mode_PR" 3 "Not_Used" ;
